VERSION ""

NS_ :

BS_:

BU_: PowertrainControlModule AtmosphericSensor SafetyRestraintSystem2 Aftertreatment_2_GasOutlet Aftertreatment_2_GasIntake DieselParticulateFilterControl Turbocharger SafetyRestraintSystem1 CabDisplay2 Aftertreatment_1_GasOutlet Aftertreatment_1_GasIntake OnBoardDataLogger OffBoardDiagnosticTool2 OffBoardDiagnosticTool1 FileServer ParkingBrakeController SeatController2 FanDriveController SteeringColumnUnit CommunicationUnitRadio CommunicationUnitSatellite CommunicationUnitCellular PropulsionBatteryCharger ChassisController2 ChassisController1 EngineValveControl AuxiliaryHeater2 AuxiliaryHeater1 ClutchUnit RampControl InformationSystem1 SuspensionSystemController2 OilSensor VehicleDynamicStability ExhaustEmissionController TransmissionDisplay2 TransmissionDisplay1 ClimateControl2 WaterPumpController RearAxleSteeringController LightingOperatorControl SeatController1 IgnitionController2 IgnitionController1 TirePressureController CabController2 CabController1 PneumaticSystemController SuspensionSystemController1 HydraulicPumpController EnduranceBrakingSystem RetarderExhaustEngine2 OnBoardDiagnosticUnit HeadwayController RetarderExhaustEngine1 CabDisplay1 ManagementComputer VirtualTerminal OffVehicleGateway PowerTakeOffFront HitchControl AuxiliaryValveControl BodyController TractorTrailerBridge1 StarterSystem ElectricalSystem VehicleSecurity VehicleNavigation AerodynamicControl ElectricalChargingSystem ClimateControl1 TripRecorder InstrumentCluster SuspensionDriveAxle2 SuspensionDriveAxle1 SuspensionSteerAxle SteeringController FuelSystem CruiseControl RetarderDriveline RetarderEngine BrakesDriveAxle2 BrakesDriveAxle1 BrakesSystemController BrakesSteerAxle AxleDrive2 AxleDrive1 AxleSteering PowerTakeOff ShiftConsoleSecondary ShiftConsolePrimary Transmission2 Transmission1 Engine2 Engine1

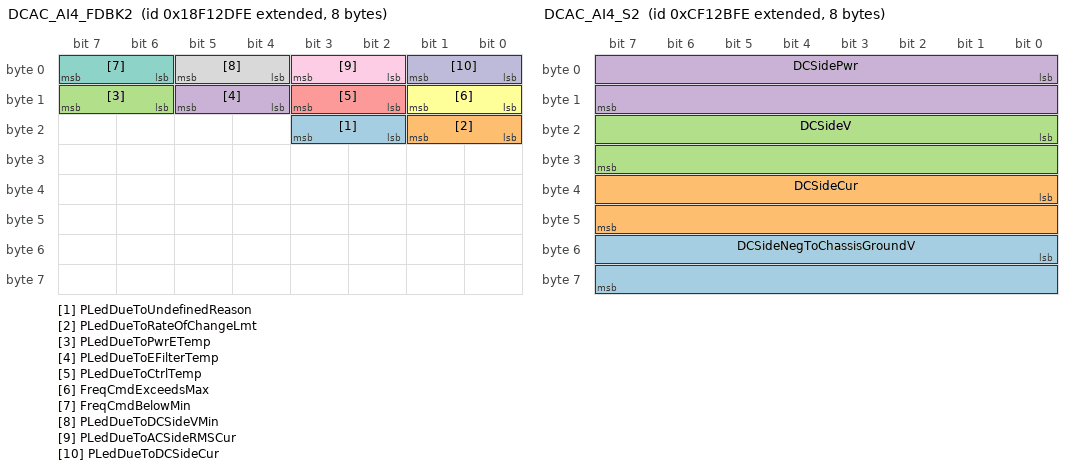
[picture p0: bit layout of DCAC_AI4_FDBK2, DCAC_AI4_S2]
BO_ 2565942782 DCAC_AI4_FDBK2: 8 Vector__XXX
 SG_ PLedDueToUndefinedReason : 18|2@1+ (1,0) [0|3] "" Vector__XXX
 SG_ PLedDueToRateOfChangeLmt : 16|2@1+ (1,0) [0|3] "" Vector__XXX
 SG_ PLedDueToPwrETemp : 14|2@1+ (1,0) [0|3] "" Vector__XXX
 SG_ PLedDueToEFilterTemp : 12|2@1+ (1,0) [0|3] "" Vector__XXX
 SG_ PLedDueToCtrlTemp : 10|2@1+ (1,0) [0|3] "" Vector__XXX
 SG_ FreqCmdExceedsMax : 8|2@1+ (1,0) [0|3] "" Vector__XXX
 SG_ FreqCmdBelowMin : 6|2@1+ (1,0) [0|3] "" Vector__XXX
 SG_ PLedDueToDCSideVMin : 4|2@1+ (1,0) [0|3] "" Vector__XXX
 SG_ PLedDueToACSideRMSCur : 2|2@1+ (1,0) [0|3] "" Vector__XXX
 SG_ PLedDueToDCSideCur : 0|2@1+ (1,0) [0|3] "" Vector__XXX

BO_ 2364615934 DCAC_AI4_V: 8 Vector__XXX
 SG_ SLIV : 16|16@1+ (0.05,0) [0|3212.75] "V" Vector__XXX
 SG_ IgntV : 0|16@1+ (0.05,0) [0|3212.75] "V" Vector__XXX

BO_ 2364615678 DCAC_AI4_S2: 8 Vector__XXX
 SG_ DCSideNegToChassisGroundV : 48|16@1+ (0.05,0) [0|3212.75] "V" Vector__XXX
 SG_ DCSideCur : 32|16@1+ (0.0625,0) [0|4015.9375] "A" Vector__XXX
 SG_ DCSideV : 16|16@1+ (0.05,0) [0|3212.75] "V" Vector__XXX
 SG_ DCSidePwr : 0|16@1+ (0.0625,0) [0|4015.9375] "kW" Vector__XXX

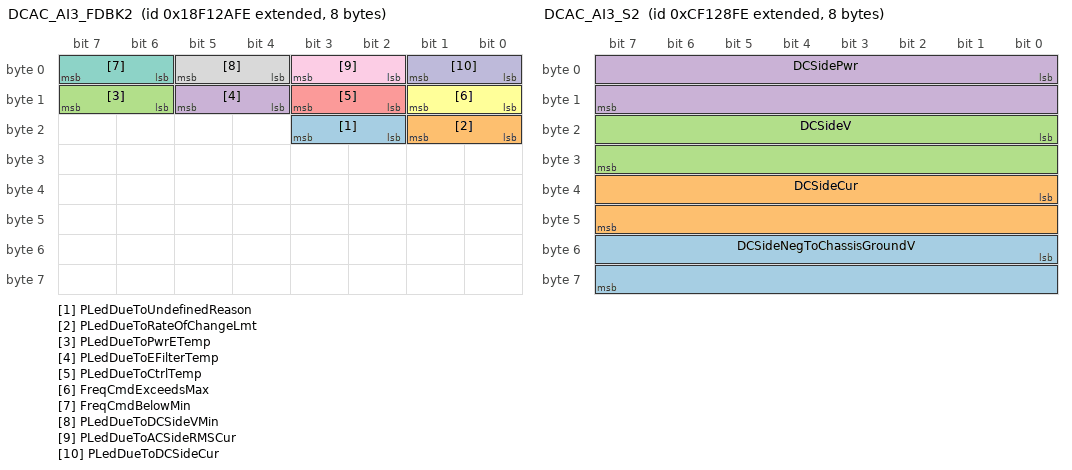
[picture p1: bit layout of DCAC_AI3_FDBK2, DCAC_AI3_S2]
BO_ 2565942014 DCAC_AI3_FDBK2: 8 Vector__XXX
 SG_ PLedDueToUndefinedReason : 18|2@1+ (1,0) [0|3] "" Vector__XXX
 SG_ PLedDueToRateOfChangeLmt : 16|2@1+ (1,0) [0|3] "" Vector__XXX
 SG_ PLedDueToPwrETemp : 14|2@1+ (1,0) [0|3] "" Vector__XXX
 SG_ PLedDueToEFilterTemp : 12|2@1+ (1,0) [0|3] "" Vector__XXX
 SG_ PLedDueToCtrlTemp : 10|2@1+ (1,0) [0|3] "" Vector__XXX
 SG_ FreqCmdExceedsMax : 8|2@1+ (1,0) [0|3] "" Vector__XXX
 SG_ FreqCmdBelowMin : 6|2@1+ (1,0) [0|3] "" Vector__XXX
 SG_ PLedDueToDCSideVMin : 4|2@1+ (1,0) [0|3] "" Vector__XXX
 SG_ PLedDueToACSideRMSCur : 2|2@1+ (1,0) [0|3] "" Vector__XXX
 SG_ PLedDueToDCSideCur : 0|2@1+ (1,0) [0|3] "" Vector__XXX

BO_ 2364615166 DCAC_AI3_V: 8 Vector__XXX
 SG_ SLIV : 16|16@1+ (0.05,0) [0|3212.75] "V" Vector__XXX
 SG_ IgntV : 0|16@1+ (0.05,0) [0|3212.75] "V" Vector__XXX

BO_ 2364614910 DCAC_AI3_S2: 8 Vector__XXX
 SG_ DCSideNegToChassisGroundV : 48|16@1+ (0.05,0) [0|3212.75] "V" Vector__XXX
 SG_ DCSideCur : 32|16@1+ (0.0625,0) [0|4015.9375] "A" Vector__XXX
 SG_ DCSideV : 16|16@1+ (0.05,0) [0|3212.75] "V" Vector__XXX
 SG_ DCSidePwr : 0|16@1+ (0.0625,0) [0|4015.9375] "kW" Vector__XXX

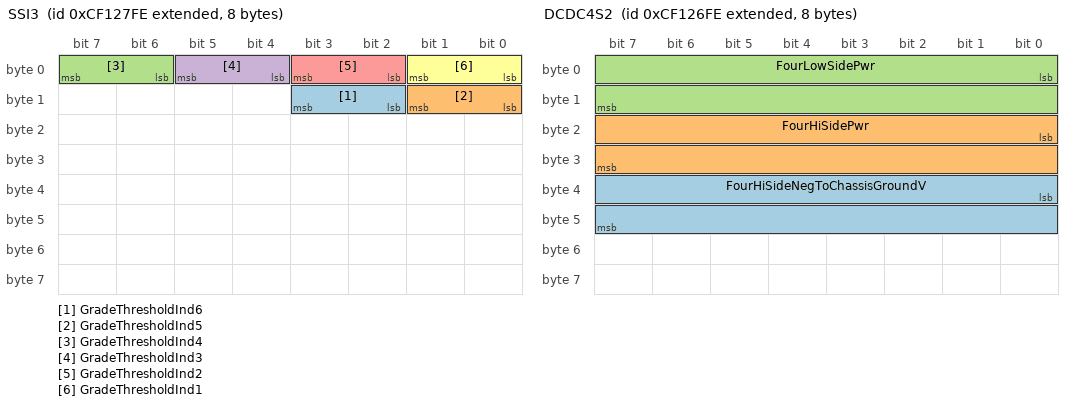
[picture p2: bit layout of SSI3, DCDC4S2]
BO_ 2364614654 SSI3: 8 Vector__XXX
 SG_ GradeThresholdInd6 : 10|2@1+ (1,0) [0|3] "" Vector__XXX
 SG_ GradeThresholdInd5 : 8|2@1+ (1,0) [0|3] "" Vector__XXX
 SG_ GradeThresholdInd4 : 6|2@1+ (1,0) [0|3] "" Vector__XXX
 SG_ GradeThresholdInd3 : 4|2@1+ (1,0) [0|3] "" Vector__XXX
 SG_ GradeThresholdInd2 : 2|2@1+ (1,0) [0|3] "" Vector__XXX
 SG_ GradeThresholdInd1 : 0|2@1+ (1,0) [0|3] "" Vector__XXX

BO_ 2364614398 DCDC4S2: 8 Vector__XXX
 SG_ FourHiSideNegToChassisGroundV : 32|16@1+ (0.05,0) [0|3212.75] "V" Vector__XXX
 SG_ FourHiSidePwr : 16|16@1+ (0.05,-1600) [-1600|1612.75] "kW" Vector__XXX
 SG_ FourLowSidePwr : 0|16@1+ (0.05,-1600) [-1600|1612.75] "kW" Vector__XXX

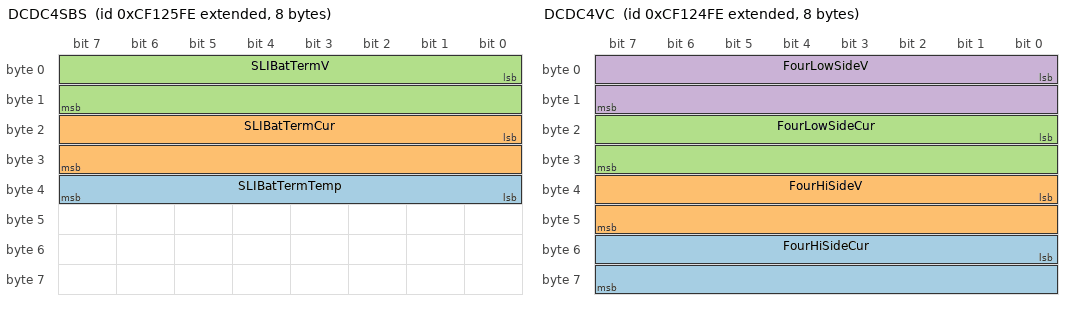
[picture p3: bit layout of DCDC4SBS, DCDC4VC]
BO_ 2364614142 DCDC4SBS: 8 Vector__XXX
 SG_ SLIBatTermTemp : 32|8@1+ (1,-40) [-40|210] "캜" Vector__XXX
 SG_ SLIBatTermCur : 16|16@1+ (0.1,-3212.7) [-3212.7|3212.8] "A" Vector__XXX
 SG_ SLIBatTermV : 0|16@1+ (0.01,0) [0|642.55] "V" Vector__XXX

BO_ 2364613886 DCDC4VC: 8 Vector__XXX
 SG_ FourHiSideCur : 48|16@1+ (0.1,-3212.7) [-3212.7|3212.8] "A" Vector__XXX
 SG_ FourHiSideV : 32|16@1+ (0.05,0) [0|3212.75] "V" Vector__XXX
 SG_ FourLowSideCur : 16|16@1+ (0.1,-3212.7) [-3212.7|3212.8] "A" Vector__XXX
 SG_ FourLowSideV : 0|16@1+ (0.01,0) [0|642.55] "V" Vector__XXX

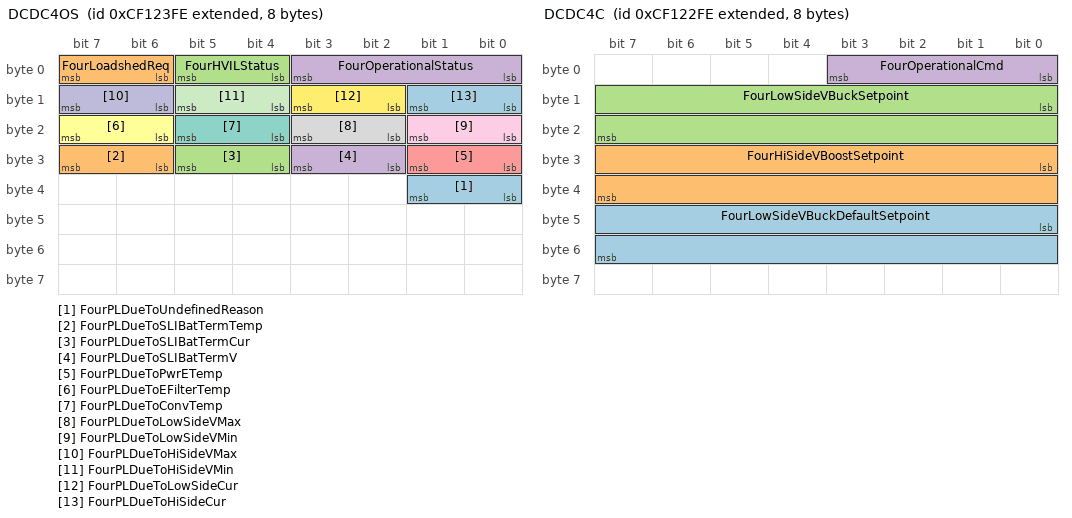
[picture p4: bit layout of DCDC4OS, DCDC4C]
BO_ 2364613630 DCDC4OS: 8 Vector__XXX
 SG_ FourPLDueToUndefinedReason : 32|2@1+ (1,0) [0|3] "" Vector__XXX
 SG_ FourPLDueToSLIBatTermTemp : 30|2@1+ (1,0) [0|3] "" Vector__XXX
 SG_ FourPLDueToSLIBatTermCur : 28|2@1+ (1,0) [0|3] "" Vector__XXX
 SG_ FourPLDueToSLIBatTermV : 26|2@1+ (1,0) [0|3] "" Vector__XXX
 SG_ FourPLDueToPwrETemp : 24|2@1+ (1,0) [0|3] "" Vector__XXX
 SG_ FourPLDueToEFilterTemp : 22|2@1+ (1,0) [0|3] "" Vector__XXX
 SG_ FourPLDueToConvTemp : 20|2@1+ (1,0) [0|3] "" Vector__XXX
 SG_ FourPLDueToLowSideVMax : 18|2@1+ (1,0) [0|3] "" Vector__XXX
 SG_ FourPLDueToLowSideVMin : 16|2@1+ (1,0) [0|3] "" Vector__XXX
 SG_ FourPLDueToHiSideVMax : 14|2@1+ (1,0) [0|3] "" Vector__XXX
 SG_ FourPLDueToHiSideVMin : 12|2@1+ (1,0) [0|3] "" Vector__XXX
 SG_ FourPLDueToLowSideCur : 10|2@1+ (1,0) [0|3] "" Vector__XXX
 SG_ FourPLDueToHiSideCur : 8|2@1+ (1,0) [0|3] "" Vector__XXX
 SG_ FourLoadshedReq : 6|2@1+ (1,0) [0|3] "" Vector__XXX
 SG_ FourHVILStatus : 4|2@1+ (1,0) [0|3] "" Vector__XXX
 SG_ FourOperationalStatus : 0|4@1+ (1,0) [0|15] "" Vector__XXX

BO_ 2364613374 DCDC4C: 8 Vector__XXX
 SG_ FourLowSideVBuckDefaultSetpoint : 40|16@1+ (0.01,0) [0|642.55] "V" Vector__XXX
 SG_ FourHiSideVBoostSetpoint : 24|16@1+ (0.05,0) [0|3212.75] "V" Vector__XXX
 SG_ FourLowSideVBuckSetpoint : 8|16@1+ (0.01,0) [0|642.55] "V" Vector__XXX
 SG_ FourOperationalCmd : 0|4@1+ (1,0) [0|15] "" Vector__XXX

BO_ 2364613118 DCDC3S2: 8 Vector__XXX
 SG_ ThreeHiSideNegToChassisGroundV : 32|16@1+ (0.05,0) [0|3212.75] "V" Vector__XXX
 SG_ ThreeHiSidePwr : 16|16@1+ (0.05,-1600) [-1600|1612.75] "kW" Vector__XXX
 SG_ ThreeLowSidePwr : 0|16@1+ (0.05,-1600) [-1600|1612.75] "kW" Vector__XXX

BO_ 2364612862 DCDC3SBS: 8 Vector__XXX
 SG_ SLIBatTermTemp : 32|8@1+ (1,-40) [-40|210] "캜" Vector__XXX
 SG_ SLIBatTermCur : 16|16@1+ (0.1,-3212.7) [-3212.7|3212.8] "A" Vector__XXX
 SG_ SLIBatTermV : 0|16@1+ (0.01,0) [0|642.55] "V" Vector__XXX

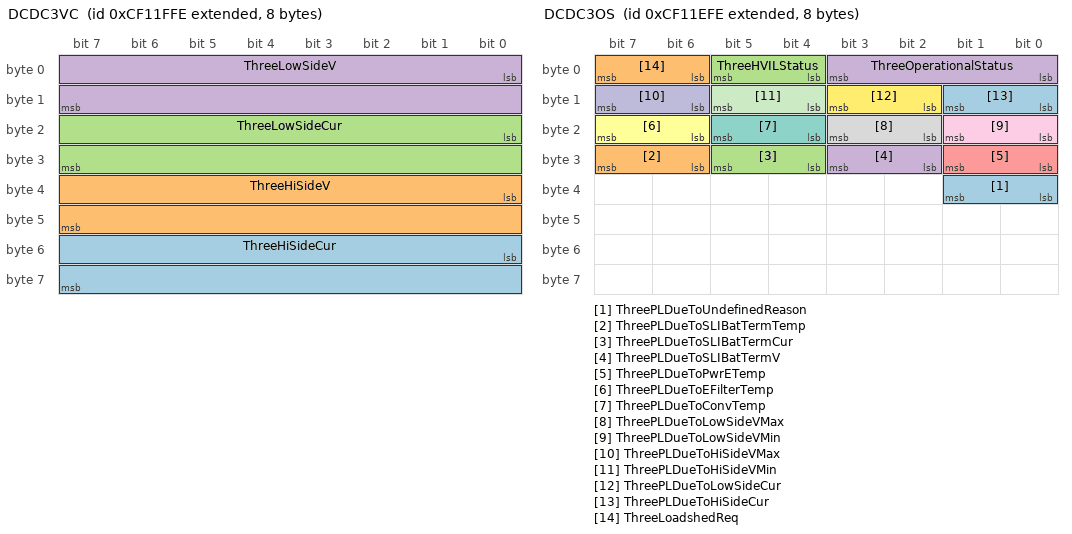
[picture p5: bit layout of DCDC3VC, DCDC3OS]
BO_ 2364612606 DCDC3VC: 8 Vector__XXX
 SG_ ThreeHiSideCur : 48|16@1+ (0.1,-3212.7) [-3212.7|3212.8] "A" Vector__XXX
 SG_ ThreeHiSideV : 32|16@1+ (0.05,0) [0|3212.75] "V" Vector__XXX
 SG_ ThreeLowSideCur : 16|16@1+ (0.1,-3212.7) [-3212.7|3212.8] "A" Vector__XXX
 SG_ ThreeLowSideV : 0|16@1+ (0.01,0) [0|642.55] "V" Vector__XXX

BO_ 2364612350 DCDC3OS: 8 Vector__XXX
 SG_ ThreePLDueToUndefinedReason : 32|2@1+ (1,0) [0|3] "" Vector__XXX
 SG_ ThreePLDueToSLIBatTermTemp : 30|2@1+ (1,0) [0|3] "" Vector__XXX
 SG_ ThreePLDueToSLIBatTermCur : 28|2@1+ (1,0) [0|3] "" Vector__XXX
 SG_ ThreePLDueToSLIBatTermV : 26|2@1+ (1,0) [0|3] "" Vector__XXX
 SG_ ThreePLDueToPwrETemp : 24|2@1+ (1,0) [0|3] "" Vector__XXX
 SG_ ThreePLDueToEFilterTemp : 22|2@1+ (1,0) [0|3] "" Vector__XXX
 SG_ ThreePLDueToConvTemp : 20|2@1+ (1,0) [0|3] "" Vector__XXX
 SG_ ThreePLDueToLowSideVMax : 18|2@1+ (1,0) [0|3] "" Vector__XXX
 SG_ ThreePLDueToLowSideVMin : 16|2@1+ (1,0) [0|3] "" Vector__XXX
 SG_ ThreePLDueToHiSideVMax : 14|2@1+ (1,0) [0|3] "" Vector__XXX
 SG_ ThreePLDueToHiSideVMin : 12|2@1+ (1,0) [0|3] "" Vector__XXX
 SG_ ThreePLDueToLowSideCur : 10|2@1+ (1,0) [0|3] "" Vector__XXX
 SG_ ThreePLDueToHiSideCur : 8|2@1+ (1,0) [0|3] "" Vector__XXX
 SG_ ThreeLoadshedReq : 6|2@1+ (1,0) [0|3] "" Vector__XXX
 SG_ ThreeHVILStatus : 4|2@1+ (1,0) [0|3] "" Vector__XXX
 SG_ ThreeOperationalStatus : 0|4@1+ (1,0) [0|15] "" Vector__XXX

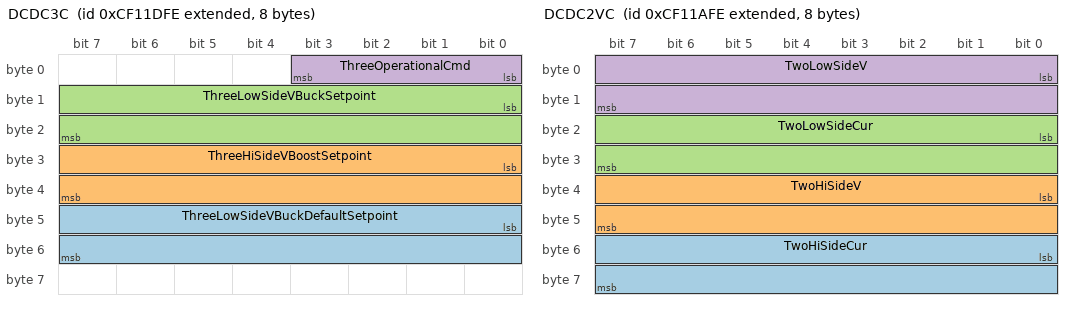
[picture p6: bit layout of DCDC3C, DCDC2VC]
BO_ 2364612094 DCDC3C: 8 Vector__XXX
 SG_ ThreeLowSideVBuckDefaultSetpoint : 40|16@1+ (0.01,0) [0|642.55] "V" Vector__XXX
 SG_ ThreeHiSideVBoostSetpoint : 24|16@1+ (0.05,0) [0|3212.75] "V" Vector__XXX
 SG_ ThreeLowSideVBuckSetpoint : 8|16@1+ (0.01,0) [0|642.55] "V" Vector__XXX
 SG_ ThreeOperationalCmd : 0|4@1+ (1,0) [0|15] "" Vector__XXX

BO_ 2364611838 DCDC2S2: 8 Vector__XXX
 SG_ TwoHiSideNegToChassisGroundV : 32|16@1+ (0.05,0) [0|3212.75] "V" Vector__XXX
 SG_ TwoHiSidePwr : 16|16@1+ (0.05,-1600) [-1600|1612.75] "kW" Vector__XXX
 SG_ TwoLowSidePwr : 0|16@1+ (0.05,-1600) [-1600|1612.75] "kW" Vector__XXX

BO_ 2364611582 DCDC2SBS: 8 Vector__XXX
 SG_ SLIBatTermTemp : 32|8@1+ (1,-40) [-40|210] "캜" Vector__XXX
 SG_ SLIBatTermCur : 16|16@1+ (0.1,-3212.7) [-3212.7|3212.8] "A" Vector__XXX
 SG_ SLIBatTermV : 0|16@1+ (0.01,0) [0|642.55] "V" Vector__XXX

BO_ 2364611326 DCDC2VC: 8 Vector__XXX
 SG_ TwoHiSideCur : 48|16@1+ (0.1,-3212.7) [-3212.7|3212.8] "A" Vector__XXX
 SG_ TwoHiSideV : 32|16@1+ (0.05,0) [0|3212.75] "V" Vector__XXX
 SG_ TwoLowSideCur : 16|16@1+ (0.1,-3212.7) [-3212.7|3212.8] "A" Vector__XXX
 SG_ TwoLowSideV : 0|16@1+ (0.01,0) [0|642.55] "V" Vector__XXX

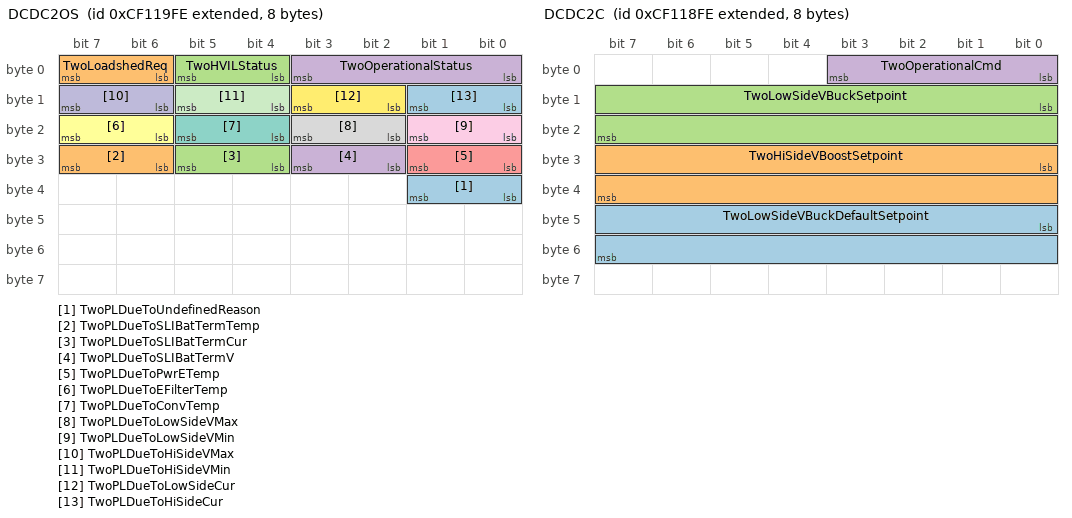
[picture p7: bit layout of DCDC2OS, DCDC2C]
BO_ 2364611070 DCDC2OS: 8 Vector__XXX
 SG_ TwoPLDueToUndefinedReason : 32|2@1+ (1,0) [0|3] "" Vector__XXX
 SG_ TwoPLDueToSLIBatTermTemp : 30|2@1+ (1,0) [0|3] "" Vector__XXX
 SG_ TwoPLDueToSLIBatTermCur : 28|2@1+ (1,0) [0|3] "" Vector__XXX
 SG_ TwoPLDueToSLIBatTermV : 26|2@1+ (1,0) [0|3] "" Vector__XXX
 SG_ TwoPLDueToPwrETemp : 24|2@1+ (1,0) [0|3] "" Vector__XXX
 SG_ TwoPLDueToEFilterTemp : 22|2@1+ (1,0) [0|3] "" Vector__XXX
 SG_ TwoPLDueToConvTemp : 20|2@1+ (1,0) [0|3] "" Vector__XXX
 SG_ TwoPLDueToLowSideVMax : 18|2@1+ (1,0) [0|3] "" Vector__XXX
 SG_ TwoPLDueToLowSideVMin : 16|2@1+ (1,0) [0|3] "" Vector__XXX
 SG_ TwoPLDueToHiSideVMax : 14|2@1+ (1,0) [0|3] "" Vector__XXX
 SG_ TwoPLDueToHiSideVMin : 12|2@1+ (1,0) [0|3] "" Vector__XXX
 SG_ TwoPLDueToLowSideCur : 10|2@1+ (1,0) [0|3] "" Vector__XXX
 SG_ TwoPLDueToHiSideCur : 8|2@1+ (1,0) [0|3] "" Vector__XXX
 SG_ TwoLoadshedReq : 6|2@1+ (1,0) [0|3] "" Vector__XXX
 SG_ TwoHVILStatus : 4|2@1+ (1,0) [0|3] "" Vector__XXX
 SG_ TwoOperationalStatus : 0|4@1+ (1,0) [0|15] "" Vector__XXX

BO_ 2364610814 DCDC2C: 8 Vector__XXX
 SG_ TwoLowSideVBuckDefaultSetpoint : 40|16@1+ (0.01,0) [0|642.55] "V" Vector__XXX
 SG_ TwoHiSideVBoostSetpoint : 24|16@1+ (0.05,0) [0|3212.75] "V" Vector__XXX
 SG_ TwoLowSideVBuckSetpoint : 8|16@1+ (0.01,0) [0|642.55] "V" Vector__XXX
 SG_ TwoOperationalCmd : 0|4@1+ (1,0) [0|15] "" Vector__XXX

BO_ 2364610558 DCDC1S2: 8 Vector__XXX
 SG_ OneHiSideNegToChassisGroundV : 32|16@1+ (0.05,0) [0|3212.75] "V" Vector__XXX
 SG_ OneHiSidePwr : 16|16@1+ (0.05,-1600) [-1600|1612.75] "kW" Vector__XXX
 SG_ OneLowSidePwr : 0|16@1+ (0.05,-1600) [-1600|1612.75] "kW" Vector__XXX

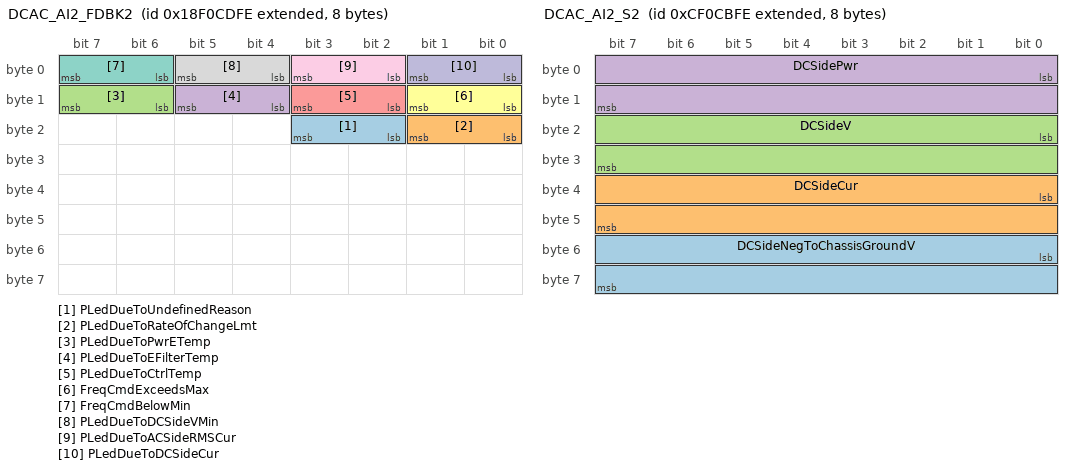
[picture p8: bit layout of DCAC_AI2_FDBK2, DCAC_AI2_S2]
BO_ 2565918206 DCAC_AI2_FDBK2: 8 Vector__XXX
 SG_ PLedDueToUndefinedReason : 18|2@1+ (1,0) [0|3] "" Vector__XXX
 SG_ PLedDueToRateOfChangeLmt : 16|2@1+ (1,0) [0|3] "" Vector__XXX
 SG_ PLedDueToPwrETemp : 14|2@1+ (1,0) [0|3] "" Vector__XXX
 SG_ PLedDueToEFilterTemp : 12|2@1+ (1,0) [0|3] "" Vector__XXX
 SG_ PLedDueToCtrlTemp : 10|2@1+ (1,0) [0|3] "" Vector__XXX
 SG_ FreqCmdExceedsMax : 8|2@1+ (1,0) [0|3] "" Vector__XXX
 SG_ FreqCmdBelowMin : 6|2@1+ (1,0) [0|3] "" Vector__XXX
 SG_ PLedDueToDCSideVMin : 4|2@1+ (1,0) [0|3] "" Vector__XXX
 SG_ PLedDueToACSideRMSCur : 2|2@1+ (1,0) [0|3] "" Vector__XXX
 SG_ PLedDueToDCSideCur : 0|2@1+ (1,0) [0|3] "" Vector__XXX

BO_ 2364591358 DCAC_AI2_V: 8 Vector__XXX
 SG_ SLIV : 16|16@1+ (0.05,0) [0|3212.75] "V" Vector__XXX
 SG_ IgntV : 0|16@1+ (0.05,0) [0|3212.75] "V" Vector__XXX

BO_ 2364591102 DCAC_AI2_S2: 8 Vector__XXX
 SG_ DCSideNegToChassisGroundV : 48|16@1+ (0.05,0) [0|3212.75] "V" Vector__XXX
 SG_ DCSideCur : 32|16@1+ (0.0625,0) [0|4015.9375] "A" Vector__XXX
 SG_ DCSideV : 16|16@1+ (0.05,0) [0|3212.75] "V" Vector__XXX
 SG_ DCSidePwr : 0|16@1+ (0.0625,0) [0|4015.9375] "kW" Vector__XXX

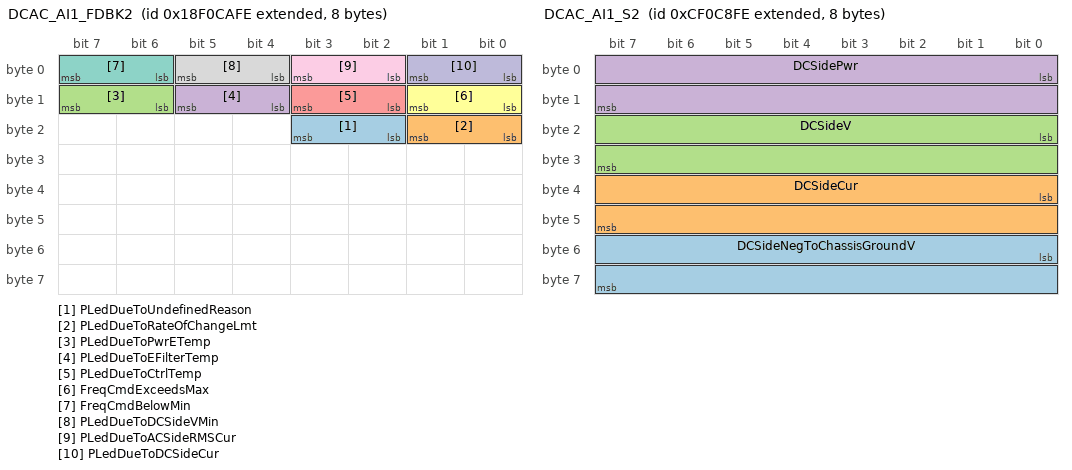
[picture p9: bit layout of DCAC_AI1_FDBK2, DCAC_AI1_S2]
BO_ 2565917438 DCAC_AI1_FDBK2: 8 Vector__XXX
 SG_ PLedDueToUndefinedReason : 18|2@1+ (1,0) [0|3] "" Vector__XXX
 SG_ PLedDueToRateOfChangeLmt : 16|2@1+ (1,0) [0|3] "" Vector__XXX
 SG_ PLedDueToPwrETemp : 14|2@1+ (1,0) [0|3] "" Vector__XXX
 SG_ PLedDueToEFilterTemp : 12|2@1+ (1,0) [0|3] "" Vector__XXX
 SG_ PLedDueToCtrlTemp : 10|2@1+ (1,0) [0|3] "" Vector__XXX
 SG_ FreqCmdExceedsMax : 8|2@1+ (1,0) [0|3] "" Vector__XXX
 SG_ FreqCmdBelowMin : 6|2@1+ (1,0) [0|3] "" Vector__XXX
 SG_ PLedDueToDCSideVMin : 4|2@1+ (1,0) [0|3] "" Vector__XXX
 SG_ PLedDueToACSideRMSCur : 2|2@1+ (1,0) [0|3] "" Vector__XXX
 SG_ PLedDueToDCSideCur : 0|2@1+ (1,0) [0|3] "" Vector__XXX

BO_ 2364590590 DCAC_AI1_V: 8 Vector__XXX
 SG_ SLIV : 16|16@1+ (0.05,0) [0|3212.75] "V" Vector__XXX
 SG_ IgntV : 0|16@1+ (0.05,0) [0|3212.75] "V" Vector__XXX

BO_ 2364590334 DCAC_AI1_S2: 8 Vector__XXX
 SG_ DCSideNegToChassisGroundV : 48|16@1+ (0.05,0) [0|3212.75] "V" Vector__XXX
 SG_ DCSideCur : 32|16@1+ (0.0625,0) [0|4015.9375] "A" Vector__XXX
 SG_ DCSideV : 16|16@1+ (0.05,0) [0|3212.75] "V" Vector__XXX
 SG_ DCSidePwr : 0|16@1+ (0.0625,0) [0|4015.9375] "kW" Vector__XXX

BO_ 2624519934 CRSC: 8 Vector__XXX
 SG_ CommandedReceiveSPNSA : 40|8@1+ (1,0) [0|255] "" Vector__XXX
 SG_ CommandedReceiveSPNReqSt : 32|2@1+ (1,0) [0|3] "" Vector__XXX
 SG_ CommandedReceiveSPN : 16|19@1+ (1,0) [0|524287] "" Vector__XXX
 SG_ TransactionMode : 4|4@1+ (1,0) [0|15] "" Vector__XXX
 SG_ CommandedPort : 0|4@1+ (1,0) [0|15] "" Vector__XXX

BO_ 2557345534 WSPT1: 19 Vector__XXX
 SG_ PlungerFiringOrder : 144|4@1+ (1,0) [0|15] "" Vector__XXX
 SG_ RodLoadHiThreshold : 128|16@1+ (5,0) [0|321275] "kN" Vector__XXX
 SG_ CrankshaftSpdHiThreshold : 112|16@1+ (0.125,0) [0|8031.875] "rpm" Vector__XXX
 SG_ CrankshaftSpdLowThreshold : 96|16@1+ (0.125,0) [0|8031.875] "rpm" Vector__XXX
 SG_ DisPressHiThreshold : 80|16@1+ (5,0) [0|321275] "kPa" Vector__XXX
 SG_ SuctionPressHiThreshold : 64|16@1+ (0.1,-3212.7) [-3212.7|3212.8] "kPa" Vector__XXX
 SG_ SuctionPressLowThreshold : 48|16@1+ (0.1,-3212.7) [-3212.7|3212.8] "kPa" Vector__XXX
 SG_ GearBoxOilTempHiThreshold : 40|8@1+ (1,-40) [-40|210] "캜" Vector__XXX
 SG_ GearBoxOilTempLowThreshold : 32|8@1+ (1,-40) [-40|210] "캜" Vector__XXX
 SG_ GearBoxOilPressHiThreshold : 16|16@1+ (0.1,0) [0|6425.5] "kPa" Vector__XXX
 SG_ GearBoxOilPressLowThreshold : 0|16@1+ (0.1,0) [0|6425.5] "kPa" Vector__XXX

BO_ 2557214462 WSPSCC: 8 Vector__XXX
 SG_ DisPressCalSetPointCmd : 8|4@1+ (1,0) [0|15] "" Vector__XXX
 SG_ SuctionPressCalSetPointCmd : 0|4@1+ (1,0) [0|15] "" Vector__XXX

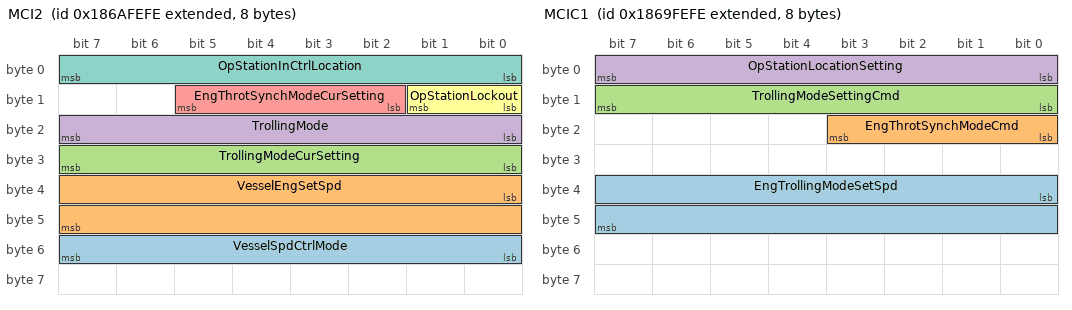
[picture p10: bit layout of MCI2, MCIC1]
BO_ 2557148926 MCI2: 8 Vector__XXX
 SG_ VesselSpdCtrlMode : 48|8@1+ (1,0) [0|255] "" Vector__XXX
 SG_ VesselEngSetSpd : 32|16@1+ (0.125,0) [0|8031.875] "rpm" Vector__XXX
 SG_ TrollingModeCurSetting : 24|8@1+ (1,0) [0|255] "" Vector__XXX
 SG_ TrollingMode : 16|8@1+ (1,0) [0|255] "" Vector__XXX
 SG_ EngThrotSynchModeCurSetting : 10|4@1+ (1,0) [0|15] "" Vector__XXX
 SG_ OpStationLockout : 8|2@1+ (1,0) [0|3] "" Vector__XXX
 SG_ OpStationInCtrlLocation : 0|8@1+ (1,0) [0|250] "" Vector__XXX

BO_ 2557083390 MCIC1: 8 Vector__XXX
 SG_ EngTrollingModeSetSpd : 32|16@1+ (0.125,0) [0|8031.875] "rpm" Vector__XXX
 SG_ EngThrotSynchModeCmd : 16|4@1+ (1,0) [0|15] "" Vector__XXX
 SG_ TrollingModeSettingCmd : 8|8@1+ (1,0) [0|255] "" Vector__XXX
 SG_ OpStationLocationSetting : 0|8@1+ (1,0) [0|250] "" Vector__XXX

BO_ 2633785086 HVES1HIST: 8 Vector__XXX
 SG_ TotalAccumulatedCharge : 56|32@1+ (100,0) [0|421108121500] "Ah" Vector__XXX
 SG_ TotalEnergyThroughput : 24|32@1+ (100,0) [0|421108121500] "Watt-hour" Vector__XXX
 SG_ ContactorOpenUnderLoadCount : 8|16@1+ (1,0) [0|64255] "" Vector__XXX
 SG_ StOfHealth : 0|8@1+ (0.4,0) [0|100] "%" Vector__XXX

BO_ 2566675966 HVES1CFG: 8 Vector__XXX
 SG_ CellMinVLmt : 120|8@1+ (0.02044,0) [0|5.11] "V" Vector__XXX
 SG_ CellMaxVLmt : 112|8@1+ (0.02044,0) [0|5.11] "V" Vector__XXX
 SG_ RecommendedMinOperatingTemp : 96|16@1+ (0.03125,-273) [-273|1734.96875] "캜" Vector__XXX
 SG_ RecommendedMaxOperatingTemp : 80|16@1+ (0.03125,-273) [-273|1734.96875] "캜" Vector__XXX
 SG_ RecommendedMaxStOfCharge : 64|16@1+ (0.0015625,0) [0|100.3984375] "%" Vector__XXX
 SG_ RecommendedMinStOfCharge : 48|16@1+ (0.0015625,0) [0|100.3984375] "%" Vector__XXX
 SG_ RecommendedMaxOperatingV : 32|16@1+ (0.05,0) [0|3212.75] "V" Vector__XXX
 SG_ RecommendedMinOperatingV : 16|16@1+ (0.05,0) [0|3212.75] "V" Vector__XXX
 SG_ NominalV : 0|16@1+ (0.05,0) [0|3212.75] "V" Vector__XXX

BO_ 2566661886 A2DEFI2: 8 Vector__XXX
 SG_ Ctrl2Temp : 8|8@1+ (1,-40) [-40|210] "캜" Vector__XXX
 SG_ CtrlTemp : 0|8@1+ (1,-40) [-40|210] "캜" Vector__XXX

BO_ 2566656254 AMB3: 8 Vector__XXX
 SG_ EngIn2AirTemp : 16|8@1+ (1,-40) [-40|210] "캜" Vector__XXX
 SG_ BarometricAbsPress2 : 0|16@1+ (0.1,0) [0|6425.5] "kPa" Vector__XXX

BO_ 2566655998 SHRPS: 8 Vector__XXX
 SG_ PitchSensitivity : 8|8@1+ (0.4,0) [0|100] "%" Vector__XXX
 SG_ Sensitivity : 0|8@1+ (0.4,0) [0|100] "%" Vector__XXX

BO_ 2566655742 PHRPS: 8 Vector__XXX
 SG_ PitchSensitivity : 8|8@1+ (0.4,0) [0|100] "%" Vector__XXX
 SG_ Sensitivity : 0|8@1+ (0.4,0) [0|100] "%" Vector__XXX

BO_ 2633764350 FPS1: 8 Vector__XXX
 SG_ EngagementCycles : 32|16@1+ (1,0) [0|64255] "" Vector__XXX
 SG_ OpTime : 0|32@1+ (1,0) [0|4211081215] "s" Vector__XXX

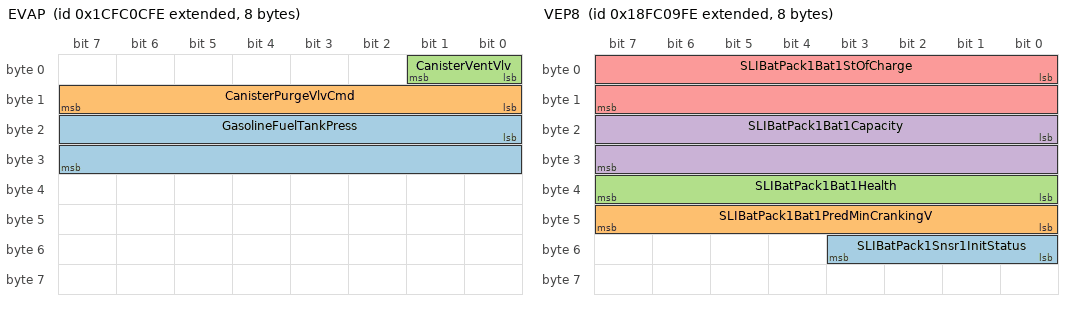
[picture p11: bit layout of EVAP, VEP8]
BO_ 2633764094 EVAP: 8 Vector__XXX
 SG_ GasolineFuelTankPress : 16|16@1+ (0.1,-3212.7) [-3212.7|3212.8] "kPa" Vector__XXX
 SG_ CanisterPurgeVlvCmd : 8|8@1+ (0.4,0) [0|100] "%" Vector__XXX
 SG_ CanisterVentVlv : 0|2@1+ (1,0) [0|3] "" Vector__XXX

BO_ 2566654974 EEC20: 8 Vector__XXX
 SG_ ActualMaxAvailableEngPercentFuel : 16|8@1+ (0.4,0) [0|100] "%" Vector__XXX
 SG_ EstEngParasiticLossesPercentTrq : 0|16@1+ (0.0015625,0) [0|100.3984375] "%" Vector__XXX

BO_ 2566654718 VEP7: 8 Vector__XXX
 SG_ SLIBatPack1Bat1V : 24|16@1+ (0.05,0) [0|3212.75] "V" Vector__XXX
 SG_ SLIBatPack1Bat1Temp : 16|8@1+ (1,-40) [-40|210] "캜" Vector__XXX
 SG_ SLIBatPack1Bat1NetCur : 0|16@1+ (0.05,-1600) [-1600|1612.75] "A" Vector__XXX

BO_ 2566654462 VEP8: 8 Vector__XXX
 SG_ SLIBatPack1Snsr1InitStatus : 48|4@1+ (1,0) [0|15] "" Vector__XXX
 SG_ SLIBatPack1Bat1PredMinCrankingV : 40|8@1+ (0.2,0) [0|50] "V" Vector__XXX
 SG_ SLIBatPack1Bat1Health : 32|8@1+ (0.5,0) [0|125] "%" Vector__XXX
 SG_ SLIBatPack1Bat1Capacity : 16|16@1+ (1,0) [0|64255] "Ah" Vector__XXX
 SG_ SLIBatPack1Bat1StOfCharge : 0|16@1+ (0.0025,0) [0|160.6375] "%" Vector__XXX

BO_ 2566654206 VEP9: 8 Vector__XXX
 SG_ SLIBatPack1Bat2V : 24|16@1+ (0.05,0) [0|3212.75] "V" Vector__XXX
 SG_ SLIBatPack1Bat2Temp : 16|8@1+ (1,-40) [-40|210] "캜" Vector__XXX
 SG_ SLIBatPack1Bat2NetCur : 0|16@1+ (0.05,-1600) [-1600|1612.75] "A" Vector__XXX

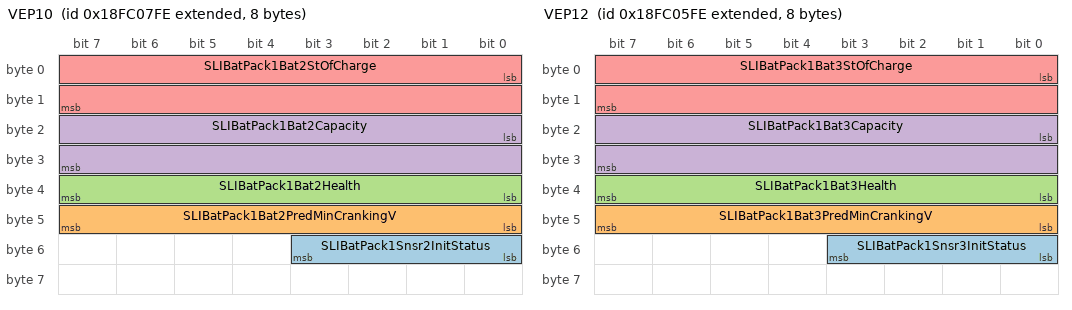
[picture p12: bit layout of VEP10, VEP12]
BO_ 2566653950 VEP10: 8 Vector__XXX
 SG_ SLIBatPack1Snsr2InitStatus : 48|4@1+ (1,0) [0|15] "" Vector__XXX
 SG_ SLIBatPack1Bat2PredMinCrankingV : 40|8@1+ (0.2,0) [0|50] "V" Vector__XXX
 SG_ SLIBatPack1Bat2Health : 32|8@1+ (0.5,0) [0|125] "%" Vector__XXX
 SG_ SLIBatPack1Bat2Capacity : 16|16@1+ (1,0) [0|64255] "Ah" Vector__XXX
 SG_ SLIBatPack1Bat2StOfCharge : 0|16@1+ (0.0025,0) [0|160.6375] "%" Vector__XXX

BO_ 2566653694 VEP11: 8 Vector__XXX
 SG_ SLIBatPack1Bat3V : 24|16@1+ (0.05,0) [0|3212.75] "V" Vector__XXX
 SG_ SLIBatPack1Bat3Temp : 16|8@1+ (1,-40) [-40|210] "캜" Vector__XXX
 SG_ SLIBatPack1Bat3NetCur : 0|16@1+ (0.05,-1600) [-1600|1612.75] "A" Vector__XXX

BO_ 2566653438 VEP12: 8 Vector__XXX
 SG_ SLIBatPack1Snsr3InitStatus : 48|4@1+ (1,0) [0|15] "" Vector__XXX
 SG_ SLIBatPack1Bat3PredMinCrankingV : 40|8@1+ (0.2,0) [0|50] "V" Vector__XXX
 SG_ SLIBatPack1Bat3Health : 32|8@1+ (0.5,0) [0|125] "%" Vector__XXX
 SG_ SLIBatPack1Bat3Capacity : 16|16@1+ (1,0) [0|64255] "Ah" Vector__XXX
 SG_ SLIBatPack1Bat3StOfCharge : 0|16@1+ (0.0025,0) [0|160.6375] "%" Vector__XXX

BO_ 2566653182 VEP13: 8 Vector__XXX
 SG_ SLIBatPack1Bat4V : 24|16@1+ (0.05,0) [0|3212.75] "V" Vector__XXX
 SG_ SLIBatPack1Bat4Temp : 16|8@1+ (1,-40) [-40|210] "캜" Vector__XXX
 SG_ SLIBatPack1Bat4NetCur : 0|16@1+ (0.05,-1600) [-1600|1612.75] "A" Vector__XXX

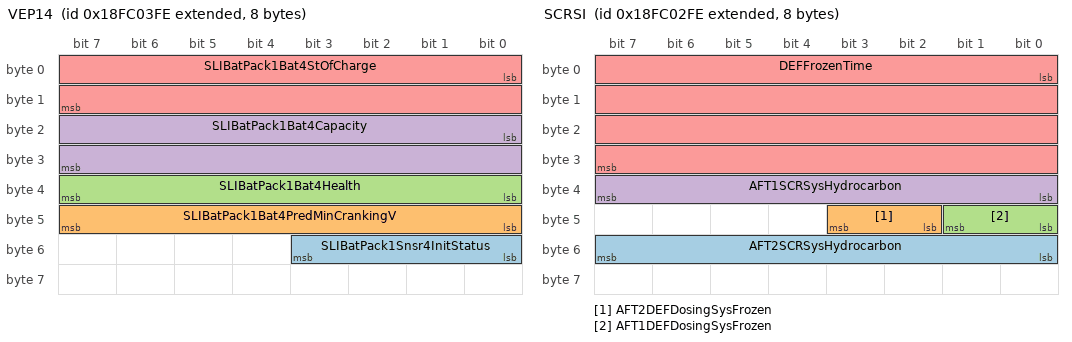
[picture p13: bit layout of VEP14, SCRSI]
BO_ 2566652926 VEP14: 8 Vector__XXX
 SG_ SLIBatPack1Snsr4InitStatus : 48|4@1+ (1,0) [0|15] "" Vector__XXX
 SG_ SLIBatPack1Bat4PredMinCrankingV : 40|8@1+ (0.2,0) [0|50] "V" Vector__XXX
 SG_ SLIBatPack1Bat4Health : 32|8@1+ (0.5,0) [0|125] "%" Vector__XXX
 SG_ SLIBatPack1Bat4Capacity : 16|16@1+ (1,0) [0|64255] "Ah" Vector__XXX
 SG_ SLIBatPack1Bat4StOfCharge : 0|16@1+ (0.0025,0) [0|160.6375] "%" Vector__XXX

BO_ 2566652670 SCRSI: 8 Vector__XXX
 SG_ AFT2SCRSysHydrocarbon : 48|8@1+ (1,0) [0|250] "%" Vector__XXX
 SG_ AFT2DEFDosingSysFrozen : 42|2@1+ (1,0) [0|3] "" Vector__XXX
 SG_ AFT1DEFDosingSysFrozen : 40|2@1+ (1,0) [0|3] "" Vector__XXX
 SG_ AFT1SCRSysHydrocarbon : 32|8@1+ (1,0) [0|250] "%" Vector__XXX
 SG_ DEFFrozenTime : 0|32@1+ (1,0) [0|4211081215] "s" Vector__XXX

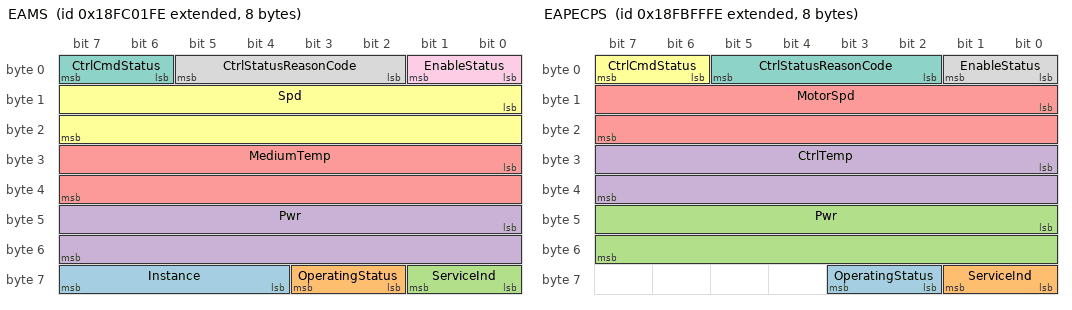
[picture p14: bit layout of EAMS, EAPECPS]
BO_ 2566652414 EAMS: 8 Vector__XXX
 SG_ Instance : 60|4@1+ (1,0) [0|15] "" Vector__XXX
 SG_ OperatingStatus : 58|2@1+ (1,0) [0|3] "" Vector__XXX
 SG_ ServiceInd : 56|2@1+ (1,0) [0|3] "" Vector__XXX
 SG_ Pwr : 40|16@1+ (0.5,0) [0|32127.5] "W" Vector__XXX
 SG_ MediumTemp : 24|16@1+ (0.03125,-273) [-273|1734.96875] "캜" Vector__XXX
 SG_ Spd : 8|16@1+ (0.5,0) [0|32127.5] "rpm" Vector__XXX
 SG_ CtrlCmdStatus : 6|2@1+ (1,0) [0|3] "" Vector__XXX
 SG_ CtrlStatusReasonCode : 2|4@1+ (1,0) [0|15] "" Vector__XXX
 SG_ EnableStatus : 0|2@1+ (1,0) [0|3] "" Vector__XXX

BO_ 2566651902 EAPECPS: 8 Vector__XXX
 SG_ OperatingStatus : 58|2@1+ (1,0) [0|3] "" Vector__XXX
 SG_ ServiceInd : 56|2@1+ (1,0) [0|3] "" Vector__XXX
 SG_ Pwr : 40|16@1+ (0.5,0) [0|32127.5] "W" Vector__XXX
 SG_ CtrlTemp : 24|16@1+ (0.03125,-273) [-273|1734.96875] "캜" Vector__XXX
 SG_ MotorSpd : 8|16@1+ (0.5,0) [0|32127.5] "rpm" Vector__XXX
 SG_ CtrlCmdStatus : 6|2@1+ (1,0) [0|3] "" Vector__XXX
 SG_ CtrlStatusReasonCode : 2|4@1+ (1,0) [0|15] "" Vector__XXX
 SG_ EnableStatus : 0|2@1+ (1,0) [0|3] "" Vector__XXX

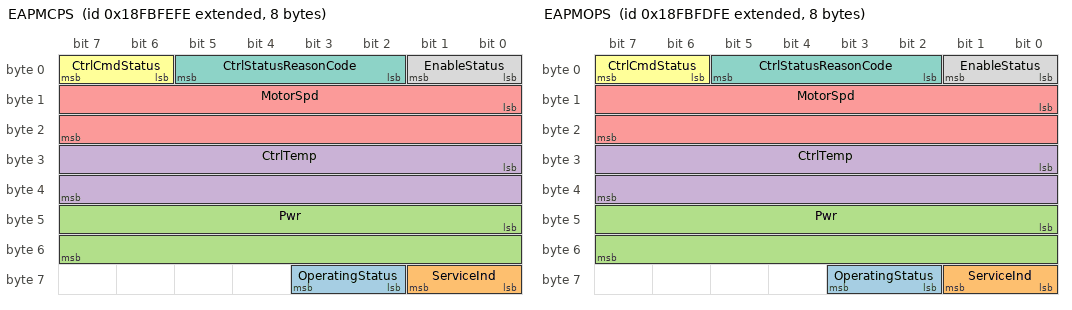
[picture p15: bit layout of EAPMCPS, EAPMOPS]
BO_ 2566651646 EAPMCPS: 8 Vector__XXX
 SG_ OperatingStatus : 58|2@1+ (1,0) [0|3] "" Vector__XXX
 SG_ ServiceInd : 56|2@1+ (1,0) [0|3] "" Vector__XXX
 SG_ Pwr : 40|16@1+ (0.5,0) [0|32127.5] "W" Vector__XXX
 SG_ CtrlTemp : 24|16@1+ (0.03125,-273) [-273|1734.96875] "캜" Vector__XXX
 SG_ MotorSpd : 8|16@1+ (0.5,0) [0|32127.5] "rpm" Vector__XXX
 SG_ CtrlCmdStatus : 6|2@1+ (1,0) [0|3] "" Vector__XXX
 SG_ CtrlStatusReasonCode : 2|4@1+ (1,0) [0|15] "" Vector__XXX
 SG_ EnableStatus : 0|2@1+ (1,0) [0|3] "" Vector__XXX

BO_ 2566651390 EAPMOPS: 8 Vector__XXX
 SG_ OperatingStatus : 58|2@1+ (1,0) [0|3] "" Vector__XXX
 SG_ ServiceInd : 56|2@1+ (1,0) [0|3] "" Vector__XXX
 SG_ Pwr : 40|16@1+ (0.5,0) [0|32127.5] "W" Vector__XXX
 SG_ CtrlTemp : 24|16@1+ (0.03125,-273) [-273|1734.96875] "캜" Vector__XXX
 SG_ MotorSpd : 8|16@1+ (0.5,0) [0|32127.5] "rpm" Vector__XXX
 SG_ CtrlCmdStatus : 6|2@1+ (1,0) [0|3] "" Vector__XXX
 SG_ CtrlStatusReasonCode : 2|4@1+ (1,0) [0|15] "" Vector__XXX
 SG_ EnableStatus : 0|2@1+ (1,0) [0|3] "" Vector__XXX

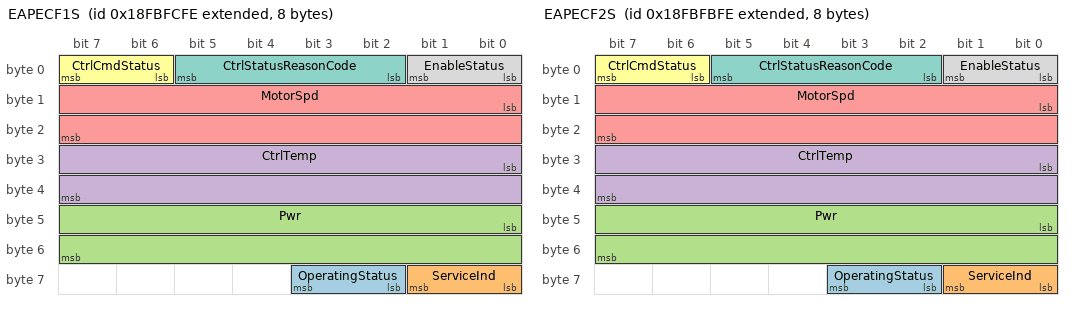
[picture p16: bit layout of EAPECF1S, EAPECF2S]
BO_ 2566651134 EAPECF1S: 8 Vector__XXX
 SG_ OperatingStatus : 58|2@1+ (1,0) [0|3] "" Vector__XXX
 SG_ ServiceInd : 56|2@1+ (1,0) [0|3] "" Vector__XXX
 SG_ Pwr : 40|16@1+ (0.5,0) [0|32127.5] "W" Vector__XXX
 SG_ CtrlTemp : 24|16@1+ (0.03125,-273) [-273|1734.96875] "캜" Vector__XXX
 SG_ MotorSpd : 8|16@1+ (0.5,0) [0|32127.5] "rpm" Vector__XXX
 SG_ CtrlCmdStatus : 6|2@1+ (1,0) [0|3] "" Vector__XXX
 SG_ CtrlStatusReasonCode : 2|4@1+ (1,0) [0|15] "" Vector__XXX
 SG_ EnableStatus : 0|2@1+ (1,0) [0|3] "" Vector__XXX

BO_ 2566650878 EAPECF2S: 8 Vector__XXX
 SG_ OperatingStatus : 58|2@1+ (1,0) [0|3] "" Vector__XXX
 SG_ ServiceInd : 56|2@1+ (1,0) [0|3] "" Vector__XXX
 SG_ Pwr : 40|16@1+ (0.5,0) [0|32127.5] "W" Vector__XXX
 SG_ CtrlTemp : 24|16@1+ (0.03125,-273) [-273|1734.96875] "캜" Vector__XXX
 SG_ MotorSpd : 8|16@1+ (0.5,0) [0|32127.5] "rpm" Vector__XXX
 SG_ CtrlCmdStatus : 6|2@1+ (1,0) [0|3] "" Vector__XXX
 SG_ CtrlStatusReasonCode : 2|4@1+ (1,0) [0|15] "" Vector__XXX
 SG_ EnableStatus : 0|2@1+ (1,0) [0|3] "" Vector__XXX

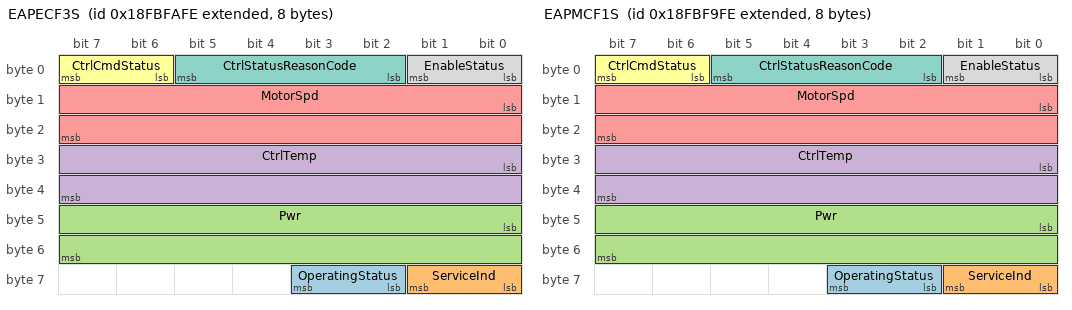
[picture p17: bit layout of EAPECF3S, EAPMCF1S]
BO_ 2566650622 EAPECF3S: 8 Vector__XXX
 SG_ OperatingStatus : 58|2@1+ (1,0) [0|3] "" Vector__XXX
 SG_ ServiceInd : 56|2@1+ (1,0) [0|3] "" Vector__XXX
 SG_ Pwr : 40|16@1+ (0.5,0) [0|32127.5] "W" Vector__XXX
 SG_ CtrlTemp : 24|16@1+ (0.03125,-273) [-273|1734.96875] "캜" Vector__XXX
 SG_ MotorSpd : 8|16@1+ (0.5,0) [0|32127.5] "rpm" Vector__XXX
 SG_ CtrlCmdStatus : 6|2@1+ (1,0) [0|3] "" Vector__XXX
 SG_ CtrlStatusReasonCode : 2|4@1+ (1,0) [0|15] "" Vector__XXX
 SG_ EnableStatus : 0|2@1+ (1,0) [0|3] "" Vector__XXX

BO_ 2566650366 EAPMCF1S: 8 Vector__XXX
 SG_ OperatingStatus : 58|2@1+ (1,0) [0|3] "" Vector__XXX
 SG_ ServiceInd : 56|2@1+ (1,0) [0|3] "" Vector__XXX
 SG_ Pwr : 40|16@1+ (0.5,0) [0|32127.5] "W" Vector__XXX
 SG_ CtrlTemp : 24|16@1+ (0.03125,-273) [-273|1734.96875] "캜" Vector__XXX
 SG_ MotorSpd : 8|16@1+ (0.5,0) [0|32127.5] "rpm" Vector__XXX
 SG_ CtrlCmdStatus : 6|2@1+ (1,0) [0|3] "" Vector__XXX
 SG_ CtrlStatusReasonCode : 2|4@1+ (1,0) [0|15] "" Vector__XXX
 SG_ EnableStatus : 0|2@1+ (1,0) [0|3] "" Vector__XXX

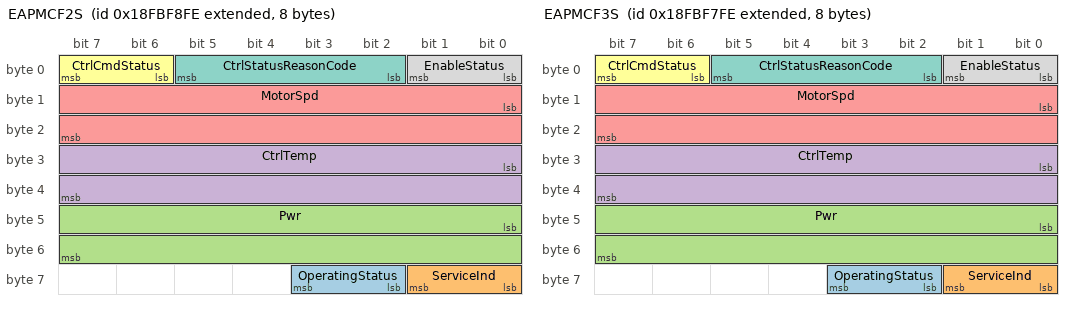
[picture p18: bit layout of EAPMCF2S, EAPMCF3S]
BO_ 2566650110 EAPMCF2S: 8 Vector__XXX
 SG_ OperatingStatus : 58|2@1+ (1,0) [0|3] "" Vector__XXX
 SG_ ServiceInd : 56|2@1+ (1,0) [0|3] "" Vector__XXX
 SG_ Pwr : 40|16@1+ (0.5,0) [0|32127.5] "W" Vector__XXX
 SG_ CtrlTemp : 24|16@1+ (0.03125,-273) [-273|1734.96875] "캜" Vector__XXX
 SG_ MotorSpd : 8|16@1+ (0.5,0) [0|32127.5] "rpm" Vector__XXX
 SG_ CtrlCmdStatus : 6|2@1+ (1,0) [0|3] "" Vector__XXX
 SG_ CtrlStatusReasonCode : 2|4@1+ (1,0) [0|15] "" Vector__XXX
 SG_ EnableStatus : 0|2@1+ (1,0) [0|3] "" Vector__XXX

BO_ 2566649854 EAPMCF3S: 8 Vector__XXX
 SG_ OperatingStatus : 58|2@1+ (1,0) [0|3] "" Vector__XXX
 SG_ ServiceInd : 56|2@1+ (1,0) [0|3] "" Vector__XXX
 SG_ Pwr : 40|16@1+ (0.5,0) [0|32127.5] "W" Vector__XXX
 SG_ CtrlTemp : 24|16@1+ (0.03125,-273) [-273|1734.96875] "캜" Vector__XXX
 SG_ MotorSpd : 8|16@1+ (0.5,0) [0|32127.5] "rpm" Vector__XXX
 SG_ CtrlCmdStatus : 6|2@1+ (1,0) [0|3] "" Vector__XXX
 SG_ CtrlStatusReasonCode : 2|4@1+ (1,0) [0|15] "" Vector__XXX
 SG_ EnableStatus : 0|2@1+ (1,0) [0|3] "" Vector__XXX

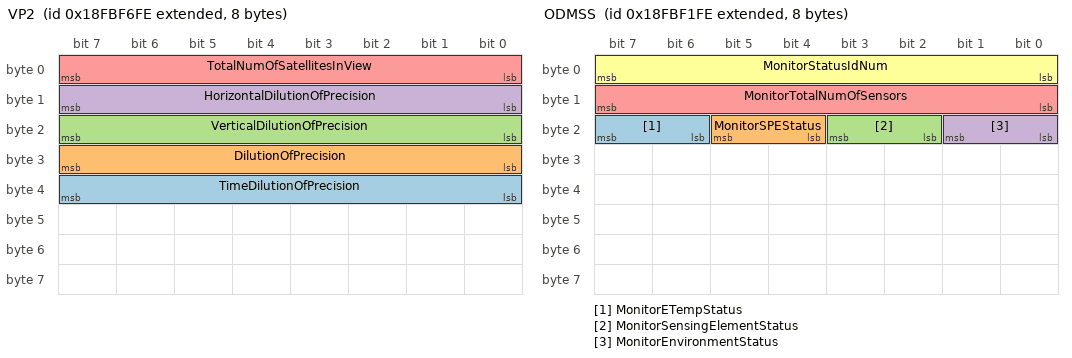
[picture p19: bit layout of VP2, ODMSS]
BO_ 2566649598 VP2: 8 Vector__XXX
 SG_ TimeDilutionOfPrecision : 32|8@1+ (0.1,0) [0|25] "" Vector__XXX
 SG_ DilutionOfPrecision : 24|8@1+ (0.1,0) [0|25] "" Vector__XXX
 SG_ VerticalDilutionOfPrecision : 16|8@1+ (0.1,0) [0|25] "" Vector__XXX
 SG_ HorizontalDilutionOfPrecision : 8|8@1+ (0.1,0) [0|25] "" Vector__XXX
 SG_ TotalNumOfSatellitesInView : 0|8@1+ (1,0) [0|250] "" Vector__XXX

BO_ 2566649342 A1DOC2: 8 Vector__XXX
 SG_ DOCInToDPFOutDeltaPress : 32|16@1+ (0.1,0) [0|6425.5] "kPa" Vector__XXX
 SG_ OutPress : 16|16@1+ (0.1,0) [0|6425.5] "kPa" Vector__XXX
 SG_ InPress : 0|16@1+ (0.1,0) [0|6425.5] "kPa" Vector__XXX

BO_ 2566649086 A2DOC2: 8 Vector__XXX
 SG_ DOCInToDPFOutDeltaPress : 32|16@1+ (0.1,0) [0|6425.5] "kPa" Vector__XXX
 SG_ OutPress : 16|16@1+ (0.1,0) [0|6425.5] "kPa" Vector__XXX
 SG_ InPress : 0|16@1+ (0.1,0) [0|6425.5] "kPa" Vector__XXX

BO_ 2365322238 CCVS5: 8 Vector__XXX
 SG_ DirVS : 0|16@1+ (0.0078125,-250) [-250|251.992] "km/h" Vector__XXX

BO_ 2566648318 ODMSS: 8 Vector__XXX
 SG_ MonitorETempStatus : 22|2@1+ (1,0) [0|3] "" Vector__XXX
 SG_ MonitorSPEStatus : 20|2@1+ (1,0) [0|3] "" Vector__XXX
 SG_ MonitorSensingElementStatus : 18|2@1+ (1,0) [0|3] "" Vector__XXX
 SG_ MonitorEnvironmentStatus : 16|2@1+ (1,0) [0|3] "" Vector__XXX
 SG_ MonitorTotalNumOfSensors : 8|8@1+ (1,0) [0|250] "" Vector__XXX
 SG_ MonitorStatusIdNum : 0|8@1+ (1,0) [0|250] "" Vector__XXX

BO_ 2566648062 ODMCNF5_6: 8 Vector__XXX
 SG_ NFBin6Count : 32|24@1+ (1,0) [0|16449535] "" Vector__XXX
 SG_ NFBin5Count : 8|24@1+ (1,0) [0|16449535] "" Vector__XXX
 SG_ NFBins5And6IdNum : 0|8@1+ (1,0) [0|250] "" Vector__XXX

BO_ 2566647806 ODMCNF3_4: 8 Vector__XXX
 SG_ NFBin4Count : 32|24@1+ (1,0) [0|16449535] "" Vector__XXX
 SG_ NFBin3Count : 8|24@1+ (1,0) [0|16449535] "" Vector__XXX
 SG_ NFBins3And4IdNum : 0|8@1+ (1,0) [0|250] "" Vector__XXX

CM_ BO_ 2565942782 "DC/AC Accessory Inverter 4 Feedback 2
Sent by this Accessory Inverter instance and contains the current operating conditions of this output of the inverter.  This message would be received by a controller application (e.g. Power System Manager) ...";
CM_ SG_ 2565942782 PLedDueToUndefinedReason "Output power is being limited due to an undefined reason.

00 - No power limit for this reason
01 - Power limited for this reason
10 - Error
11 - Not Available";
CM_ SG_ 2565942782 PLedDueToRateOfChangeLmt "Output power is being limited due to the frequency approaching or exceeding the rate of change limit (see SPN 8374).

00 - No frequency limit for this reason
01 - Frequency limited for this reason
10 - Error
11 - Not Available";
CM_ SG_ 2565942782 PLedDueToPwrETemp "Output power is being limited due to power electronics temperature (see SPN 9293) approaching or exceeding the maximum limit.

00 - No frequency limit for this reason
01 - Frequency limited for this reason
10 - Error
11 - Not Available";
CM_ SG_ 2565942782 PLedDueToEFilterTemp "Output power is being limited due to electronic filter temperature (see SPN 9292) approaching or exceeding the maximum limit.

00 - No frequency limit for this reason
01 - Frequency limited for this reason
10 - Error
11 - Not Available";
CM_ SG_ 2565942782 PLedDueToCtrlTemp "Output power is being limited due to the controller temperature (see SPN 9291) approaching or exceeding the maximum limit.

00 - No power limit for this reason
01 - Power limited for this reason
10 - Error
11 - Not Available";
CM_ SG_ 2565942782 FreqCmdExceedsMax "Output frequency is being limited due to frequency command (see SPN 8375) approaching or exceeding the maximum limit (SPN 8370).

00 - No frequency limit for this reason
01 - Frequency limited for this reason
10 - Error
11 - Not Available";
CM_ SG_ 2565942782 FreqCmdBelowMin "Output frequency is being limited due to frequency command (see SPN 8375) approaching or falling below the minimum limit (SPN 8371).

00 - No frequency limit for this reason
01 - Frequency limited for this reason
10 - Error
11 - Not Available";
CM_ SG_ 2565942782 PLedDueToDCSideVMin "Output power is being limited due to DC Side input voltage (see SPN 9297) approaching or falling below the minimum limit (SPN 9315).

00 - No power limit for this reason
01 - Power limited for this reason
10 - Error
11 - Not Available";
CM_ SG_ 2565942782 PLedDueToACSideRMSCur "AC Side Output power is being limited due to AC Side output RMS current (see SPN 9203) approaching or exceeding the maximum limit (See SPN 9318).
00 - No power limit for this reason
01 - Power limited for this reason
10 - Error
11 - Not ...";
CM_ SG_ 2565942782 PLedDueToDCSideCur "Output power is being limited due to DC Side input current (see SPN 9298) approaching or exceeding the maximum limit (See SPN 9316).

00 - No power limit for this reason
01 - Power limited for this reason
10 - Error
11 - Not Available";
CM_ BO_ 2364615934 "DC/AC Accessory Inverter 4 Voltage
Low Voltage data from DC/AC Accessory Inverter.";
CM_ SG_ 2364615934 SLIV "Low voltage (SLI) supplied to the DC/AC Accessory Inverter controller.";
CM_ SG_ 2364615934 IgntV "Ignition voltage supplied to the  DC/AC Accessory Inverter controller.";
CM_ BO_ 2364615678 "DC/AC Accessory Inverter 4 Status 2
Additional data reported from DC/AC Accessory Inverter";
CM_ SG_ 2364615678 DCSideNegToChassisGroundV "The voltage level of the high voltage DC side, as measured by the DC/AC between the negative side of the High Voltage DC Side input and the chassis of the DC/AC enclosure.  This voltage can be used for system level monitoring of DC Side High Voltage ...";
CM_ SG_ 2364615678 DCSideCur "DC Side input current measured at the point of control inside the DC/AC Accessory Inverter.";
CM_ SG_ 2364615678 DCSideV "DC Side input voltage measured at the point of control inside the DC/AC Accessory Inverter.";
CM_ SG_ 2364615678 DCSidePwr "Power measured at the DC Side input to the DC/AC Accessory Inverter.";
CM_ BO_ 2565942014 "DC/AC Accessory Inverter 3 Feedback 2
Sent by this Accessory Inverter instance and contains the current operating conditions of this output of the inverter.  This message would be received by a controller application (e.g. Power System Manager) ...";
CM_ SG_ 2565942014 PLedDueToUndefinedReason "Output power is being limited due to an undefined reason.

00 - No power limit for this reason
01 - Power limited for this reason
10 - Error
11 - Not Available";
CM_ SG_ 2565942014 PLedDueToRateOfChangeLmt "Output power is being limited due to the frequency approaching or exceeding the rate of change limit (see SPN 8360).

00 - No frequency limit for this reason
01 - Frequency limited for this reason
10 - Error
11 - Not Available";
CM_ SG_ 2565942014 PLedDueToPwrETemp "Output power is being limited due to power electronics temperature (see SPN 9263) approaching or exceeding the maximum limit.

00 - No frequency limit for this reason
01 - Frequency limited for this reason
10 - Error
11 - Not Available";
CM_ SG_ 2565942014 PLedDueToEFilterTemp "Output power is being limited due to electronic filter temperature (see SPN 9262) approaching or exceeding the maximum limit.

00 - No frequency limit for this reason
01 - Frequency limited for this reason
10 - Error
11 - Not Available";
CM_ SG_ 2565942014 PLedDueToCtrlTemp "Output power is being limited due to the controller temperature (see SPN 9261) approaching or exceeding the maximum limit.

00 - No power limit for this reason
01 -  Power limited for this reason
10 - Error
11 - Not Available";
CM_ SG_ 2565942014 FreqCmdExceedsMax "Output frequency is being limited due to frequency command (see SPN 8361) approaching or exceeding the maximum limit (SPN 8356).

00 - No frequency limit for this reason
01 - Frequency limited for this reason
10 - Error
11 - Not Available";
CM_ SG_ 2565942014 FreqCmdBelowMin "Output frequency is being limited due to frequency command (see SPN 8361) approaching or falling below the minimum limit (SPN 8357).

00 - No frequency limit for this reason
01 - Frequency limited for this reason
10 - Error
11 - Not Available";
CM_ SG_ 2565942014 PLedDueToDCSideVMin "Output power is being limited due to DC Side input voltage (see SPN 9267) approaching or falling below the minimum limit  (SPN 9285).

00 - No power limit for this reason
01 - Power limited for this reason
10 - Error
11 - Not Available";
CM_ SG_ 2565942014 PLedDueToACSideRMSCur "AC Side Output power is being limited due to AC Side output RMS current (see SPN 9202) approaching or exceeding the maximum limit (See SPN 9288).
00 - No power limit for this reason
01 - Power limited for this reason
10 - Error
11 - Not ...";
CM_ SG_ 2565942014 PLedDueToDCSideCur "Output power is being limited due to DC Side input current (see SPN 9268) approaching or exceeding the maximum limit (See SPN 9286).

00 - No power limit for this reason
01 - Power limited for this reason
10 - Error
11 - Not Available";
CM_ BO_ 2364615166 "DC/AC Accessory Inverter 3 Voltage
Low Voltage data from DC/AC Accessory Inverter.";
CM_ SG_ 2364615166 SLIV "Low voltage (SLI) supplied to the DC/AC Accessory Inverter controller.";
CM_ SG_ 2364615166 IgntV "Ignition voltage supplied to the  DC/AC Accessory Inverter controller.";
CM_ BO_ 2364614910 "DC/AC Accessory Inverter 3 Status 2
Additional data reported from DC/AC Accessory Inverter";
CM_ SG_ 2364614910 DCSideNegToChassisGroundV "The voltage level of the high voltage DC side, as measured by the DC/AC between the negative side of the High Voltage DC Side input and the chassis of the DC/AC enclosure.  This voltage can be used for system level monitoring of DC Side High Voltage ...";
CM_ SG_ 2364614910 DCSideCur "DC Side input current measured at the point of control inside the DC/AC Accessory Inverter.";
CM_ SG_ 2364614910 DCSideV "DC Side input voltage measured at the point of control inside the DC/AC Accessory Inverter.";
CM_ SG_ 2364614910 DCSidePwr "Power measured at the DC Side input to the DC/AC Accessory Inverter.";
CM_ BO_ 2364614654 "Slope Sensor Information 3
Provides additional grade or slope data.";
CM_ SG_ 2364614654 GradeThresholdInd6 "This parameter indicates whether or not the transmitting device has sensed a vehicle grade equal to or exceeding a manufacturer-defined threshold. The manufacturer-defined threshold could be a simple fixed value or a dynamic value that changes based ...";
CM_ SG_ 2364614654 GradeThresholdInd5 "This parameter indicates whether or not the transmitting device has sensed a vehicle grade equal to or exceeding a manufacturer-defined threshold. The manufacturer-defined threshold could be a simple fixed value or a dynamic value that changes based ...";
CM_ SG_ 2364614654 GradeThresholdInd4 "This parameter indicates whether or not the transmitting device has sensed a vehicle grade equal to or exceeding a manufacturer-defined threshold. The manufacturer-defined threshold could be a simple fixed value or a dynamic value that changes based ...";
CM_ SG_ 2364614654 GradeThresholdInd3 "This parameter indicates whether or not the transmitting device has sensed a vehicle grade equal to or exceeding a manufacturer-defined threshold. The manufacturer-defined threshold could be a simple fixed value or a dynamic value that changes based ...";
CM_ SG_ 2364614654 GradeThresholdInd2 "This parameter indicates whether or not the transmitting device has sensed a vehicle grade equal to or exceeding a manufacturer-defined threshold. The manufacturer-defined threshold could be a simple fixed value or a dynamic value that changes based ...";
CM_ SG_ 2364614654 GradeThresholdInd1 "This parameter indicates whether or not the transmitting device has sensed a vehicle grade equal to or exceeding a manufacturer-defined threshold. The manufacturer-defined threshold could be a simple fixed value or a dynamic value that changes based ...";
CM_ BO_ 2364614398 "DC/DC Converter 4 Status 2
Additional data reported from a DC/DC Converter";
CM_ SG_ 2364614398 FourHiSideNegToChassisGroundV "The voltage level of the high voltage DC side, as measured by the DC/DC between the negative side of the High Voltage DC Side input and the chassis of the DC/DC enclosure.  This voltage can be used for system level monitoring of DC Side High Voltage ...";
CM_ SG_ 2364614398 FourHiSidePwr "Indicates the measured HVES or high side power measured at the DC/DC Converter.  The high side power is positive if the converter is charging the hybrid battery from the SLI battery (i.e. Boost Mode).  The high side power is negative if the ...";
CM_ SG_ 2364614398 FourLowSidePwr "Indicates the measured SLI battery or low side power measured at the DC/DC Converter.  The low side power is positive if the converter is charging the SLI battery from the hybrid battery (i.e. Buck Mode).  The low side power is negative if the ...";
CM_ BO_ 2364614142 "DC/DC Converter 4 SLI Battery Status
Status of the SLI battery measured at the SLI battery terminals.

One intended use of this message is for a conventional engine mounted alternator replacement.";
CM_ SG_ 2364614142 SLIBatTermTemp "Parameter indicating the SLI battery terminal temperature for control use by the DC/DC converter.";
CM_ SG_ 2364614142 SLIBatTermCur "Parameter indicating the SLI battery terminal current for control use by the DC/DC converter.  The current is positive if the SLI battery or low side voltage source is being charged from the HVES.";
CM_ SG_ 2364614142 SLIBatTermV "Parameter indicating the SLI battery terminal voltage for control use by the DC/DC converter.";
CM_ BO_ 2364613886 "DC/DC Converter 4 Voltage and Current
Voltage and current data from a DC/DC Converter.

One intended use of this message is for a conventional engine mounted alternator replacement.";
CM_ SG_ 2364613886 FourHiSideCur "Indicates the measured HVES or high side current measured at the point of control inside the DC/DC Converter.  The current is negative if the converter is charging the SLI battery from the hybrid battery.";
CM_ SG_ 2364613886 FourHiSideV "Indicates the measured HVES or high side voltage measured at the point of control inside the DC/DC Converter.";
CM_ SG_ 2364613886 FourLowSideCur "Indicates the measured SLI battery or low side current measured at the point of control inside the DC/DC Converter.  The current is positive if the converter is charging the SLI battery from the hybrid battery.";
CM_ SG_ 2364613886 FourLowSideV "Indicates the measured SLI battery or low side voltage measured at the point of control inside the DC/DC Converter.";
CM_ BO_ 2364613630 "DC/DC Converter 4 Operating Status
Contains information on the operating status of a DC/DC Converter.

One intended use of this message is for a conventional engine mounted alternator replacement.";
CM_ SG_ 2364613630 FourPLDueToUndefinedReason "Indicates whether or not output power is being limited due to an undefined reason.

00 - No power limit for this reason
01 - Power limited for this reason
10 - Error
11 - Not Available";
CM_ SG_ 2364613630 FourPLDueToSLIBatTermTemp "Indicates whether or not output power is being limited due to the SLI battery terminal temperature (see SPN 9027) approaching or exceeding limits (see SPN 9045).
00 - No power limit for this reason
01 - Power limited for this reason
10 - Error
 ...";
CM_ SG_ 2364613630 FourPLDueToSLIBatTermCur "Indicates whether or not output power is being limited due to the SLI battery terminal current (see SPN 9026) approaching or exceeding limits (see SPN 9044).
00 - No power limit for this reason
01 - Power limited for this reason
10 - Error
11 - ...";
CM_ SG_ 2364613630 FourPLDueToSLIBatTermV "Indicates whether or not output power is being limited due to the SLI battery terminal voltage (see SPN 9025) approaching or exceeding limits (see SPN 9043).
00 - No power limit for this reason
01 - Power limited for this reason
10 - Error
11 - ...";
CM_ SG_ 2364613630 FourPLDueToPwrETemp "Indicates whether or not output power is being limited due to Power Electronics Temperature (see SPN 9048) approaching or exceeding the maximum limit.
00 - No power limit for this reason
01 - Power limited for this reason
10 - Error
11 - Not ...";
CM_ SG_ 2364613630 FourPLDueToEFilterTemp "Indicates whether or not output power is being limited due to Output Electronic Filter Temperature (see SPN 9047) approaching or exceeding the maximum limit.
00 - No power limit for this reason
01 - Power limited for this reason
10 - Error
11 - ...";
CM_ SG_ 2364613630 FourPLDueToConvTemp "Indicates whether or not output power is being limited due to Converter Temperature (see SPN 9046) approaching or exceeding the maximum limit.

00 - No power limit for this reason
01 - Power limited for this reason
10 - Error
11 - Not Available";
CM_ SG_ 2364613630 FourPLDueToLowSideVMax "Indicates whether or not output power is being limited due to low side voltage (see SPN 9021) approaching or exceeding the maximum limit (see SPN 9052).
00 - No power limit for this reason
01 - Power limited for this reason
10 - Error
11 - Not ...";
CM_ SG_ 2364613630 FourPLDueToLowSideVMin "Indicates whether or not output power is being limited due to low side voltage (see SPN 9021) approaching or falling below the minimum limit (see SPN 9051).
00 - No power limit for this reason
01 - Power limited for this reason
10 - Error
11 - ...";
CM_ SG_ 2364613630 FourPLDueToHiSideVMax "Indicates whether or not output power is being limited due to high side voltage (see SPN 9023) approaching or exceeding the maximum limit (see SPN 9055).
00 - No power limit for this reason
01 - Power limited for this reason
10 - Error
11 - Not ...";
CM_ SG_ 2364613630 FourPLDueToHiSideVMin "Indicates whether or not output power is being limited due to high side voltage (see SPN 9023) approaching or falling below the minimum limit (see SPN 9054).
00 - No power limit for this reason
01 - Power limited for this reason
10 - Error
11 - ...";
CM_ SG_ 2364613630 FourPLDueToLowSideCur "Indicates whether or not output power is being limited due to low side current (see SPN 9022) approaching or exceeding the maximum limit (see SPN 9053).
00 - No power limit for this reason
01 - Power limited for this reason
10 - Error
11 - Not ...";
CM_ SG_ 2364613630 FourPLDueToHiSideCur "Indicates whether or not output power is being limited due to high side current (see SPN 9024) approaching or exceeding the maximum limit (see SPN 9056).
00 - No power limit for this reason
01 - Power limited for this reason
10 - Error
11 - Not ...";
CM_ SG_ 2364613630 FourLoadshedReq "The loadshed request is a request to the controlling device to reduce the DC/DC Converter loads.  The Loadshed Requested state is an indication that this DC/DC Converter has a malfunction or is in a limit condition and if the load of the output is ...";
CM_ SG_ 2364613630 FourHVILStatus "High Voltage Interlock Loop (HVIL) state of the DC/DC Converter.

00 - HVIL Closed
01 - HVIL Open
10 - Error
11 - Not Available";
CM_ SG_ 2364613630 FourOperationalStatus "Operating state of the DC/DC Converter
0000 - Disabled
0001 - Initialization in process.  The device is powering up.  This process may include both internal checks, as well as system checks being run by the DC/DC Converter.
0010 - Operational - ...";
CM_ BO_ 2364613374 "DC/DC Converter 4 Control
Controls the transfer of energy between the HVES or high voltage system (i.e. high side) and the SLI battery or low voltage system (i.e. low side).  Provides a function to either charge the SLI Battery from the HVES (Buck) ...";
CM_ SG_ 2364613374 FourLowSideVBuckDefaultSetpoint "The set point for the converter default low side voltage during buck mode.   This setting may be used for when communication has been lost with the controlling device.  When set to Not Available (FFFFh), no default setting is provided and the system ...";
CM_ SG_ 2364613374 FourHiSideVBoostSetpoint "The set point for regulating the high side voltage during boost mode.";
CM_ SG_ 2364613374 FourLowSideVBuckSetpoint "The set point for regulating the low side voltage during buck mode.";
CM_ SG_ 2364613374 FourOperationalCmd "Command to enable or disable operation.
0000 - Disable - in this mode all high voltage switching is disabled
0001 - Operate in standby mode; system is waiting for command to enter buck or boost mode
0010 - Operate in buck mode; energy flows from ...";
CM_ BO_ 2364613118 "DC/DC Converter 3 Status 2
Additional data reported from a DC/DC Converter";
CM_ SG_ 2364613118 ThreeHiSideNegToChassisGroundV "The voltage level of the high voltage DC side, as measured by the DC/DC between the negative side of the High Voltage DC Side input and the chassis of the DC/DC enclosure.  This voltage can be used for system level monitoring of DC Side High Voltage ...";
CM_ SG_ 2364613118 ThreeHiSidePwr "Indicates the measured HVES or high side power measured at the DC/DC Converter.  The high side power is positive if the converter is charging the hybrid battery from the SLI battery (i.e. Boost Mode).  The high side power is negative if the ...";
CM_ SG_ 2364613118 ThreeLowSidePwr "Indicates the measured SLI battery or low side power measured at the DC/DC Converter.  The low side power is positive if the converter is charging the SLI battery from the hybrid battery (i.e. Buck Mode).  The low side power is negative if the ...";
CM_ BO_ 2364612862 "DC/DC Converter 3 SLI Battery Status
Status of the SLI battery measured at the SLI battery terminals.

One intended use of this message is for a conventional engine mounted alternator replacement.";
CM_ SG_ 2364612862 SLIBatTermTemp "Parameter indicating the SLI battery terminal temperature for control use by the DC/DC converter.";
CM_ SG_ 2364612862 SLIBatTermCur "Parameter indicating the SLI battery terminal current for control use by the DC/DC converter.  The current is positive if the SLI battery or low side voltage source is being charged from the HVES.";
CM_ SG_ 2364612862 SLIBatTermV "Parameter indicating the SLI battery terminal voltage for control use by the DC/DC converter.";
CM_ BO_ 2364612606 "DC/DC Converter 3 Voltage and Current
Voltage and current data from a DC/DC Converter.

One intended use of this message is for a conventional engine mounted alternator replacement.";
CM_ SG_ 2364612606 ThreeHiSideCur "Indicates the measured HVES or high side current measured at the point of control inside the DC/DC Converter.  The current is negative if the converter is charging the SLI battery from the hybrid battery.";
CM_ SG_ 2364612606 ThreeHiSideV "Indicates the measured HVES or high side voltage measured at the point of control inside the DC/DC Converter.";
CM_ SG_ 2364612606 ThreeLowSideCur "Indicates the measured SLI battery or low side current measured at the point of control inside the DC/DC Converter.  The current is positive if the converter is charging the SLI battery from the hybrid battery.";
CM_ SG_ 2364612606 ThreeLowSideV "Indicates the measured SLI battery or low side voltage measured at the point of control inside the DC/DC Converter.";
CM_ BO_ 2364612350 "DC/DC Converter 3 Operating Status
Contains information on the operating status of a DC/DC Converter.

One intended use of this message is for a conventional engine mounted alternator replacement.";
CM_ SG_ 2364612350 ThreePLDueToUndefinedReason "Indicates whether or not output power is being limited due to an undefined reason.

00 - No power limit for this reason
01 - Power limited for this reason
10 - Error
11 - Not Available";
CM_ SG_ 2364612350 ThreePLDueToSLIBatTermTemp "Indicates whether or not output power is being limited due to the SLI battery terminal temperature (see SPN 8972) approaching or exceeding limits (see SPN 8990).
00 - No power limit for this reason
01 - Power limited for this reason
10 - Error
 ...";
CM_ SG_ 2364612350 ThreePLDueToSLIBatTermCur "Indicates whether or not output power is being limited due to the SLI battery terminal current (see SPN 8971) approaching or exceeding limits (see SPN 8989).
00 - No power limit for this reason
01 - Power limited for this reason
10 - Error
11 - ...";
CM_ SG_ 2364612350 ThreePLDueToSLIBatTermV "Indicates whether or not output power is being limited due to the SLI battery terminal voltage (see SPN 8970) approaching or exceeding limits (see SPN 8988).
00 - No power limit for this reason
01 - Power limited for this reason
10 - Error
11 - ...";
CM_ SG_ 2364612350 ThreePLDueToPwrETemp "Indicates whether or not output power is being limited due to Power Electronics Temperature (see SPN 8993) approaching or exceeding the maximum limit.
00 - No power limit for this reason
01 - Power limited for this reason
10 - Error
11 - Not ...";
CM_ SG_ 2364612350 ThreePLDueToEFilterTemp "Indicates whether or not output power is being limited due to Output Electronic Filter Temperature (see SPN 8992) approaching or exceeding the maximum limit.
00 - No power limit for this reason
01 - Power limited for this reason
10 - Error
11 - ...";
CM_ SG_ 2364612350 ThreePLDueToConvTemp "Indicates whether or not output power is being limited due to Converter Temperature (see SPN 8991) approaching or exceeding the maximum limit.

00 - No power limit for this reason
01 - Power limited for this reason
10 - Error
11 - Not Available";
CM_ SG_ 2364612350 ThreePLDueToLowSideVMax "Indicates whether or not output power is being limited due to low side voltage (see SPN 8966) approaching or exceeding the maximum limit (see SPN 8997).
00 - No power limit for this reason
01 - Power limited for this reason
10 - Error
11 - Not ...";
CM_ SG_ 2364612350 ThreePLDueToLowSideVMin "Indicates whether or not output power is being limited due to low side voltage (see SPN 8966) approaching or falling below the minimum limit (see SPN 8996).
00 - No power limit for this reason
01 - Power limited for this reason
10 - Error
11 - ...";
CM_ SG_ 2364612350 ThreePLDueToHiSideVMax "Indicates whether or not output power is being limited due to high side voltage (see SPN 8968) approaching or exceeding the maximum limit (see SPN 9000).
00 - No power limit for this reason
01 - Power limited for this reason
10 - Error
11 - Not ...";
CM_ SG_ 2364612350 ThreePLDueToHiSideVMin "Indicates whether or not output power is being limited due to high side voltage (see SPN 8968) approaching or falling below the minimum limit (see SPN 8999).
00 - No power limit for this reason
01 - Power limited for this reason
10 - Error
11 - ...";
CM_ SG_ 2364612350 ThreePLDueToLowSideCur "Indicates whether or not output power is being limited due to low side current (see SPN 8967) approaching or exceeding the maximum limit (see SPN 8998).
00 - No power limit for this reason
01 - Power limited for this reason
10 - Error
11 - Not ...";
CM_ SG_ 2364612350 ThreePLDueToHiSideCur "Indicates whether or not output power is being limited due to high side current (see SPN 8969) approaching or exceeding the maximum limit (see SPN 9001).
00 - No power limit for this reason
01 - Power limited for this reason
10 - Error
11 - Not ...";
CM_ SG_ 2364612350 ThreeLoadshedReq "The loadshed request is a request to the controlling device to reduce the DC/DC Converter loads.  The Loadshed Requested state is an indication that this DC/DC Converter has a malfunction or is in a limit condition and if the load of the output is ...";
CM_ SG_ 2364612350 ThreeHVILStatus "High Voltage Interlock Loop (HVIL) state of the DC/DC Converter.

00 - HVIL Closed
01 - HVIL Open
10 - Error
11 - Not Available";
CM_ SG_ 2364612350 ThreeOperationalStatus "Operating state of the DC/DC Converter
0000 - Disabled
0001 - Initialization in process.  The device is powering up.  This process may include both internal checks, as well as system checks being run by the DC/DC Converter.
0010 - Operational - ...";
CM_ BO_ 2364612094 "DC/DC Converter 3 Control
Controls the transfer of energy between the HVES or high voltage system (i.e. high side) and the SLI battery or low voltage system (i.e. low side).  Provides a function to either charge the SLI Battery from the HVES (Buck) ...";
CM_ SG_ 2364612094 ThreeLowSideVBuckDefaultSetpoint "The set point for the converter default low side voltage during buck mode.   This setting may be used for when communication has been lost with the controlling device.  When set to Not Available (FFFFh), no default setting is provided and the system ...";
CM_ SG_ 2364612094 ThreeHiSideVBoostSetpoint "The set point for regulating the high side voltage during boost mode.";
CM_ SG_ 2364612094 ThreeLowSideVBuckSetpoint "The set point for regulating the low side voltage during buck mode.";
CM_ SG_ 2364612094 ThreeOperationalCmd "Command to enable or disable operation.
0000 - Disable - in this mode all high voltage switching is disabled
0001 - Operate in standby mode; system is waiting for command to enter buck or boost mode
0010 - Operate in buck mode; energy flows from ...";
CM_ BO_ 2364611838 "DC/DC Converter 2 Status 2
Additional data reported from a DC/DC Converter";
CM_ SG_ 2364611838 TwoHiSideNegToChassisGroundV "The voltage level of the high voltage DC side, as measured by the DC/DC between the negative side of the High Voltage DC Side input and the chassis of the DC/DC enclosure.  This voltage can be used for system level monitoring of DC Side High Voltage ...";
CM_ SG_ 2364611838 TwoHiSidePwr "Indicates the measured HVES or high side power measured at the DC/DC Converter.  The high side power is positive if the converter is charging the hybrid battery from the SLI battery (i.e. Boost Mode).  The high side power is negative if the ...";
CM_ SG_ 2364611838 TwoLowSidePwr "Indicates the measured SLI battery or low side power measured at the DC/DC Converter.  The low side power is positive if the converter is charging the SLI battery from the hybrid battery (i.e. Buck Mode).  The low side power is negative if the ...";
CM_ BO_ 2364611582 "DC/DC Converter 2 SLI Battery Status
Status of the SLI battery measured at the SLI battery terminals.

One intended use of this message is for a conventional engine mounted alternator replacement.";
CM_ SG_ 2364611582 SLIBatTermTemp "Parameter indicating the SLI battery terminal temperature for control use by the DC/DC converter.";
CM_ SG_ 2364611582 SLIBatTermCur "Parameter indicating the SLI battery terminal current for control use by the DC/DC converter.  The current is positive if the SLI battery or low side voltage source is being charged from the HVES.";
CM_ SG_ 2364611582 SLIBatTermV "Parameter indicating the SLI battery terminal voltage for control use by the DC/DC converter.";
CM_ BO_ 2364611326 "DC/DC Converter 2 Voltage and Current
Voltage and current data from a DC/DC Converter.

One intended use of this message is for a conventional engine mounted alternator replacement.";
CM_ SG_ 2364611326 TwoHiSideCur "Indicates the measured HVES or high side current measured at the point of control inside the DC/DC Converter.  The current is negative if the converter is charging the SLI battery from the hybrid battery.";
CM_ SG_ 2364611326 TwoHiSideV "Indicates the measured HVES or high side voltage measured at the point of control inside the DC/DC Converter.";
CM_ SG_ 2364611326 TwoLowSideCur "Indicates the measured SLI battery or low side current measured at the point of control inside the DC/DC Converter.  The current is positive if the converter is charging the SLI battery from the hybrid battery.";
CM_ SG_ 2364611326 TwoLowSideV "Indicates the measured SLI battery or low side voltage measured at the point of control inside the DC/DC Converter.";
CM_ BO_ 2364611070 "DC/DC Converter 2 Operating Status
Contains information on the operating status of a DC/DC Converter.

One intended use of this message is for a conventional engine mounted alternator replacement.";
CM_ SG_ 2364611070 TwoPLDueToUndefinedReason "Indicates whether or not output power is being limited due to an undefined reason.

00 - No power limit for this reason
01 - Power limited for this reason
10 - Error
11 - Not Available";
CM_ SG_ 2364611070 TwoPLDueToSLIBatTermTemp "Indicates whether or not output power is being limited due to the SLI battery terminal temperature (see SPN 8917) approaching or exceeding limits (see SPN 8935).
00 - No power limit for this reason
01 - Power limited for this reason
10 - Error
 ...";
CM_ SG_ 2364611070 TwoPLDueToSLIBatTermCur "Indicates whether or not output power is being limited due to the SLI battery terminal current (see SPN 8916) approaching or exceeding limits (see SPN 8934).
00 - No power limit for this reason
01 - Power limited for this reason
10 - Error
11 - ...";
CM_ SG_ 2364611070 TwoPLDueToSLIBatTermV "Indicates whether or not output power is being limited due to the SLI battery terminal voltage (see SPN 8915) approaching or exceeding limits (see SPN 8933).
00 - No power limit for this reason
01 - Power limited for this reason
10 - Error
11 - ...";
CM_ SG_ 2364611070 TwoPLDueToPwrETemp "Indicates whether or not output power is being limited due to Power Electronics Temperature (see SPN 8938) approaching or exceeding the maximum limit.
00 - No power limit for this reason
01 - Power limited for this reason
10 - Error
11 - Not ...";
CM_ SG_ 2364611070 TwoPLDueToEFilterTemp "Indicates whether or not output power is being limited due to Output Electronic Filter Temperature (see SPN 8937) approaching or exceeding the maximum limit.
00 - No power limit for this reason
01 - Power limited for this reason
10 - Error
11 - ...";
CM_ SG_ 2364611070 TwoPLDueToConvTemp "Indicates whether or not output power is being limited due to Converter Temperature (see SPN 8936) approaching or exceeding the maximum limit.

00 - No power limit for this reason
01 - Power limited for this reason
10 - Error
11 - Not Available";
CM_ SG_ 2364611070 TwoPLDueToLowSideVMax "Indicates whether or not output power is being limited due to low side voltage (see SPN 8911) approaching or exceeding the maximum limit (see SPN 8942).
00 - No power limit for this reason
01 - Power limited for this reason
10 - Error
11 - Not ...";
CM_ SG_ 2364611070 TwoPLDueToLowSideVMin "Indicates whether or not output power is being limited due to low side voltage (see SPN 8911) approaching or falling below the minimum limit (see SPN 8941).
00 - No power limit for this reason
01 - Power limited for this reason
10 - Error
11 - ...";
CM_ SG_ 2364611070 TwoPLDueToHiSideVMax "Indicates whether or not output power is being limited due to high side voltage (see SPN 8913) approaching or exceeding the maximum limit (see SPN 8945).
00 - No power limit for this reason
01 - Power limited for this reason
10 - Error
11 - Not ...";
CM_ SG_ 2364611070 TwoPLDueToHiSideVMin "Indicates whether or not output power is being limited due to high side voltage (see SPN 8913) approaching or falling below the minimum limit (see SPN 8944).
00 - No power limit for this reason
01 - Power limited for this reason
10 - Error
11 - ...";
CM_ SG_ 2364611070 TwoPLDueToLowSideCur "Indicates whether or not output power is being limited due to low side current (see SPN 8912) approaching or exceeding the maximum limit (see SPN 8943).
00 - No power limit for this reason
01 - Power limited for this reason
10 - Error
11 - Not ...";
CM_ SG_ 2364611070 TwoPLDueToHiSideCur "Indicates whether or not output power is being limited due to high side current (see SPN 8914) approaching or exceeding the maximum limit (see SPN 8946).
00 - No power limit for this reason
01 - Power limited for this reason
10 - Error
11 - Not ...";
CM_ SG_ 2364611070 TwoLoadshedReq "The loadshed request is a request to the controlling device to reduce the DC/DC Converter loads.  The Loadshed Requested state is an indication that this DC/DC Converter has a malfunction or is in a limit condition and if the load of the output is ...";
CM_ SG_ 2364611070 TwoHVILStatus "High Voltage Interlock Loop (HVIL) state of the DC/DC Converter.

00 - HVIL Closed
01 - HVIL Open
10 - Error
11 - Not Available";
CM_ SG_ 2364611070 TwoOperationalStatus "Operating state of the DC/DC Converter
0000 - Disabled
0001 - Initialization in process.  The device is powering up.  This process may include both internal checks, as well as system checks being run by the DC/DC Converter.
0010 - Operational - ...";
CM_ BO_ 2364610814 "DC/DC Converter 2 Control
Controls the transfer of energy between the HVES or high voltage system (i.e. high side) and the SLI battery or low voltage system (i.e. low side).  Provides a function to either charge the SLI Battery from the HVES (Buck) ...";
CM_ SG_ 2364610814 TwoLowSideVBuckDefaultSetpoint "The set point for the converter default low side voltage during buck mode.   This setting may be used for when communication has been lost with the controlling device.  When set to Not Available (FFFFh), no default setting is provided and the system ...";
CM_ SG_ 2364610814 TwoHiSideVBoostSetpoint "The set point for regulating the high side voltage during boost mode.";
CM_ SG_ 2364610814 TwoLowSideVBuckSetpoint "The set point for regulating the low side voltage during buck mode.";
CM_ SG_ 2364610814 TwoOperationalCmd "Command to enable or disable operation.
0000 - Disable - in this mode all high voltage switching is disabled
0001 - Operate in standby mode; system is waiting for command to enter buck or boost mode
0010 - Operate in buck mode; energy flows from ...";
CM_ BO_ 2364610558 "DC/DC Converter 1 Status 2
Additional data reported from a DC/DC Converter";
CM_ SG_ 2364610558 OneHiSideNegToChassisGroundV "The voltage level of the high voltage DC side, as measured by the DC/DC between the negative side of the High Voltage DC Side input and the chassis of the DC/DC enclosure.  This voltage can be used for system level monitoring of DC Side High Voltage ...";
CM_ SG_ 2364610558 OneHiSidePwr "Indicates the measured HVES or high side power measured at the DC/DC Converter.  The high side power is positive if the converter is charging the hybrid battery from the SLI battery (i.e. Boost Mode).  The high side power is negative if the ...";
CM_ SG_ 2364610558 OneLowSidePwr "Indicates the measured SLI battery or low side power measured at the DC/DC Converter.  The low side power is positive if the converter is charging the SLI battery from the hybrid battery (i.e. Buck Mode).  The low side power is negative if the ...";
CM_ BO_ 2565918206 "DC/AC Accessory Inverter 2 Feedback 2
Sent by this Accessory Inverter instance and contains the current operating conditions of this output of the inverter.  This message would be received by a controller application (e.g. Power System Manager) ...";
CM_ SG_ 2565918206 PLedDueToUndefinedReason "Output power is being limited due to an undefined reason.

00 - No power limit for this reason
01 - Power limited for this reason
10 - Error
11 - Not Available";
CM_ SG_ 2565918206 PLedDueToRateOfChangeLmt "Output power is being limited due to the frequency approaching or exceeding the rate of change limit (see SPN 8346).

00 - No frequency limit for this reason
01 - Frequency limited for this reason
10 - Error
11 - Not Available";
CM_ SG_ 2565918206 PLedDueToPwrETemp "Output power is being limited due to power electronics temperature (see SPN 9233) approaching or exceeding the maximum limit.

00 - No frequency limit for this reason
01 - Frequency limited for this reason
10 - Error
11 - Not Available";
CM_ SG_ 2565918206 PLedDueToEFilterTemp "Output power is being limited due to electronic filter temperature (see SPN 9232) approaching or exceeding the maximum limit.

00 - No frequency limit for this reason
01 - Frequency limited for this reason
10 - Error
11 - Not Available";
CM_ SG_ 2565918206 PLedDueToCtrlTemp "Output power is being limited due to the controller temperature (see SPN 9231) approaching or exceeding the maximum limit.

00 - No power limit for this reason
01 -  Power limited for this reason
10 - Error
11 - Not Available";
CM_ SG_ 2565918206 FreqCmdExceedsMax "Output frequency is being limited due to frequency command (see SPN 8347) approaching or exceeding the maximum limit (SPN 8342).

00 - No frequency limit for this reason
01 - Frequency limited for this reason
10 - Error
11 - Not Available";
CM_ SG_ 2565918206 FreqCmdBelowMin "Output frequency is being limited due to frequency command (see SPN 8347) approaching or falling below the minimum limit (SPN 8343).

00 - No frequency limit for this reason
01 - Frequency limited for this reason
10 - Error
11 - Not Available";
CM_ SG_ 2565918206 PLedDueToDCSideVMin "Output power is being limited due to DC Side input voltage (see SPN 9237) approaching or falling below the minimum limit (SPN 9255).

00 - No power limit for this reason
01 - Power limited for this reason
10 - Error
11 - Not Available";
CM_ SG_ 2565918206 PLedDueToACSideRMSCur "AC Side Output power is being limited due to AC Side output RMS current (see SPN 9201) approaching or exceeding the maximum limit (See SPN 9258).
00 - No power limit for this reason
01 - Power limited for this reason
10 - Error
11 - Not ...";
CM_ SG_ 2565918206 PLedDueToDCSideCur "Output power is being limited due to DC Side input current (see SPN 9238) approaching or exceeding the maximum limit (See SPN 9256).

00 - No power limit for this reason
01 - Power limited for this reason
10 - Error
11 - Not Available";
CM_ BO_ 2364591358 "DC/AC Accessory Inverter 2 Voltage
Low Voltage data from DC/AC Accessory Inverter.";
CM_ SG_ 2364591358 SLIV "Low voltage (SLI) supplied to the DC/AC Accessory Inverter controller.";
CM_ SG_ 2364591358 IgntV "Ignition voltage supplied to the  DC/AC Accessory Inverter controller.";
CM_ BO_ 2364591102 "DC/AC Accessory Inverter 2 Status 2
Additional data reported from DC/AC Accessory Inverter";
CM_ SG_ 2364591102 DCSideNegToChassisGroundV "The voltage level of the high voltage DC side, as measured by the DC/AC between the negative side of the High Voltage DC Side input and the chassis of the DC/AC enclosure.  This voltage can be used for system level monitoring of DC Side High Voltage ...";
CM_ SG_ 2364591102 DCSideCur "DC Side input current measured at the point of control inside the DC/AC Accessory Inverter.";
CM_ SG_ 2364591102 DCSideV "DC Side input voltage measured at the point of control inside the DC/AC Accessory Inverter.";
CM_ SG_ 2364591102 DCSidePwr "Power measured at the DC Side input to the DC/AC Accessory Inverter.";
CM_ BO_ 2565917438 "DC/AC Accessory Inverter 1 Feedback 2
Sent by this Accessory Inverter instance and contains the current operating conditions of this output of the inverter.  This message would be received by a controller application (e.g. Power System Manager) ...";
CM_ SG_ 2565917438 PLedDueToUndefinedReason "Output power is being limited due to an undefined reason.

00 - No power limit for this reason
01 - Power limited for this reason
10 - Error
11 - Not Available";
CM_ SG_ 2565917438 PLedDueToRateOfChangeLmt "Output power is being limited due to the frequency approaching or exceeding the rate of change limit (see SPN 8332).

00 - No frequency limit for this reason
01 - Frequency limited for this reason
10 - Error
11 - Not Available";
CM_ SG_ 2565917438 PLedDueToPwrETemp "Output power is being limited due to power electronics temperature (see SPN 9206) approaching or exceeding the maximum limit.

00 - No frequency limit for this reason
01 - Frequency limited for this reason
10 - Error
11 - Not Available";
CM_ SG_ 2565917438 PLedDueToEFilterTemp "Output power is being limited due to electronic filter temperature (see SPN 9205) approaching or exceeding the maximum limit.

00 - No frequency limit for this reason
01 - Frequency limited for this reason
10 - Error
11 - Not Available";
CM_ SG_ 2565917438 PLedDueToCtrlTemp "Output power is being limited due to the controller temperature (see SPN 9204) approaching or exceeding the maximum limit.

00 - No power limit for this reason
01 - Power limited for this reason
10 - Error
11 - Not Available";
CM_ SG_ 2565917438 FreqCmdExceedsMax "Output frequency is being limited due to frequency command (see SPN 8333) approaching or exceeding the maximum limit (SPN 8328).

00 - No frequency limit for this reason
01 - Frequency limited for this reason
10 - Error
11 - Not Available";
CM_ SG_ 2565917438 FreqCmdBelowMin "Output frequency is being limited due to frequency command (see SPN 8333) approaching or falling below the minimum limit (SPN 8329).

00 - No frequency limit for this reason
01 - Frequency limited for this reason
10 - Error
11 - Not Available";
CM_ SG_ 2565917438 PLedDueToDCSideVMin "Output power is being limited due to DC Side input voltage (see SPN 8890) approaching or falling below the minimum limit (SPN 9225).

00 - No power limit for this reason
01 - Power limited for this reason
10 - Error
11 - Not Available";
CM_ SG_ 2565917438 PLedDueToACSideRMSCur "AC Side Output power is being limited due to AC Side output RMS current (see SPN 9200) approaching or exceeding the maximum limit (See SPN 9228).
00 - No power limit for this reason
01 - Power limited for this reason
10 - Error
11 - Not ...";
CM_ SG_ 2565917438 PLedDueToDCSideCur "Output power is being limited due to DC Side input current (see SPN 8891) approaching or exceeding the maximum limit (See SPN 9226).

00 - No power limit for this reason
01 - Power limited for this reason
10 - Error
11 - Not Available";
CM_ BO_ 2364590590 "DC/AC Accessory Inverter 1 Voltage
Low Voltage data from DC/AC Accessory Inverter.";
CM_ SG_ 2364590590 SLIV "Low voltage (SLI) supplied to the DC/AC Accessory Inverter controller.";
CM_ SG_ 2364590590 IgntV "Ignition voltage supplied to the  DC/AC Accessory Inverter controller.";
CM_ BO_ 2364590334 "DC/AC Accessory Inverter 1 Status 2
Additional data reported from DC/AC Accessory Inverter";
CM_ SG_ 2364590334 DCSideNegToChassisGroundV "The voltage level of the high voltage DC side, as measured by the DC/AC between the negative side of the High Voltage DC Side input and the chassis of the DC/AC enclosure.  This voltage can be used for system level monitoring of DC Side High Voltage ...";
CM_ SG_ 2364590334 DCSideCur "DC Side input current measured at the point of control inside the DC/AC Accessory Inverter.";
CM_ SG_ 2364590334 DCSideV "DC Side input voltage measured at the point of control inside the DC/AC Accessory Inverter.";
CM_ SG_ 2364590334 DCSidePwr "Power measured at the DC Side input to the DC/AC Accessory Inverter.";
CM_ BO_ 2624519934 "Configurable Receive SPNs Command
PGN 28160 and PGN 64462 are used to manage and report configurable parameters that are received by a Configurable ECU. PGN 28160 is used by an ECU to request the current receive parameter configuration or to ...";
CM_ SG_ 2624519934 CommandedReceiveSPNSA "The source address from which the Configurable ECU shall receive the SPN identified in SPN 8839.
0 to 253 -  Source Address that the Configurable ECU should use to receive the Configurable Receive SPN.
254 - The command in SPN 8840 applies to all ...";
CM_ SG_ 2624519934 CommandedReceiveSPNReqSt "Identifies the receive enable state being commanded for the specified SPN on the port identified in SPN 8837. This parameter is only valid when SPN 8838 is set to 멌onfigure Port Receive State� (1). For transaction modes where this parameter is not ...";
CM_ SG_ 2624519934 CommandedReceiveSPN "Identifies the SPN to be acted on by the associated SPN 8840.";
CM_ SG_ 2624519934 TransactionMode "Identifies the command or action being commanded to the target Configurable ECU of this instance of PGN 28160.
0000 - Request Port Receive Status - Identifies the message as a request for the list of configurable receive SPNs on the port identified ...";
CM_ SG_ 2624519934 CommandedPort "Identifies the ECU communication port of the target Configurable ECU for this instance of PGN 28160. The identification of each ECU communication port is ECU specific. The correlation of ECU communication port to a physical network connection is ...";
CM_ BO_ 2557345534 "Well Stimulation Pump System Configuration Command
Configures the threshold of operating parameters of a well stimulation pump used in oil and gas drilling applications.
See PGN 64461 for the feedback of current settings of the operating ...";
CM_ SG_ 2557345534 PlungerFiringOrder "Well stimulation pump plunger firing order
0000 - Firing order 1-2-3
0001 - Firing order 1-5-2-3-4
0010 - Reserved
0011 - Reserved
0100 - Reserved
0101 - Reserved
0110 - Reserved
0111 - Reserved
1000 - Reserved
1001 - Reserved
1010 - ...";
CM_ SG_ 2557345534 RodLoadHiThreshold "Rod load force at which the rod load is considered at the highest acceptable force.";
CM_ SG_ 2557345534 CrankshaftSpdHiThreshold "Well stimulation pump crankshaft speed that has been considered to be the highest acceptable speed.";
CM_ SG_ 2557345534 CrankshaftSpdLowThreshold "The minimum speed of Well stimulation pump crankshaft that is considered to be valid.";
CM_ SG_ 2557345534 DisPressHiThreshold "Pressure at which the discharge pressure is considered at the highest acceptable pressure.";
CM_ SG_ 2557345534 SuctionPressHiThreshold "Pressure at which the suction pressure is considered at the highest acceptable pressure.";
CM_ SG_ 2557345534 SuctionPressLowThreshold "Pressure at which the suction pressure is considered at the lowest acceptable pressure.";
CM_ SG_ 2557345534 GearBoxOilTempHiThreshold "Temperature at which the gearbox oil temperature is considered at the highest acceptable temperature.";
CM_ SG_ 2557345534 GearBoxOilTempLowThreshold "Temperature at which the gearbox oil temperature is considered at the lowest acceptable temperature.";
CM_ SG_ 2557345534 GearBoxOilPressHiThreshold "Pressure at which the gearbox oil pressure is considered at the highest acceptable pressure.";
CM_ SG_ 2557345534 GearBoxOilPressLowThreshold "Pressure at which the gearbox oil pressure is considered at the lowest acceptable pressure.";
CM_ BO_ 2557214462 "Well Stimulation Pump Sensor Calibration Command
Calibration setting commands for the Well Stimulation Pump System.";
CM_ SG_ 2557214462 DisPressCalSetPointCmd "Specifies the current discharge pressure whose calibration status is being reported. Multipoint calibration of the discharge pressure system is perfomed by increasing the pressure with up to 10 known calibration pressures. For each calibration ...";
CM_ SG_ 2557214462 SuctionPressCalSetPointCmd "Specifies the current suction pressure being calibrated. Multipoint calibration of the suction pressure
system is perfomed by increasing the pressure with up to 10 known calibration pressures. For each
calibration pressure, the Well Stimulation ...";
CM_ BO_ 2557148926 "Marine Control Information 2
Marine vessel control information for the vessel control system.";
CM_ SG_ 2557148926 VesselSpdCtrlMode "The vessel set speed type that is selected by the operator.

00h = No Set Speed
01h = Slow Vessel Mode
02h = Synchronization Mode
03h = Trolling Mode
04h - FDh = Reserved
FEh = Error
FFh = Not Available";
CM_ SG_ 2557148926 VesselEngSetSpd "The (chosen) vessel speed that has been selected by the operator.";
CM_ SG_ 2557148926 TrollingModeCurSetting "The current setting of the Trolling Mode.  In traditional trolling mode, engine speed remains constant while the throttle lever changes the amount of slip within the transmission clutches. In advanced trolling mode, the throttle lever controls ...";
CM_ SG_ 2557148926 TrollingMode "The active status of the Trolling Mode (Extended Range). In traditional trolling mode, engine speed remains constant while the throttle lever changes the amount of slip within the transmission clutches. In advanced trolling mode, the throttle lever ...";
CM_ SG_ 2557148926 EngThrotSynchModeCurSetting "The current setting of the engine throttle synchronization mode. Throttle synchronization mode indicates which throttle, if any, is to be used for the synchronized throttle.
0000b - Not Synchronized
0001b - Synchronized Center
0010b - ...";
CM_ SG_ 2557148926 OpStationLockout "Indicates the status of a lockout to prevent changing the active control station. Lockout active indicates a change is not permitted to the active control station.
00b - Station Lockout Inactive
01b - Station Lockout Active
10b - Error
11b - Not ...";
CM_ SG_ 2557148926 OpStationInCtrlLocation "Identifies the location of the operator station that is currently in control of the system.
00h = Bridge
01h = Port Wing
02h = Starboard Wing
03h = Tower
04h = Engine Room
05h = Aft. Station
06h = Fly Bridge
07h = Bow Station
08h-FDh = ...";
CM_ BO_ 2557083390 "Marine Control Information Configuration 1
Marine vessel control configuration information for the vessel control system.";
CM_ SG_ 2557083390 EngTrollingModeSetSpd "The (chosen) vessel trolling speed that has been selected by the operator";
CM_ SG_ 2557083390 EngThrotSynchModeCmd "The setting of the throttle synchronization mode. Throttle synchronization mode is used to indicate which throttle, if any, is used to be used for the synchronized throttle.
0000b - Not Synchronized
0001b - Synchronized Center
0010b - ...";
CM_ SG_ 2557083390 TrollingModeSettingCmd "The commanded setting of the Trolling Mode.  In traditional trolling mode, engine speed remains constant while the throttle lever changes the amount of slip within the transmission clutches. In advanced trolling mode, the throttle lever controls ...";
CM_ SG_ 2557083390 OpStationLocationSetting "Configurable location of the selected operator station.
00h = Bridge
01h = Port Wing
02h = Starboard Wing
03h = Tower
04h = Engine Room
05h = Aft. Station
06h = Fly Bridge
07h = Bow Station
08h-FDh = Reserved
FEh = Error
FFh = Not ...";
CM_ BO_ 2633785086 "High Voltage Energy Storage 1 History
Historical data for High Voltage Energy Storage pack (or system) 1.";
CM_ SG_ 2633785086 TotalAccumulatedCharge "The total accumulated amp hours which have flowed through High Voltage Energy Storage 1 pack (or system).  This parameter is the sum of the absolute values of the Ampere hours into and out of HVES1.";
CM_ SG_ 2633785086 TotalEnergyThroughput "The total energy throughput which has flowed through High Voltage Energy Storage 1 pack (or system).  This parameter is the sum of the absolute values of the Energy into and out of HVES1.";
CM_ SG_ 2633785086 ContactorOpenUnderLoadCount "This signal represents the number of times the contactors inside the High Voltage Energy Storage 1 pack (or system) have opened while current is flowing through them.  The current level (that determines if an opening event will be counted) shall be ...";
CM_ SG_ 2633785086 StOfHealth "This signal represents the expected remaining \"Life\" of the High Voltage Energy Storage 1 pack (or system), in percent.  Battery life is a manufacturer-specific measure of how well the energy storage system is functioning relative to its nominal ...";
CM_ BO_ 2566675966 "High Voltage Energy Storage 1 Configuration
Configuration data for High Voltage Energy Storage pack (or system) 1.  Note that configuration data should not dynamically change during vehicle operation.";
CM_ SG_ 2566675966 CellMinVLmt "Per the HVES manufacturer, this is the minimum cell voltage for High Voltage Energy Storage 1 pack (or system) operation.  Operating below this value may damage HVES hardware, or compromise HVES life.";
CM_ SG_ 2566675966 CellMaxVLmt "Per the HVES manufacturer, this is the maximum cell voltage for High Voltage Energy Storage 1 pack (or system) operation.  Operating above this value may damage HVES hardware, or compromise HVES life.";
CM_ SG_ 2566675966 RecommendedMinOperatingTemp "Per the HVES manufacturer, this is the recommended minimum temperature for High Voltage Energy Storage 1 pack (or system) operation.  Operating below this value may damage HVES hardware, or compromise HVES life.";
CM_ SG_ 2566675966 RecommendedMaxOperatingTemp "Per the HVES manufacturer, this is the recommended maximum temperature for High Voltage Energy Storage 1 pack (or system) operation.  Operating above this value may damage HVES hardware, or compromise HVES life.";
CM_ SG_ 2566675966 RecommendedMaxStOfCharge "Per the HVES manufacturer, this is the recommended maximum state of charge for High Voltage Energy Storage 1 pack (or system) operation.  Operating above this value may compromise HVES life.";
CM_ SG_ 2566675966 RecommendedMinStOfCharge "Per the HVES manufacturer, this is the recommended minimum state of charge for High Voltage Energy Storage 1 pack (or system) operation.  Operating below this value may compromise HVES life.";
CM_ SG_ 2566675966 RecommendedMaxOperatingV "Per the HVES manufacturer, this is the maximum recommended voltage level for High Voltage Energy Storage 1 pack (or system) operation.  Operating above this value may compromise HVES life.";
CM_ SG_ 2566675966 RecommendedMinOperatingV "Per the HVES manufacturer, this is the minimum recommended voltage level for High Voltage Energy Storage 1 pack (or system) operation.  Operating below this value may compromise HVES life.";
CM_ SG_ 2566675966 NominalV "Per the HVES manufacturer, this is the nominal operating voltage of the High Voltage Energy Storage 1 pack (or system), e.g. �300V� or �600V�.";
CM_ BO_ 2566661886 "Aftertreatment 2 Diesel Exhaust Fluid Information 2
Sensor Information which measures temperature, concentration, and conductivity of the diesel exhaust fluid of the aftertreatment 2 system.";
CM_ SG_ 2566661886 Ctrl2Temp "Temperature of the diesel exhaust fluid at the aftertreatment 2 diesel exhaust fluid controller 2.";
CM_ SG_ 2566661886 CtrlTemp "Temperature of the diesel exhaust fluid at the aftertreatment 2 diesel exhaust fluid controller.";
CM_ BO_ 2566656254 "Ambient Conditions 3
This message contains measurement and configuration information about the vehicle ambient conditions.";
CM_ SG_ 2566656254 EngIn2AirTemp "Temperature of air entering through a second vehicle air induction system.";
CM_ SG_ 2566656254 BarometricAbsPress2 "Second absolute air pressure measurement of the atmosphere.

See SPN 108 or SPN 5685 as the primary barometric pressure measurement.";
CM_ BO_ 2566655998 "Secondary or Front Hitch Roll and Pitch Sensitivity
Provides current sensitivity of the front hitch roll and pitch control loops.";
CM_ SG_ 2566655998 PitchSensitivity "The current sensitivity of the front hitch pitch control expressed as a percentage of the maximum gain.  0% indicates minimal gain in the control loop; 100%, the maximum gain. Values near zero may result in no reaction by the control loop.";
CM_ SG_ 2566655998 Sensitivity "The current sensitivity of the front hitch roll control expressed as a percentage of the maximum gain.  0% indicates minimal gain in the control loop; 100%, the maximum gain. Values near zero may result in no reaction by the control loop.";
CM_ BO_ 2566655742 "Primary or Rear Hitch Roll and Pitch Sensitivity
Provides current sensitivity of the rear hitch roll and pitch control loops.";
CM_ SG_ 2566655742 PitchSensitivity "The current sensitivity of the rear hitch pitch control expressed as a percentage of the maximum gain.  0% indicates minimal gain in the control loop; 100%, the maximum gain. Values near zero may result in no reaction by the control loop.";
CM_ SG_ 2566655742 Sensitivity "The current sensitivity of the rear hitch roll control expressed as a percentage of the maximum gain.  0% indicates minimal gain in the control loop; 100%, the maximum gain. Values near zero may result in no reaction by the control loop.";
CM_ BO_ 2633764350 "Fire Pump Statistics 1
Contains statistics of the fire apparatus pump.";
CM_ SG_ 2633764350 EngagementCycles "Accumulated number of times the fire pump has been engaged.";
CM_ SG_ 2633764350 OpTime "Accumulated time that the fire pump is enaged.";
CM_ BO_ 2633764094 "Evaporative Systems
This message contains data for the evaporative emissions system";
CM_ SG_ 2633764094 GasolineFuelTankPress "The gage pressure of the vapor in the gasoline fuel tank.";
CM_ SG_ 2633764094 CanisterPurgeVlvCmd "The commanded positon of the canister purge valve used to allow fuel vapors from the charcoal canister into the intake manifold.

A value of 0 % indicates fully closed, a value of 100 % indicates fully open.";
CM_ SG_ 2633764094 CanisterVentVlv "The state of the canister vent value used to allow fresh air into the charcoal vapor canister.

00 - Vent Valve is Closed
01 - Vent Valve is Open
10 - Error
11 - Not Available";
CM_ BO_ 2566654974 "Electronic Engine Controller 20";
CM_ SG_ 2566654974 ActualMaxAvailableEngPercentFuel "The percent of torque limited fuel relative to the engine standard torque fuel.  The torque limited fuel in the Actual Maximum Available Engine - Percent Fuel shall take into consideration all engine torque derates (e.g. fault / event derates, ...";
CM_ SG_ 2566654974 EstEngParasiticLossesPercentTrq "Indicates the estimated amount of torque loss due to engine parasitics, such as cooling fan, air compressor, air conditioning, etc. It is expressed as a percent of Engine Reference Torque.
If there are multiple devices on a network that provide ...";
CM_ BO_ 2566654718 "Vehicle Electrical Power 7
Parameters of the first battery in the first set of batteries (battery pack) used for starting the engine, for lighting, and for ignition (SLI).";
CM_ SG_ 2566654718 SLIBatPack1Bat1V "Voltage of the first battery in the first set of batteries (battery pack) used for starting the engine, for lighting, and for ignition (SLI). 

The relation to physical location is determined by the equipment manufacturer.";
CM_ SG_ 2566654718 SLIBatPack1Bat1Temp "Temperature of the first battery in the first set of batteries (battery pack) used for starting the engine, for lighting, and for ignition (SLI). 

The relation to physical location is determined by the equipment manufacturer.";
CM_ SG_ 2566654718 SLIBatPack1Bat1NetCur "Net flow of electrical current into/out of the first battery in the first set of batteries (battery pack) used for starting the engine, for lighting, and for ignition (SLI).";
CM_ BO_ 2566654462 "Vehicle Electrical Power 8
Parameters of the first battery in the first set of batteries (battery pack) used for starting the engine, for lighting, and for ignition (SLI).";
CM_ SG_ 2566654462 SLIBatPack1Snsr1InitStatus "The battery sensor may go through an initialization process when it is first connected to a battery.  This parameter reports the battery sensor's progress through the initialization process.
0:                          Initialization process has ...";
CM_ SG_ 2566654462 SLIBatPack1Bat1PredMinCrankingV "Prediction of the minimum battery voltage of the first battery in the first battery pack used for starting the engine, for lighting, and for ignition (SLI) during a crank event, under present battery conditions.
Parameter Specific Indicator:
A ...";
CM_ SG_ 2566654462 SLIBatPack1Bat1Health "Capacity of the first battery in the first battery pack relative to its original specification for the battery pack used for starting the engine, for lighting, and for ignition (SLI). 0% means battery pack is not capable of holding any charge, 100% ...";
CM_ SG_ 2566654462 SLIBatPack1Bat1Capacity "Total reserve capacity of the first battery in the first battery pack used for starting the engine, for lighting, and for ignition (SLI).  This value could be the original capacity, rated capacity, or the capacity received in SPN 9368.
Parameter ...";
CM_ SG_ 2566654462 SLIBatPack1Bat1StOfCharge "Indicates the remaining charge of the first battery in the first battery pack used for starting the engine, for lighting, and for ignition (SLI). 0% means no charge remaining, 100% means full capacity at the battery's current state of health.
 ...";
CM_ BO_ 2566654206 "Vehicle Electrical Power 9
Parameters of the second battery in the first set of batteries (battery pack) used for starting the engine, for lighting, and for ignition (SLI).";
CM_ SG_ 2566654206 SLIBatPack1Bat2V "Voltage of the second battery in the first set of batteries (battery pack) used for starting the engine, for lighting, and for ignition (SLI). 

The relation to physical location is determined by the equipment manufacturer.";
CM_ SG_ 2566654206 SLIBatPack1Bat2Temp "Temperature of the second battery in the first set of batteries (battery pack) used for starting the engine, for lighting, and for ignition (SLI). 

The relation to physical location is determined by the equipment manufacturer.";
CM_ SG_ 2566654206 SLIBatPack1Bat2NetCur "Net flow of electrical current into/out of the second battery in the first set of batteries (battery pack) used for starting the engine, for lighting, and for ignition (SLI).";
CM_ BO_ 2566653950 "Vehicle Electrical Power 10
Parameters of the second battery in the first set of batteries (battery pack) used for starting the engine, for lighting, and for ignition (SLI).";
CM_ SG_ 2566653950 SLIBatPack1Snsr2InitStatus "The battery sensor may go through an initialization process when it is first connected to a battery.  This parameter reports the battery sensor's progress through the initialization process.
0:                          Initialization process has ...";
CM_ SG_ 2566653950 SLIBatPack1Bat2PredMinCrankingV "Prediction of the minimum battery voltage of the second battery in the first battery pack used for starting the engine, for lighting, and for ignition (SLI) during a crank event, under present battery conditions.
Parameter Specific Indicator:
A ...";
CM_ SG_ 2566653950 SLIBatPack1Bat2Health "Capacity of the second battery in the first battery pack relative to its original specification for the battery pack used for starting the engine, for lighting, and for ignition (SLI). 0% means battery pack is not capable of holding any charge, 100% ...";
CM_ SG_ 2566653950 SLIBatPack1Bat2Capacity "Total reserve capacity of the second battery in the first battery pack used for starting the engine, for lighting, and for ignition (SLI).  This value could be the original capacity, rated capacity, or the capacity received in SPN 9369.
Parameter ...";
CM_ SG_ 2566653950 SLIBatPack1Bat2StOfCharge "Indicates the remaining charge of the second battery in the first battery pack used for starting the engine, for lighting, and for ignition (SLI). 0% means no charge remaining, 100% means full capacity at the battery's current state of health.
 ...";
CM_ BO_ 2566653694 "Vehicle Electrical Power 11
Parameters of the third battery in the first set of batteries (battery pack) used for starting the engine, for lighting, and for ignition (SLI).";
CM_ SG_ 2566653694 SLIBatPack1Bat3V "Voltage of the third battery in the first set of batteries (battery pack) used for starting the engine, for lighting, and for ignition (SLI). 

The relation to physical location is determined by the equipment manufacturer.";
CM_ SG_ 2566653694 SLIBatPack1Bat3Temp "Temperature of the third battery in the first set of batteries (battery pack) used for starting the engine, for lighting, and for ignition (SLI). 

The relation to physical location is determined by the equipment manufacturer.";
CM_ SG_ 2566653694 SLIBatPack1Bat3NetCur "Net flow of electrical current into/out of the third battery in the first set of batteries (battery pack) used for starting the engine, for lighting, and for ignition (SLI).";
CM_ BO_ 2566653438 "Vehicle Electrical Power 12
Parameters of the third battery in the first set of batteries (battery pack) used for starting the engine, for lighting, and for ignition (SLI).";
CM_ SG_ 2566653438 SLIBatPack1Snsr3InitStatus "The battery sensor may go through an initialization process when it is first connected to a battery.  This parameter reports the battery sensor's progress through the initialization process.
0:                          Initialization process has ...";
CM_ SG_ 2566653438 SLIBatPack1Bat3PredMinCrankingV "Prediction of the minimum battery voltage of the third battery in the first battery pack used for starting the engine, for lighting, and for ignition (SLI) during a crank event, under present battery conditions.
Parameter Specific Indicator:
A ...";
CM_ SG_ 2566653438 SLIBatPack1Bat3Health "Capacity of the third battery in the first battery pack relative to its original specification for the battery pack used for starting the engine, for lighting, and for ignition (SLI). 0% means battery pack is not capable of holding any charge, 100% ...";
CM_ SG_ 2566653438 SLIBatPack1Bat3Capacity "Total reserve capacity of the third battery in the first battery pack used for starting the engine, for lighting, and for ignition (SLI).  This value could be the original capacity, rated capacity, or the capacity received in SPN 9370.
Parameter ...";
CM_ SG_ 2566653438 SLIBatPack1Bat3StOfCharge "Indicates the remaining charge of the third battery in the first battery pack used for starting the engine, for lighting, and for ignition (SLI). 0% means no charge remaining, 100% means full capacity at the battery's current state of health.
 ...";
CM_ BO_ 2566653182 "Vehicle Electrical Power 13
Parameters of the fourth battery in the first set of batteries (battery pack) used for starting the engine, for lighting, and for ignition (SLI).";
CM_ SG_ 2566653182 SLIBatPack1Bat4V "Voltage of the fourth battery in the first set of batteries (battery pack) used for starting the engine, for lighting, and for ignition (SLI). 

The relation to physical location is determined by the equipment manufacturer.";
CM_ SG_ 2566653182 SLIBatPack1Bat4Temp "Temperature of the fourth battery in the first set of batteries (battery pack) used for starting the engine, for lighting, and for ignition (SLI). 

The relation to physical location is determined by the equipment manufacturer.";
CM_ SG_ 2566653182 SLIBatPack1Bat4NetCur "Net flow of electrical current into/out of the fourth battery in the first set of batteries (battery pack) used for starting the engine, for lighting, and for ignition (SLI).";
CM_ BO_ 2566652926 "Vehicle Electrical Power 14
Parameters of the fourth battery in the first set of batteries (battery pack) used for starting the engine, for lighting, and for ignition (SLI).";
CM_ SG_ 2566652926 SLIBatPack1Snsr4InitStatus "The battery sensor may go through an initialization process when it is first connected to a battery.  This parameter reports the battery sensor's progress through the initialization process.
0:                          Initialization process has ...";
CM_ SG_ 2566652926 SLIBatPack1Bat4PredMinCrankingV "Prediction of the minimum battery voltage of the fourth battery in the first battery pack used for starting the engine, for lighting, and for ignition (SLI) during a crank event, under present battery conditions.
Parameter Specific Indicator:
A ...";
CM_ SG_ 2566652926 SLIBatPack1Bat4Health "Capacity of the fourth battery in the first battery pack relative to its original specification for the battery pack used for starting the engine, for lighting, and for ignition (SLI). 0% means battery pack is not capable of holding any charge, 100% ...";
CM_ SG_ 2566652926 SLIBatPack1Bat4Capacity "Total reserve capacity of the fourth battery in the first battery pack used for starting the engine, for lighting, and for ignition (SLI).  This value could be the original capacity, rated capacity, or the capacity received in SPN 9371.
Parameter ...";
CM_ SG_ 2566652926 SLIBatPack1Bat4StOfCharge "Indicates the remaining charge of the fourth battery in the first battery pack used for starting the engine, for lighting, and for ignition (SLI). 0% means no charge remaining, 100% means full capacity at the battery's current state of health.
 ...";
CM_ BO_ 2566652670 "SCR System Information
Includes parameters related to the SCR system.";
CM_ SG_ 2566652670 AFT2SCRSysHydrocarbon "The ratio of the mass of hydrocarbon present in the aftertreatment 2 system compared to the maximum allowable mass of hydrocarbon for the aftertreatment system. 100% represents the maximum percentage of hydrocarbon loading that can safely be handled ...";
CM_ SG_ 2566652670 AFT2DEFDosingSysFrozen "All or part of the diesel exhaust fluid system (DEF tank, DEF supply lines, DEF pump, and DEF doser, etc.) in bank 2 is frozen.
In situations where it is desired to report the DEF system frozen as a faulted condition, FMI 31 can be used with this ...";
CM_ SG_ 2566652670 AFT1DEFDosingSysFrozen "All or part of the diesel exhaust fluid system (DEF tank, DEF supply lines, DEF pump, and DEF doser, etc.) in bank 1 is frozen.
In situations where it is desired to report the DEF system frozen as a faulted condition, FMI 31 can be used with this ...";
CM_ SG_ 2566652670 AFT1SCRSysHydrocarbon "The ratio of the mass of hydrocarbon present in the aftertreatment system compared to the maximum allowable mass of hydrocarbon for the aftertreatment system. 100% represents the maximum percentage of hydrocarbon loading that can safely be handled ...";
CM_ SG_ 2566652670 DEFFrozenTime "Indicates the amount of time the diesel exhaust fluid is frozen while key switch is on. This will accumulate over the life of the product, and will never be reset.

This parameter is not for engine applications that are capable of being derated.";
CM_ BO_ 2566652414 "Electrified Accessory Motor Status
The status of electrified Accessory Motor controller.   See PGN 32000 for the corresponding command message.  This PGN should only be used in a case where the specific PGN for the Electrified Accessory is not ...";
CM_ SG_ 2566652414 Instance "Indicates the electrified accessory instance that is providing status.
0000 - Instance 1
0001 - Instance 2
0010 - Instance 3
0011 - Instance 4
0100 - Instance 5
0101 - Instance 6
0110 - Instance 7
0111 - Instance 8
1000 - Instance 9
1001 - ...";
CM_ SG_ 2566652414 OperatingStatus "Indicates the operating status of this Electrified Accessory Motor system or component.  This parameter is used to inform other devices that this system or component is no longer performing to its operational capacity and that reduced, or no flow of ...";
CM_ SG_ 2566652414 ServiceInd "Indicates that service is required for this Electrified Accessory Motor system or component.  An active indication may convey a need for component replacement or periodic service.  The Electrified Accessory Motor Controller Status Reason Code (SPN ...";
CM_ SG_ 2566652414 Pwr "Calculated electrical power consumed by this Electrified Accessory Motor.";
CM_ SG_ 2566652414 MediumTemp "A temperature measured and reported by the device.  It may be used for direct or remote (e.g. by another controller) control of the pump.  For example, this may be the temperature of the fluid flowing through the pump, or some other temperature ...";
CM_ SG_ 2566652414 Spd "Speed of this Electrified Accessory Motor.";
CM_ SG_ 2566652414 CtrlCmdStatus "Indicates the source of the speed command to this Electrified Accessory Motor system or component.
00b is communicated when the controller is self-controlled (e.g. based on a temperature sensor).
01b is communicated when responding to the ...";
CM_ SG_ 2566652414 CtrlStatusReasonCode "Provides the reason code describing the unique failure of this Electrified Accessory Motor system or component.
If a detailed reason code is not used by the supporting application, or this reason code is Not Available, the Electrified Accessory ...";
CM_ SG_ 2566652414 EnableStatus "Enable and direction status of this Electrified Accessory Motor system or component.

00 - Accessory Motor Off
01 - Accessory Motor On - Normal, Forward, or Default Direction
10 - Accessory Motor On - Reverse Direction
11 - Not available";
CM_ BO_ 2566651902 "Electrified Accessory Power Electronics Coolant Pump Status
The status of electrified Accessory: Power Electronics Coolant Pump.   See PGN 31488 for the corresponding command message.";
CM_ SG_ 2566651902 OperatingStatus "Indicates the operating status of the Power Electronics Coolant Pump system or component.
This parameter is used to inform other devices that this system or component is no longer performing to its operational capacity and that reduced, or no flow, ...";
CM_ SG_ 2566651902 ServiceInd "Indicates that service is required for the Power Electronics Coolant Pump system or component.
An active indication may convey a need for component replacement or periodic service.  The Power Electronics Coolant Pump Controller Status Reason Code ...";
CM_ SG_ 2566651902 Pwr "Calculated electrical power consumed by the Power Electronics Coolant Pump.";
CM_ SG_ 2566651902 CtrlTemp "A temperature measured and reported by the device.  It may be used for direct or remote (e.g. by another controller) control of the pump.  For example, this may be the temperature of the fluid flowing through the pump, or some other temperature ...";
CM_ SG_ 2566651902 MotorSpd "Motor Speed of the Power Electronics Coolant Pump.";
CM_ SG_ 2566651902 CtrlCmdStatus "Indicates the source of the speed command to the Power Electronics Coolant Pump system or component.
00b is communicated when the controller is self-controlled  (e.g. based on a temperature sensor).
01b is communicated when responding to the Power ...";
CM_ SG_ 2566651902 CtrlStatusReasonCode "Provides the reason code describing the unique failure of the Power Electronics Coolant Pump system or component.
If a detailed reason code is not used by the supporting application, or this reason code is Not Available, the Power Electronics ...";
CM_ SG_ 2566651902 EnableStatus "Enable and direction status of the Power Electronics Coolant Pump system or component.

00 - Accessory Motor Off
01 - Accessory Motor On - Normal, Forward, or Default Direction
10 - Accessory Motor On - Reverse Direction
11 - Not available";
CM_ BO_ 2566651646 "Electrified Accessory Propulsion Motor Coolant Pump Status
The status of electrified Accessory: Propulsion Motor Coolant Pump.   See PGN 31232 for the corresponding command message.";
CM_ SG_ 2566651646 OperatingStatus "Indicates the operating status of the Propulsion Motor Coolant Pump system or component.
This parameter is used to inform other devices that this system or component is no longer performing to its operational capacity and that reduced, or no flow, ...";
CM_ SG_ 2566651646 ServiceInd "Indicates that service is required for the Propulsion Motor Coolant Pump system or component.
An active indication may convey a need for component replacement or periodic service.  The Propulsion Motor Coolant Pump Controller Status Reason Code ...";
CM_ SG_ 2566651646 Pwr "Calculated electrical power consumed by the Propulsion Motor Coolant Pump.";
CM_ SG_ 2566651646 CtrlTemp "A temperature measured and reported by the device.  It may be used for direct or remote (e.g. by another controller) control of the pump.  For example, this may be the temperature of the fluid flowing through the pump, or some other temperature ...";
CM_ SG_ 2566651646 MotorSpd "Motor Speed of the Propulsion Motor Coolant Pump.";
CM_ SG_ 2566651646 CtrlCmdStatus "Indicates the source of the speed command to the Propulsion Motor Coolant Pump system or component.
00b is communicated when the controller is self-controlled  (e.g. based on a temperature sensor).
01b is communicated when responding to the ...";
CM_ SG_ 2566651646 CtrlStatusReasonCode "Provides the reason code describing the unique failure of the Propulsion Motor Coolant Pump system or component.
If a detailed reason code is not used by the supporting application, or this reason code is Not Available, the Propulsion Motor Coolant ...";
CM_ SG_ 2566651646 EnableStatus "Enable and direction status of the Propulsion Motor Coolant Pump system or component.

00 - Accessory Motor Off
01 - Accessory Motor On - Normal, Forward, or Default Direction
10 - Accessory Motor On - Reverse Direction
11 - Not available";
CM_ BO_ 2566651390 "Electrified Accessory Propulsion Motor Oil Pump Status
The status of electrified Accessory: Propulsion Motor Oil Pump.   See PGN 30976 for the corresponding command message.";
CM_ SG_ 2566651390 OperatingStatus "Indicates the operating status of the Propulsion Motor Oil Pump system or component.
This parameter is used to inform other devices that this system or component is no longer performing to its operational capacity and that reduced, or no flow, of ...";
CM_ SG_ 2566651390 ServiceInd "Indicates that service is required for the Propulsion Motor Oil Pump system or component.
An active indication may convey a need for component replacement or periodic service.  The Propulsion Motor Oil Pump Controller Status Reason Code (SPN 7996) ...";
CM_ SG_ 2566651390 Pwr "Calculated electrical power consumed by the Propulsion Motor Oil Pump.";
CM_ SG_ 2566651390 CtrlTemp "A temperature measured and reported by the device.  It may be used for direct or remote (e.g. by another controller) control of the pump.  For example, this may be the temperature of the fluid flowing through the pump, or some other temperature ...";
CM_ SG_ 2566651390 MotorSpd "Motor Speed of the Propulsion Motor Oil Pump.";
CM_ SG_ 2566651390 CtrlCmdStatus "Indicates the source of the speed command to the Propulsion Motor Oil Pump system or component.
00b is communicated when the controller is self-controlled  (e.g. based on a temperature sensor).
01b is communicated when responding to the Propulsion ...";
CM_ SG_ 2566651390 CtrlStatusReasonCode "Provides the reason code describing the unique failure of the Propulsion Motor Oil Pump system or component.
If a detailed reason code is not used by the supporting application, or this reason code is Not Available, the Propulsion Motor Oil Pump ...";
CM_ SG_ 2566651390 EnableStatus "Enable and direction status of the Propulsion Motor Oil Pump system or component.

00 - Accessory Motor Off
01 - Accessory Motor On - Normal, Forward, or Default Direction
10 - Accessory Motor On - Reverse Direction
11 - Not available";
CM_ BO_ 2566651134 "Electrified Accessory Power Electronics Coolant Fan 1 Status
The status of electrified Accessory: Power Electronics Coolant Fan 1.   See PGN 30720 for the corresponding command message.";
CM_ SG_ 2566651134 OperatingStatus "Indicates the operating status of the Power Electronics Coolant Fan 1 system or component.
This parameter is used to inform other devices that this system or component is no longer performing to its operational capacity and that reduced, or no ...";
CM_ SG_ 2566651134 ServiceInd "Indicates that service is required for the Power Electronics Coolant Fan 1 system or component.
An active indication may convey a need for component replacement or periodic service.  The Power Electronics Coolant Fan 1 Controller Status Reason Code ...";
CM_ SG_ 2566651134 Pwr "Calculated electrical power consumed by the Power Electronics Coolant Fan 1.";
CM_ SG_ 2566651134 CtrlTemp "A temperature measured and reported by the device.  It may be used for direct or remote (by another controller) control of the Fan 1.  For example, this may be the temperature of the fluid flowing through the Fan 1, or some other temperature ...";
CM_ SG_ 2566651134 MotorSpd "Motor Speed of the Power Electronics Coolant Fan 1.";
CM_ SG_ 2566651134 CtrlCmdStatus "Indicates the source of the speed command to the Power Electronics Coolant Fan 1 system or component.
00b is communicated when the controller is self-controlled  (e.g. based on a temperature sensor).
01b is communicated when responding to the ...";
CM_ SG_ 2566651134 CtrlStatusReasonCode "Provides the reason code describing the unique failure of the Power Electronics Coolant Fan 1 system or component.
If a detailed reason code is not used by the supporting application, or this reason code is Not Available, the Power Electronics ...";
CM_ SG_ 2566651134 EnableStatus "Enable and direction status of the Power Electronics Coolant Fan 1 system or component.

00 - Accessory Motor Off
01 - Accessory Motor On - Normal, Forward, or Default Direction
10 - Accessory Motor On - Reverse Direction
11 - Not available";
CM_ BO_ 2566650878 "Electrified Accessory Power Electronics Coolant Fan 2 Status
The status of electrified Accessory: Power Electronics Coolant Fan 2.   See PGN 30464 for the corresponding command message.";
CM_ SG_ 2566650878 OperatingStatus "Indicates the operating status of the Power Electronics Coolant Fan 2 system or component.
This parameter is used to inform other devices that this system or component is no longer performing to its operational capacity and that reduced, or no ...";
CM_ SG_ 2566650878 ServiceInd "Indicates that service is required for the Power Electronics Coolant Fan 2 system or component.
An active indication may convey a need for component replacement or periodic service.  The Power Electronics Coolant Fan 2 Controller Status Reason Code ...";
CM_ SG_ 2566650878 Pwr "Calculated electrical power consumed by the Power Electronics Coolant Fan 2.";
CM_ SG_ 2566650878 CtrlTemp "A temperature measured and reported by the device.  It may be used for direct or remote (by another controller) control of the Fan 2.  For example, this may be the temperature of the fluid flowing through the Fan 2, or some other temperature ...";
CM_ SG_ 2566650878 MotorSpd "Motor Speed of the Power Electronics Coolant Fan 2.";
CM_ SG_ 2566650878 CtrlCmdStatus "Indicates the source of the speed command to the Power Electronics Coolant Fan 2 system or component.
00b is communicated when the controller is self-controlled  (e.g. based on a temperature sensor).
01b is communicated when responding to the ...";
CM_ SG_ 2566650878 CtrlStatusReasonCode "Provides the reason code describing the unique failure of the Power Electronics Coolant Fan 2 system or component.
If a detailed reason code is not used by the supporting application, or this reason code is Not Available, the Power Electronics ...";
CM_ SG_ 2566650878 EnableStatus "Enable and direction status of the Power Electronics Coolant Fan 2 system or component.

00 - Accessory Motor Off
01 - Accessory Motor On - Normal, Forward, or Default Direction
10 - Accessory Motor On - Reverse Direction
11 - Not available";
CM_ BO_ 2566650622 "Electrified Accessory Power Electronics Coolant Fan 3 Status
The status of electrified Accessory: Power Electronics Coolant Fan 3.   See PGN 30208 for the corresponding command message.";
CM_ SG_ 2566650622 OperatingStatus "Indicates the operating status of the Power Electronics Coolant Fan 3 system or component.
This parameter is used to inform other devices that this system or component is no longer performing to its operational capacity and that reduced, or no ...";
CM_ SG_ 2566650622 ServiceInd "Indicates that service is required for the Power Electronics Coolant Fan 3 system or component.
An active indication may convey a need for component replacement or periodic service.  The Power Electronics Coolant Fan 3 Controller Status Reason Code ...";
CM_ SG_ 2566650622 Pwr "Calculated electrical power consumed by the Power Electronics Coolant Fan 3.";
CM_ SG_ 2566650622 CtrlTemp "A temperature measured and reported by the device.  It may be used for direct or remote (by another controller) control of the Fan 3.  For example, this may be the temperature of the fluid flowing through the Fan 3, or some other temperature ...";
CM_ SG_ 2566650622 MotorSpd "Motor Speed of the Power Electronics Coolant Fan 3.";
CM_ SG_ 2566650622 CtrlCmdStatus "Indicates the source of the speed command to the Power Electronics Coolant Fan 3 system or component.
00b is communicated when the controller is self-controlled  (e.g. based on a temperature sensor).
01b is communicated when responding to the ...";
CM_ SG_ 2566650622 CtrlStatusReasonCode "Provides the reason code describing the unique failure of the Power Electronics Coolant Fan 3 system or component.  If a detailed reason code is not used by the supporting application, or this reason code is Not Available, the Power Electronics ...";
CM_ SG_ 2566650622 EnableStatus "Enable and direction status of the Power Electronics Coolant Fan 3 system or component.

00 - Accessory Motor Off
01 - Accessory Motor On - Normal, Forward, or Default Direction
10 - Accessory Motor On - Reverse Direction
11 - Not available";
CM_ BO_ 2566650366 "Electrified Accessory Propulsion Motor Coolant Fan 1 Status
The status of electrified Accessory: Propulsion Motor Coolant Fan 1.   See PGN 29952 for the corresponding command message.";
CM_ SG_ 2566650366 OperatingStatus "Indicates the operating status of the Propulsion Motor Coolant Fan 1 system or component.
This parameter is used to inform other devices that this system or component is no longer performing to its operational capacity and that reduced, or no flow, ...";
CM_ SG_ 2566650366 ServiceInd "Indicates that service is required for the Propulsion Motor Coolant Fan 1 system or component.
An active indication may convey a need for component replacement or periodic service.  The Propulsion Motor Coolant Fan 1 Controller Status Reason Code ...";
CM_ SG_ 2566650366 Pwr "Calculated electrical power consumed by the Propulsion Motor Coolant Fan 1.";
CM_ SG_ 2566650366 CtrlTemp "A temperature measured and reported by the device.  It may be used for direct or remote (by another controller) control of the Fan 1.  For example, this may be the temperature of the fluid flowing through the Fan 1, or some other temperature ...";
CM_ SG_ 2566650366 MotorSpd "Motor Speed of the Propulsion Motor Coolant Fan 1.";
CM_ SG_ 2566650366 CtrlCmdStatus "Indicates the source of the speed command to the Propulsion Motor Coolant Fan 1 system or component.
00b is communicated when the controller is self-controlled  (e.g. based on a temperature sensor).
01b is communicated when responding to the ...";
CM_ SG_ 2566650366 CtrlStatusReasonCode "Provides the reason code describing the unique failure of the Propulsion Motor Coolant Fan 1 system or component.
If a detailed reason code is not used by the supporting application, or this reason code is Not Available, the Propulsion Motor ...";
CM_ SG_ 2566650366 EnableStatus "Enable and direction status of the Propulsion Motor Coolant Fan 1 system or component.


00 - Accessory Motor Off
01 - Accessory Motor On - Normal, Forward, or Default Direction
10 - Accessory Motor On - Reverse Direction
11 - Not available";
CM_ BO_ 2566650110 "Electrified Accessory Propulsion Motor Coolant Fan 2 Status
The status of electrified Accessory: Propulsion Motor Coolant Fan 2.   See PGN 29696 for the corresponding command message.";
CM_ SG_ 2566650110 OperatingStatus "Indicates the operating status of the Propulsion Motor Coolant Fan 2 system or component.
This parameter is used to inform other devices that this system or component is no longer performing to its operational capacity and that reduced, or no flow, ...";
CM_ SG_ 2566650110 ServiceInd "Indicates that service is required for the Propulsion Motor Coolant Fan 2 system or component.
An active indication may convey a need for component replacement or periodic service.  The Propulsion Motor Coolant Fan 2 Controller Status Reason Code ...";
CM_ SG_ 2566650110 Pwr "Calculated electrical power consumed by the Propulsion Motor Coolant Fan 2.";
CM_ SG_ 2566650110 CtrlTemp "A temperature measured and reported by the device.  It may be used for direct or remote (by another controller) control of the Fan 2.  For example, this may be the temperature of the fluid flowing through the Fan 2, or some other temperature ...";
CM_ SG_ 2566650110 MotorSpd "Motor Speed of the Propulsion Motor Coolant Fan 2.";
CM_ SG_ 2566650110 CtrlCmdStatus "Indicates the source of the speed command to the Propulsion Motor Coolant Fan 2 system or component.
00b is communicated when the controller is self-controlled  (e.g. based on a temperature sensor).
01b is communicated when responding to the ...";
CM_ SG_ 2566650110 CtrlStatusReasonCode "Provides the reason code describing the unique failure of the Propulsion Motor Coolant Fan 2 system or component.
If a detailed reason code is not used by the supporting application, or this reason code is Not Available, the Propulsion Motor ...";
CM_ SG_ 2566650110 EnableStatus "Enable and direction status of the Propulsion Motor Coolant Fan 2 system or component.

00 - Accessory Motor Off
01 - Accessory Motor On - Normal, Forward, or Default Direction
10 - Accessory Motor On - Reverse Direction
11 - Not available";
CM_ BO_ 2566649854 "Electrified Accessory Propulsion Motor Coolant Fan 3 Status
The status of electrified Accessory: Propulsion Motor Coolant Fan 3.   See PGN 29440 for the corresponding command message.";
CM_ SG_ 2566649854 OperatingStatus "Indicates the operating status of the Propulsion Motor Coolant Fan 3 system or component.
This parameter is used to inform other devices that this system or component is no longer performing to its operational capacity and that reduced, or no flow, ...";
CM_ SG_ 2566649854 ServiceInd "Indicates that service is required for the Propulsion Motor Coolant Fan 3 system or component.
An active indication may convey a need for component replacement or periodic service.  The Propulsion Motor Coolant Fan 3 Controller Status Reason Code ...";
CM_ SG_ 2566649854 Pwr "Calculated electrical power consumed by the Propulsion Motor Coolant Fan 3.";
CM_ SG_ 2566649854 CtrlTemp "A temperature measured and reported by the device.  It may be used for direct or remote (by another controller) control of the Fan 3.  For example, this may be the temperature of the fluid flowing through the Fan 3, or some other temperature ...";
CM_ SG_ 2566649854 MotorSpd "Motor Speed of the Propulsion Motor Coolant Fan 3.";
CM_ SG_ 2566649854 CtrlCmdStatus "Indicates the source of the speed command to the Propulsion Motor Coolant Fan 3 system or component.
00b is communicated when the controller is self-controlled  (e.g. based on a temperature sensor).
01b is communicated when responding to the ...";
CM_ SG_ 2566649854 CtrlStatusReasonCode "Provides the reason code describing the unique failure of the Propulsion Motor Coolant Fan 3 system or component.
If a detailed reason code is not used by the supporting application, or this reason code is Not Available, the Propulsion Motor ...";
CM_ SG_ 2566649854 EnableStatus "Enable and direction status of the Propulsion Motor Coolant Fan 3 system or component.

00 - Accessory Motor Off
01 - Accessory Motor On - Normal, Forward, or Default Direction
10 - Accessory Motor On - Reverse Direction
11 - Not available";
CM_ BO_ 2566649598 "Vehicle Position 2
Contains additional data that is provided by GPS antennas and systems and which is used by many vehicle applications including geofencing, vehicle tracking, predictive cruise control, et cetera. This data, combined with the VP1 ...";
CM_ SG_ 2566649598 TimeDilutionOfPrecision "Provides the estimated receiver clock error as calculated by the positioning and locating system receiver from the satellites� clock data. The dilution of precision factor is calculated from the observed satellites (at least 4 must be tracked for ...";
CM_ SG_ 2566649598 DilutionOfPrecision "Provides the dilution of precision for the overall position (X-Y-Z coordinate system) as calculated by the positioning and locating system receiver. The dilution of precision factor is calculated from the observed satellites (at least 4 must be ...";
CM_ SG_ 2566649598 VerticalDilutionOfPrecision "Provides the dilution of precision in the vertical (Z axis) direction as calculated by the positioning and locating system receiver. The dilution of precision factor is calculated from the observed positions of the observed satellites (at least 4 ...";
CM_ SG_ 2566649598 HorizontalDilutionOfPrecision "Provides the dilution of precision in the horizontal (X-Y plane axis) direction as calculated by the positioning and locating system receiver. The dilution of precision factor is calculated from the observed positions of the observed satellites (at ...";
CM_ SG_ 2566649598 TotalNumOfSatellitesInView "Indicates the number of satellites in view of the positioning and locating system receiver.";
CM_ BO_ 2566649342 "Aftertreatment 1 Diesel Oxidation Catalyst 2
The purpose of this PGN is to group the aftertreatment diesel oxidation catalyst data for bank 1. These values include the intake temperature, outlet temperature and differential pressure as well as the ...";
CM_ SG_ 2566649342 DOCInToDPFOutDeltaPress "Aftertreatment 1 Diesel Oxidation Catalyst intake to Diesel Particulate Filter outlet differential pressure in exhaust bank 1.";
CM_ SG_ 2566649342 OutPress "Aftertreatment 1 Diesel Oxidation Catalyst absolute pressure measured at the DOC outlet in exhaust bank 1.";
CM_ SG_ 2566649342 InPress "Aftertreatment 1 Diesel Oxidation Catalyst absolute pressure measured at the DOC intake in exhaust bank 1.";
CM_ BO_ 2566649086 "Aftertreatment 2 Diesel Oxidation Catalyst 2
The purpose of this PGN is to group the aftertreatment diesel oxidation catalyst data for bank 2. These values include the intake temperature, outlet temperature and differential pressure as well as the ...";
CM_ SG_ 2566649086 DOCInToDPFOutDeltaPress "Aftertreatment 2 Diesel Oxidation Catalyst intake to Diesel Particulate Filter outlet differential pressure in exhaust bank 1.";
CM_ SG_ 2566649086 OutPress "Aftertreatment 2 Diesel Oxidation Catalyst absolute pressure measured at the DOC outlet in exhaust bank 1.";
CM_ SG_ 2566649086 InPress "Aftertreatment 2 Diesel Oxidation Catalyst absolute pressure measured at the DOC intake in exhaust bank 1.";
CM_ BO_ 2365322238 "Cruise Control / Vehicle Speed 5
Cruise Control / Vehicle Speed 5";
CM_ SG_ 2365322238 DirVS "The velocity and direction of the vehicle. Positive values are used for forward vehicle motion, negative values for reverse vehicle motion.  This SPN is intended for control purposes where vehicle direction is required.  It is not intended to ...";
CM_ BO_ 2566648318 "Oil Debris Monitoring System Status
Reports the status of an oil debris sensor within the Oil Debris Monitoring (ODM) system.
NOTE � Multiple instances of this message will be required to transmit data for all of the ODM Sensors. When reporting ...";
CM_ SG_ 2566648318 MonitorETempStatus "Temperature indicator for the Oil Debris Monitor (ODM) Electronics.

00 = Acceptable temperature
01 = Temperature is outside of limits
10 = Reserved
11 = Not available";
CM_ SG_ 2566648318 MonitorSPEStatus "Status of the Oil Debris Monitor (ODM) signal processing electronics.

00 = Electronics functioning normally
01 = Fault in electronics
10 = Reserved
11 = Not available";
CM_ SG_ 2566648318 MonitorSensingElementStatus "Status of the Oil Debris Monitor (ODM) sensing element.

00 = Sensing element OK
01 = Fault with sensing element
10 = Reserved
11 = Not available";
CM_ SG_ 2566648318 MonitorEnvironmentStatus "Status of the electrical and mechanical environment surrounding the Oil Debris Monitor (ODM) Sensor.

00 = Acceptable environment
01 = Excessive noise in signal
10 = Reserved
11 = Not available";
CM_ SG_ 2566648318 MonitorTotalNumOfSensors "Total number of Oil Debris Monitoring (ODM) sensors configured for this application.";
CM_ SG_ 2566648318 MonitorStatusIdNum "Identification number of the Oil Debris Monitoring (ODM) sensor being reported. Identification numbers are application specific.";
CM_ BO_ 2566648062 "Oil Debris Monitor Counts Non-Ferrous Bins 5 & 6
Reports the Oil Debris Monitor counts in non-ferrous bins 5 & 6 measured by one oil debris sensor within the Oil Debris Monitoring (ODM) system.
In oil debris monitoring, bins are count accumulators ...";
CM_ SG_ 2566648062 NFBin6Count "Total number of particles detected in Non-Ferrous bin 6. Bin sizes are application specific.";
CM_ SG_ 2566648062 NFBin5Count "Total number of particles detected in Non-Ferrous bin 5. Bin sizes are application specific.";
CM_ SG_ 2566648062 NFBins5And6IdNum "Identification number of the Oil Debris Monitoring (ODM) sensor being reported for Non-Ferrous bins 5 and 6. Identification numbers are application specific.";
CM_ BO_ 2566647806 "Oil Debris Monitor Counts Non-Ferrous Bins 3 & 4
Reports the Oil Debris Monitor counts in non-ferrous bins 3 & 4 measured by one oil debris sensor within the Oil Debris Monitoring (ODM) system.
In oil debris monitoring, bins are count accumulators ...";
CM_ SG_ 2566647806 NFBin4Count "Total number of particles detected in Non-Ferrous bin 4. Bin sizes are application specific.";
CM_ SG_ 2566647806 NFBin3Count "Total number of particles detected in Non-Ferrous bin 3. Bin sizes are application specific.";
CM_ SG_ 2566647806 NFBins3And4IdNum "Identification number of the Oil Debris Monitoring (ODM) sensor being reported for Non-Ferrous bins 3 and 4. Identification numbers are application specific.";
BA_DEF_ SG_  "SigType" ENUM  "Default","Range","RangeSigned","ASCII","Discrete","Control","ReferencePGN","DTC","StringDelimiter","StringLength","StringLengthControl","MessageCounter","MessageChecksum";
BA_DEF_ SG_  "GenSigStartValue" INT 0 2147483647;
BA_DEF_ SG_  "GenSigSendType" ENUM  "Cyclic","OnWrite","OnWriteWithRepetition","OnChange","OnChangeWithRepetition","IfActive","IfActiveWithRepetition","NoSigSendType";
BA_DEF_ SG_  "GenSigILSupport" ENUM  "No","Yes";
BA_DEF_ SG_  "GenSigEVName" STRING ;
BA_DEF_ SG_  "SPN" INT 0 524287;
BA_DEF_ BO_  "TpJ1939VarDlc" ENUM  "No","Yes";
BA_DEF_ BO_  "GenMsgStartDelayTime" INT 0 100000;
BA_DEF_ BO_  "GenMsgILSupport" ENUM  "No","Yes";
BA_DEF_ BO_  "GenMsgDelayTime" INT 0 1000;
BA_DEF_ BO_  "GenMsgRequestable" INT 0 1;
BA_DEF_ BO_  "GenMsgSendType" ENUM  "cyclic","NotUsed","NotUsed","NotUsed","NotUsed","NotUsed","NotUsed","IfActive","noMsgSendType";
BA_DEF_ BO_  "VFrameFormat" ENUM  "StandardCAN","ExtendedCAN","reserved","J1939PG";
BA_DEF_ BO_  "GenMsgCycleTime" INT 0 3600000;
BA_DEF_ SG_  "SystemSignalLongSymbol" STRING ;
BA_DEF_DEF_  "SigType" "Default";
BA_DEF_DEF_  "GenSigStartValue" 0;
BA_DEF_DEF_  "GenSigSendType" "NoSigSendType";
BA_DEF_DEF_  "GenSigILSupport" "Yes";
BA_DEF_DEF_  "GenSigEVName" "Env@Nodename_@Signame";
BA_DEF_DEF_  "SPN" 0;
BA_DEF_DEF_  "TpJ1939VarDlc" "No";
BA_DEF_DEF_  "GenMsgStartDelayTime" 0;
BA_DEF_DEF_  "GenMsgILSupport" "Yes";
BA_DEF_DEF_  "GenMsgDelayTime" 0;
BA_DEF_DEF_  "GenMsgRequestable" 1;
BA_DEF_DEF_  "GenMsgSendType" "noMsgSendType";
BA_DEF_DEF_  "VFrameFormat" "J1939PG";
BA_DEF_DEF_  "GenMsgCycleTime" 0;
BA_DEF_DEF_  "SystemSignalLongSymbol" "";
BA_ "GenMsgCycleTime" BO_ 2565942782 100;
BA_ "GenMsgSendType" BO_ 2565942782 0;
BA_ "GenMsgCycleTime" BO_ 2364615934 100;
BA_ "GenMsgSendType" BO_ 2364615934 0;
BA_ "GenMsgCycleTime" BO_ 2364615678 100;
BA_ "GenMsgSendType" BO_ 2364615678 0;
BA_ "GenMsgCycleTime" BO_ 2565942014 100;
BA_ "GenMsgSendType" BO_ 2565942014 0;
BA_ "GenMsgCycleTime" BO_ 2364615166 100;
BA_ "GenMsgSendType" BO_ 2364615166 0;
BA_ "GenMsgCycleTime" BO_ 2364614910 100;
BA_ "GenMsgSendType" BO_ 2364614910 0;
BA_ "GenMsgCycleTime" BO_ 2364614654 1000;
BA_ "GenMsgSendType" BO_ 2364614654 0;
BA_ "GenMsgDelayTime" BO_ 2364614654 10;
BA_ "GenMsgCycleTime" BO_ 2364614398 100;
BA_ "GenMsgSendType" BO_ 2364614398 0;
BA_ "GenMsgCycleTime" BO_ 2364614142 100;
BA_ "GenMsgSendType" BO_ 2364614142 0;
BA_ "GenMsgCycleTime" BO_ 2364613886 100;
BA_ "GenMsgSendType" BO_ 2364613886 0;
BA_ "GenMsgCycleTime" BO_ 2364613630 100;
BA_ "GenMsgSendType" BO_ 2364613630 0;
BA_ "GenMsgCycleTime" BO_ 2364613374 100;
BA_ "GenMsgSendType" BO_ 2364613374 0;
BA_ "GenMsgCycleTime" BO_ 2364613118 100;
BA_ "GenMsgSendType" BO_ 2364613118 0;
BA_ "GenMsgCycleTime" BO_ 2364612862 100;
BA_ "GenMsgSendType" BO_ 2364612862 0;
BA_ "GenMsgCycleTime" BO_ 2364612606 100;
BA_ "GenMsgSendType" BO_ 2364612606 0;
BA_ "GenMsgCycleTime" BO_ 2364612350 100;
BA_ "GenMsgSendType" BO_ 2364612350 0;
BA_ "GenMsgCycleTime" BO_ 2364612094 100;
BA_ "GenMsgSendType" BO_ 2364612094 0;
BA_ "GenMsgCycleTime" BO_ 2364611838 100;
BA_ "GenMsgSendType" BO_ 2364611838 0;
BA_ "GenMsgCycleTime" BO_ 2364611582 100;
BA_ "GenMsgSendType" BO_ 2364611582 0;
BA_ "GenMsgCycleTime" BO_ 2364611326 100;
BA_ "GenMsgSendType" BO_ 2364611326 0;
BA_ "GenMsgCycleTime" BO_ 2364611070 100;
BA_ "GenMsgSendType" BO_ 2364611070 0;
BA_ "GenMsgCycleTime" BO_ 2364610814 100;
BA_ "GenMsgSendType" BO_ 2364610814 0;
BA_ "GenMsgCycleTime" BO_ 2364610558 100;
BA_ "GenMsgSendType" BO_ 2364610558 0;
BA_ "GenMsgCycleTime" BO_ 2565918206 100;
BA_ "GenMsgSendType" BO_ 2565918206 0;
BA_ "GenMsgCycleTime" BO_ 2364591358 100;
BA_ "GenMsgSendType" BO_ 2364591358 0;
BA_ "GenMsgCycleTime" BO_ 2364591102 100;
BA_ "GenMsgSendType" BO_ 2364591102 0;
BA_ "GenMsgCycleTime" BO_ 2565917438 100;
BA_ "GenMsgSendType" BO_ 2565917438 0;
BA_ "GenMsgCycleTime" BO_ 2364590590 100;
BA_ "GenMsgSendType" BO_ 2364590590 0;
BA_ "GenMsgCycleTime" BO_ 2364590334 100;
BA_ "GenMsgSendType" BO_ 2364590334 0;
BA_ "GenMsgCycleTime" BO_ 2566661886 1000;
BA_ "GenMsgSendType" BO_ 2566661886 0;
BA_ "GenMsgCycleTime" BO_ 2566656254 1000;
BA_ "GenMsgSendType" BO_ 2566656254 0;
BA_ "GenMsgCycleTime" BO_ 2566655998 1000;
BA_ "GenMsgSendType" BO_ 2566655998 0;
BA_ "GenMsgDelayTime" BO_ 2566655998 100;
BA_ "GenMsgCycleTime" BO_ 2566655742 1000;
BA_ "GenMsgSendType" BO_ 2566655742 0;
BA_ "GenMsgDelayTime" BO_ 2566655742 100;
BA_ "GenMsgCycleTime" BO_ 2633764094 1000;
BA_ "GenMsgSendType" BO_ 2633764094 0;
BA_ "GenMsgCycleTime" BO_ 2566654974 250;
BA_ "GenMsgSendType" BO_ 2566654974 0;
BA_ "GenMsgCycleTime" BO_ 2566654718 100;
BA_ "GenMsgSendType" BO_ 2566654718 0;
BA_ "GenMsgDelayTime" BO_ 2566654718 10;
BA_ "GenMsgCycleTime" BO_ 2566654462 1000;
BA_ "GenMsgSendType" BO_ 2566654462 0;
BA_ "GenMsgCycleTime" BO_ 2566654206 100;
BA_ "GenMsgSendType" BO_ 2566654206 0;
BA_ "GenMsgDelayTime" BO_ 2566654206 10;
BA_ "GenMsgCycleTime" BO_ 2566653950 1000;
BA_ "GenMsgSendType" BO_ 2566653950 0;
BA_ "GenMsgCycleTime" BO_ 2566653694 100;
BA_ "GenMsgSendType" BO_ 2566653694 0;
BA_ "GenMsgDelayTime" BO_ 2566653694 10;
BA_ "GenMsgCycleTime" BO_ 2566653438 1000;
BA_ "GenMsgSendType" BO_ 2566653438 0;
BA_ "GenMsgCycleTime" BO_ 2566653182 100;
BA_ "GenMsgSendType" BO_ 2566653182 0;
BA_ "GenMsgDelayTime" BO_ 2566653182 10;
BA_ "GenMsgCycleTime" BO_ 2566652926 1000;
BA_ "GenMsgSendType" BO_ 2566652926 0;
BA_ "GenMsgCycleTime" BO_ 2566652670 10000;
BA_ "GenMsgSendType" BO_ 2566652670 0;
BA_ "GenMsgDelayTime" BO_ 2566652670 1000;
BA_ "GenMsgCycleTime" BO_ 2566652414 1000;
BA_ "GenMsgSendType" BO_ 2566652414 0;
BA_ "GenMsgCycleTime" BO_ 2566651902 1000;
BA_ "GenMsgSendType" BO_ 2566651902 0;
BA_ "GenMsgCycleTime" BO_ 2566651646 1000;
BA_ "GenMsgSendType" BO_ 2566651646 0;
BA_ "GenMsgCycleTime" BO_ 2566651390 1000;
BA_ "GenMsgSendType" BO_ 2566651390 0;
BA_ "GenMsgCycleTime" BO_ 2566651134 1000;
BA_ "GenMsgSendType" BO_ 2566651134 0;
BA_ "GenMsgCycleTime" BO_ 2566650878 1000;
BA_ "GenMsgSendType" BO_ 2566650878 0;
BA_ "GenMsgCycleTime" BO_ 2566650622 1000;
BA_ "GenMsgSendType" BO_ 2566650622 0;
BA_ "GenMsgCycleTime" BO_ 2566650366 1000;
BA_ "GenMsgSendType" BO_ 2566650366 0;
BA_ "GenMsgCycleTime" BO_ 2566650110 1000;
BA_ "GenMsgSendType" BO_ 2566650110 0;
BA_ "GenMsgCycleTime" BO_ 2566649854 1000;
BA_ "GenMsgSendType" BO_ 2566649854 0;
BA_ "GenMsgCycleTime" BO_ 2566649598 5000;
BA_ "GenMsgSendType" BO_ 2566649598 0;
BA_ "GenMsgCycleTime" BO_ 2566649342 500;
BA_ "GenMsgSendType" BO_ 2566649342 0;
BA_ "GenMsgCycleTime" BO_ 2566649086 500;
BA_ "GenMsgSendType" BO_ 2566649086 0;
BA_ "GenMsgCycleTime" BO_ 2365322238 100;
BA_ "GenMsgSendType" BO_ 2365322238 0;
BA_ "GenMsgCycleTime" BO_ 2566648318 30000;
BA_ "GenMsgSendType" BO_ 2566648318 0;
BA_ "GenMsgCycleTime" BO_ 2566648062 10000;
BA_ "GenMsgSendType" BO_ 2566648062 0;
BA_ "GenMsgCycleTime" BO_ 2566647806 10000;
BA_ "GenMsgSendType" BO_ 2566647806 0;
BA_ "SPN" SG_ 2565942782 PLedDueToUndefinedReason 9310;
BA_ "SigType" SG_ 2565942782 PLedDueToUndefinedReason 5;
BA_ "SPN" SG_ 2565942782 PLedDueToRateOfChangeLmt 9309;
BA_ "SigType" SG_ 2565942782 PLedDueToRateOfChangeLmt 5;
BA_ "SPN" SG_ 2565942782 PLedDueToPwrETemp 9308;
BA_ "SigType" SG_ 2565942782 PLedDueToPwrETemp 5;
BA_ "SPN" SG_ 2565942782 PLedDueToEFilterTemp 9307;
BA_ "SigType" SG_ 2565942782 PLedDueToEFilterTemp 5;
BA_ "SPN" SG_ 2565942782 PLedDueToCtrlTemp 9306;
BA_ "SigType" SG_ 2565942782 PLedDueToCtrlTemp 5;
BA_ "SPN" SG_ 2565942782 FreqCmdExceedsMax 9305;
BA_ "SigType" SG_ 2565942782 FreqCmdExceedsMax 5;
BA_ "SPN" SG_ 2565942782 FreqCmdBelowMin 9304;
BA_ "SigType" SG_ 2565942782 FreqCmdBelowMin 5;
BA_ "SPN" SG_ 2565942782 PLedDueToDCSideVMin 9303;
BA_ "SigType" SG_ 2565942782 PLedDueToDCSideVMin 5;
BA_ "SPN" SG_ 2565942782 PLedDueToACSideRMSCur 9302;
BA_ "SigType" SG_ 2565942782 PLedDueToACSideRMSCur 5;
BA_ "SPN" SG_ 2565942782 PLedDueToDCSideCur 9301;
BA_ "SigType" SG_ 2565942782 PLedDueToDCSideCur 5;
BA_ "SPN" SG_ 2364615934 SLIV 9300;
BA_ "SigType" SG_ 2364615934 SLIV 1;
BA_ "SPN" SG_ 2364615934 IgntV 9299;
BA_ "SigType" SG_ 2364615934 IgntV 1;
BA_ "SPN" SG_ 2364615678 DCSideNegToChassisGroundV 9585;
BA_ "SigType" SG_ 2364615678 DCSideNegToChassisGroundV 1;
BA_ "SPN" SG_ 2364615678 DCSideCur 9298;
BA_ "SigType" SG_ 2364615678 DCSideCur 1;
BA_ "SPN" SG_ 2364615678 DCSideV 9297;
BA_ "SigType" SG_ 2364615678 DCSideV 1;
BA_ "SPN" SG_ 2364615678 DCSidePwr 9296;
BA_ "SigType" SG_ 2364615678 DCSidePwr 1;
BA_ "SPN" SG_ 2565942014 PLedDueToUndefinedReason 9280;
BA_ "SigType" SG_ 2565942014 PLedDueToUndefinedReason 5;
BA_ "SPN" SG_ 2565942014 PLedDueToRateOfChangeLmt 9279;
BA_ "SigType" SG_ 2565942014 PLedDueToRateOfChangeLmt 5;
BA_ "SPN" SG_ 2565942014 PLedDueToPwrETemp 9278;
BA_ "SigType" SG_ 2565942014 PLedDueToPwrETemp 5;
BA_ "SPN" SG_ 2565942014 PLedDueToEFilterTemp 9277;
BA_ "SigType" SG_ 2565942014 PLedDueToEFilterTemp 5;
BA_ "SPN" SG_ 2565942014 PLedDueToCtrlTemp 9276;
BA_ "SigType" SG_ 2565942014 PLedDueToCtrlTemp 5;
BA_ "SPN" SG_ 2565942014 FreqCmdExceedsMax 9275;
BA_ "SigType" SG_ 2565942014 FreqCmdExceedsMax 5;
BA_ "SPN" SG_ 2565942014 FreqCmdBelowMin 9274;
BA_ "SigType" SG_ 2565942014 FreqCmdBelowMin 5;
BA_ "SPN" SG_ 2565942014 PLedDueToDCSideVMin 9273;
BA_ "SigType" SG_ 2565942014 PLedDueToDCSideVMin 5;
BA_ "SPN" SG_ 2565942014 PLedDueToACSideRMSCur 9272;
BA_ "SigType" SG_ 2565942014 PLedDueToACSideRMSCur 5;
BA_ "SPN" SG_ 2565942014 PLedDueToDCSideCur 9271;
BA_ "SigType" SG_ 2565942014 PLedDueToDCSideCur 5;
BA_ "SPN" SG_ 2364615166 SLIV 9270;
BA_ "SigType" SG_ 2364615166 SLIV 1;
BA_ "SPN" SG_ 2364615166 IgntV 9269;
BA_ "SigType" SG_ 2364615166 IgntV 1;
BA_ "SPN" SG_ 2364614910 DCSideNegToChassisGroundV 9584;
BA_ "SigType" SG_ 2364614910 DCSideNegToChassisGroundV 1;
BA_ "SPN" SG_ 2364614910 DCSideCur 9268;
BA_ "SigType" SG_ 2364614910 DCSideCur 1;
BA_ "SPN" SG_ 2364614910 DCSideV 9267;
BA_ "SigType" SG_ 2364614910 DCSideV 1;
BA_ "SPN" SG_ 2364614910 DCSidePwr 9266;
BA_ "SigType" SG_ 2364614910 DCSidePwr 1;
BA_ "SPN" SG_ 2364614654 GradeThresholdInd6 9186;
BA_ "SigType" SG_ 2364614654 GradeThresholdInd6 4;
BA_ "SPN" SG_ 2364614654 GradeThresholdInd5 9185;
BA_ "SigType" SG_ 2364614654 GradeThresholdInd5 4;
BA_ "SPN" SG_ 2364614654 GradeThresholdInd4 9184;
BA_ "SigType" SG_ 2364614654 GradeThresholdInd4 4;
BA_ "SPN" SG_ 2364614654 GradeThresholdInd3 9183;
BA_ "SigType" SG_ 2364614654 GradeThresholdInd3 4;
BA_ "SPN" SG_ 2364614654 GradeThresholdInd2 9182;
BA_ "SigType" SG_ 2364614654 GradeThresholdInd2 4;
BA_ "SPN" SG_ 2364614654 GradeThresholdInd1 9181;
BA_ "SigType" SG_ 2364614654 GradeThresholdInd1 4;
BA_ "SPN" SG_ 2364614398 FourHiSideNegToChassisGroundV 9590;
BA_ "SigType" SG_ 2364614398 FourHiSideNegToChassisGroundV 1;
BA_ "SPN" SG_ 2364614398 FourHiSidePwr 9029;
BA_ "SigType" SG_ 2364614398 FourHiSidePwr 1;
BA_ "SPN" SG_ 2364614398 FourLowSidePwr 9028;
BA_ "SigType" SG_ 2364614398 FourLowSidePwr 1;
BA_ "SPN" SG_ 2364614142 SLIBatTermTemp 9027;
BA_ "SigType" SG_ 2364614142 SLIBatTermTemp 1;
BA_ "SPN" SG_ 2364614142 SLIBatTermCur 9026;
BA_ "SigType" SG_ 2364614142 SLIBatTermCur 1;
BA_ "SPN" SG_ 2364614142 SLIBatTermV 9025;
BA_ "SigType" SG_ 2364614142 SLIBatTermV 1;
BA_ "SPN" SG_ 2364613886 FourHiSideCur 9024;
BA_ "SigType" SG_ 2364613886 FourHiSideCur 1;
BA_ "SPN" SG_ 2364613886 FourHiSideV 9023;
BA_ "SigType" SG_ 2364613886 FourHiSideV 1;
BA_ "SPN" SG_ 2364613886 FourLowSideCur 9022;
BA_ "SigType" SG_ 2364613886 FourLowSideCur 1;
BA_ "SPN" SG_ 2364613886 FourLowSideV 9021;
BA_ "SigType" SG_ 2364613886 FourLowSideV 1;
BA_ "SPN" SG_ 2364613630 FourPLDueToUndefinedReason 9020;
BA_ "SigType" SG_ 2364613630 FourPLDueToUndefinedReason 4;
BA_ "SPN" SG_ 2364613630 FourPLDueToSLIBatTermTemp 9019;
BA_ "SigType" SG_ 2364613630 FourPLDueToSLIBatTermTemp 4;
BA_ "SPN" SG_ 2364613630 FourPLDueToSLIBatTermCur 9018;
BA_ "SigType" SG_ 2364613630 FourPLDueToSLIBatTermCur 4;
BA_ "SPN" SG_ 2364613630 FourPLDueToSLIBatTermV 9017;
BA_ "SigType" SG_ 2364613630 FourPLDueToSLIBatTermV 4;
BA_ "SPN" SG_ 2364613630 FourPLDueToPwrETemp 9016;
BA_ "SigType" SG_ 2364613630 FourPLDueToPwrETemp 4;
BA_ "SPN" SG_ 2364613630 FourPLDueToEFilterTemp 9015;
BA_ "SigType" SG_ 2364613630 FourPLDueToEFilterTemp 4;
BA_ "SPN" SG_ 2364613630 FourPLDueToConvTemp 9014;
BA_ "SigType" SG_ 2364613630 FourPLDueToConvTemp 4;
BA_ "SPN" SG_ 2364613630 FourPLDueToLowSideVMax 9013;
BA_ "SigType" SG_ 2364613630 FourPLDueToLowSideVMax 4;
BA_ "SPN" SG_ 2364613630 FourPLDueToLowSideVMin 9012;
BA_ "SigType" SG_ 2364613630 FourPLDueToLowSideVMin 4;
BA_ "SPN" SG_ 2364613630 FourPLDueToHiSideVMax 9011;
BA_ "SigType" SG_ 2364613630 FourPLDueToHiSideVMax 4;
BA_ "SPN" SG_ 2364613630 FourPLDueToHiSideVMin 9010;
BA_ "SigType" SG_ 2364613630 FourPLDueToHiSideVMin 4;
BA_ "SPN" SG_ 2364613630 FourPLDueToLowSideCur 9009;
BA_ "SigType" SG_ 2364613630 FourPLDueToLowSideCur 4;
BA_ "SPN" SG_ 2364613630 FourPLDueToHiSideCur 9008;
BA_ "SigType" SG_ 2364613630 FourPLDueToHiSideCur 4;
BA_ "SPN" SG_ 2364613630 FourLoadshedReq 9007;
BA_ "SigType" SG_ 2364613630 FourLoadshedReq 5;
BA_ "SPN" SG_ 2364613630 FourHVILStatus 9006;
BA_ "SigType" SG_ 2364613630 FourHVILStatus 4;
BA_ "SPN" SG_ 2364613630 FourOperationalStatus 9005;
BA_ "SPN" SG_ 2364613374 FourLowSideVBuckDefaultSetpoint 9518;
BA_ "SigType" SG_ 2364613374 FourLowSideVBuckDefaultSetpoint 1;
BA_ "SPN" SG_ 2364613374 FourHiSideVBoostSetpoint 9004;
BA_ "SigType" SG_ 2364613374 FourHiSideVBoostSetpoint 1;
BA_ "SPN" SG_ 2364613374 FourLowSideVBuckSetpoint 9003;
BA_ "SigType" SG_ 2364613374 FourLowSideVBuckSetpoint 1;
BA_ "SPN" SG_ 2364613374 FourOperationalCmd 9002;
BA_ "SPN" SG_ 2364613118 ThreeHiSideNegToChassisGroundV 9589;
BA_ "SigType" SG_ 2364613118 ThreeHiSideNegToChassisGroundV 1;
BA_ "SPN" SG_ 2364613118 ThreeHiSidePwr 8974;
BA_ "SigType" SG_ 2364613118 ThreeHiSidePwr 1;
BA_ "SPN" SG_ 2364613118 ThreeLowSidePwr 8973;
BA_ "SigType" SG_ 2364613118 ThreeLowSidePwr 1;
BA_ "SPN" SG_ 2364612862 SLIBatTermTemp 8972;
BA_ "SigType" SG_ 2364612862 SLIBatTermTemp 1;
BA_ "SPN" SG_ 2364612862 SLIBatTermCur 8971;
BA_ "SigType" SG_ 2364612862 SLIBatTermCur 1;
BA_ "SPN" SG_ 2364612862 SLIBatTermV 8970;
BA_ "SigType" SG_ 2364612862 SLIBatTermV 1;
BA_ "SPN" SG_ 2364612606 ThreeHiSideCur 8969;
BA_ "SigType" SG_ 2364612606 ThreeHiSideCur 1;
BA_ "SPN" SG_ 2364612606 ThreeHiSideV 8968;
BA_ "SigType" SG_ 2364612606 ThreeHiSideV 1;
BA_ "SPN" SG_ 2364612606 ThreeLowSideCur 8967;
BA_ "SigType" SG_ 2364612606 ThreeLowSideCur 1;
BA_ "SPN" SG_ 2364612606 ThreeLowSideV 8966;
BA_ "SigType" SG_ 2364612606 ThreeLowSideV 1;
BA_ "SPN" SG_ 2364612350 ThreePLDueToUndefinedReason 8965;
BA_ "SigType" SG_ 2364612350 ThreePLDueToUndefinedReason 4;
BA_ "SPN" SG_ 2364612350 ThreePLDueToSLIBatTermTemp 8964;
BA_ "SigType" SG_ 2364612350 ThreePLDueToSLIBatTermTemp 4;
BA_ "SPN" SG_ 2364612350 ThreePLDueToSLIBatTermCur 8963;
BA_ "SigType" SG_ 2364612350 ThreePLDueToSLIBatTermCur 4;
BA_ "SPN" SG_ 2364612350 ThreePLDueToSLIBatTermV 8962;
BA_ "SigType" SG_ 2364612350 ThreePLDueToSLIBatTermV 4;
BA_ "SPN" SG_ 2364612350 ThreePLDueToPwrETemp 8961;
BA_ "SigType" SG_ 2364612350 ThreePLDueToPwrETemp 4;
BA_ "SPN" SG_ 2364612350 ThreePLDueToEFilterTemp 8960;
BA_ "SigType" SG_ 2364612350 ThreePLDueToEFilterTemp 4;
BA_ "SPN" SG_ 2364612350 ThreePLDueToConvTemp 8959;
BA_ "SigType" SG_ 2364612350 ThreePLDueToConvTemp 4;
BA_ "SPN" SG_ 2364612350 ThreePLDueToLowSideVMax 8958;
BA_ "SigType" SG_ 2364612350 ThreePLDueToLowSideVMax 4;
BA_ "SPN" SG_ 2364612350 ThreePLDueToLowSideVMin 8957;
BA_ "SigType" SG_ 2364612350 ThreePLDueToLowSideVMin 4;
BA_ "SPN" SG_ 2364612350 ThreePLDueToHiSideVMax 8956;
BA_ "SigType" SG_ 2364612350 ThreePLDueToHiSideVMax 4;
BA_ "SPN" SG_ 2364612350 ThreePLDueToHiSideVMin 8955;
BA_ "SigType" SG_ 2364612350 ThreePLDueToHiSideVMin 4;
BA_ "SPN" SG_ 2364612350 ThreePLDueToLowSideCur 8954;
BA_ "SigType" SG_ 2364612350 ThreePLDueToLowSideCur 4;
BA_ "SPN" SG_ 2364612350 ThreePLDueToHiSideCur 8953;
BA_ "SigType" SG_ 2364612350 ThreePLDueToHiSideCur 4;
BA_ "SPN" SG_ 2364612350 ThreeLoadshedReq 8952;
BA_ "SigType" SG_ 2364612350 ThreeLoadshedReq 5;
BA_ "SPN" SG_ 2364612350 ThreeHVILStatus 8951;
BA_ "SigType" SG_ 2364612350 ThreeHVILStatus 4;
BA_ "SPN" SG_ 2364612350 ThreeOperationalStatus 8950;
BA_ "SPN" SG_ 2364612094 ThreeLowSideVBuckDefaultSetpoint 9517;
BA_ "SigType" SG_ 2364612094 ThreeLowSideVBuckDefaultSetpoint 1;
BA_ "SPN" SG_ 2364612094 ThreeHiSideVBoostSetpoint 8949;
BA_ "SigType" SG_ 2364612094 ThreeHiSideVBoostSetpoint 1;
BA_ "SPN" SG_ 2364612094 ThreeLowSideVBuckSetpoint 8948;
BA_ "SigType" SG_ 2364612094 ThreeLowSideVBuckSetpoint 1;
BA_ "SPN" SG_ 2364612094 ThreeOperationalCmd 8947;
BA_ "SPN" SG_ 2364611838 TwoHiSideNegToChassisGroundV 9588;
BA_ "SigType" SG_ 2364611838 TwoHiSideNegToChassisGroundV 1;
BA_ "SPN" SG_ 2364611838 TwoHiSidePwr 8919;
BA_ "SigType" SG_ 2364611838 TwoHiSidePwr 1;
BA_ "SPN" SG_ 2364611838 TwoLowSidePwr 8918;
BA_ "SigType" SG_ 2364611838 TwoLowSidePwr 1;
BA_ "SPN" SG_ 2364611582 SLIBatTermTemp 8917;
BA_ "SigType" SG_ 2364611582 SLIBatTermTemp 1;
BA_ "SPN" SG_ 2364611582 SLIBatTermCur 8916;
BA_ "SigType" SG_ 2364611582 SLIBatTermCur 1;
BA_ "SPN" SG_ 2364611582 SLIBatTermV 8915;
BA_ "SigType" SG_ 2364611582 SLIBatTermV 1;
BA_ "SPN" SG_ 2364611326 TwoHiSideCur 8914;
BA_ "SigType" SG_ 2364611326 TwoHiSideCur 1;
BA_ "SPN" SG_ 2364611326 TwoHiSideV 8913;
BA_ "SigType" SG_ 2364611326 TwoHiSideV 1;
BA_ "SPN" SG_ 2364611326 TwoLowSideCur 8912;
BA_ "SigType" SG_ 2364611326 TwoLowSideCur 1;
BA_ "SPN" SG_ 2364611326 TwoLowSideV 8911;
BA_ "SigType" SG_ 2364611326 TwoLowSideV 1;
BA_ "SPN" SG_ 2364611070 TwoPLDueToUndefinedReason 8910;
BA_ "SigType" SG_ 2364611070 TwoPLDueToUndefinedReason 4;
BA_ "SPN" SG_ 2364611070 TwoPLDueToSLIBatTermTemp 8909;
BA_ "SigType" SG_ 2364611070 TwoPLDueToSLIBatTermTemp 4;
BA_ "SPN" SG_ 2364611070 TwoPLDueToSLIBatTermCur 8908;
BA_ "SigType" SG_ 2364611070 TwoPLDueToSLIBatTermCur 4;
BA_ "SPN" SG_ 2364611070 TwoPLDueToSLIBatTermV 8907;
BA_ "SigType" SG_ 2364611070 TwoPLDueToSLIBatTermV 4;
BA_ "SPN" SG_ 2364611070 TwoPLDueToPwrETemp 8906;
BA_ "SigType" SG_ 2364611070 TwoPLDueToPwrETemp 4;
BA_ "SPN" SG_ 2364611070 TwoPLDueToEFilterTemp 8905;
BA_ "SigType" SG_ 2364611070 TwoPLDueToEFilterTemp 4;
BA_ "SPN" SG_ 2364611070 TwoPLDueToConvTemp 8904;
BA_ "SigType" SG_ 2364611070 TwoPLDueToConvTemp 4;
BA_ "SPN" SG_ 2364611070 TwoPLDueToLowSideVMax 8903;
BA_ "SigType" SG_ 2364611070 TwoPLDueToLowSideVMax 4;
BA_ "SPN" SG_ 2364611070 TwoPLDueToLowSideVMin 8902;
BA_ "SigType" SG_ 2364611070 TwoPLDueToLowSideVMin 4;
BA_ "SPN" SG_ 2364611070 TwoPLDueToHiSideVMax 8901;
BA_ "SigType" SG_ 2364611070 TwoPLDueToHiSideVMax 4;
BA_ "SPN" SG_ 2364611070 TwoPLDueToHiSideVMin 8900;
BA_ "SigType" SG_ 2364611070 TwoPLDueToHiSideVMin 4;
BA_ "SPN" SG_ 2364611070 TwoPLDueToLowSideCur 8899;
BA_ "SigType" SG_ 2364611070 TwoPLDueToLowSideCur 4;
BA_ "SPN" SG_ 2364611070 TwoPLDueToHiSideCur 8898;
BA_ "SigType" SG_ 2364611070 TwoPLDueToHiSideCur 4;
BA_ "SPN" SG_ 2364611070 TwoLoadshedReq 8897;
BA_ "SigType" SG_ 2364611070 TwoLoadshedReq 5;
BA_ "SPN" SG_ 2364611070 TwoHVILStatus 8896;
BA_ "SigType" SG_ 2364611070 TwoHVILStatus 4;
BA_ "SPN" SG_ 2364611070 TwoOperationalStatus 8895;
BA_ "SPN" SG_ 2364610814 TwoLowSideVBuckDefaultSetpoint 9516;
BA_ "SigType" SG_ 2364610814 TwoLowSideVBuckDefaultSetpoint 1;
BA_ "SPN" SG_ 2364610814 TwoHiSideVBoostSetpoint 8894;
BA_ "SigType" SG_ 2364610814 TwoHiSideVBoostSetpoint 1;
BA_ "SPN" SG_ 2364610814 TwoLowSideVBuckSetpoint 8893;
BA_ "SigType" SG_ 2364610814 TwoLowSideVBuckSetpoint 1;
BA_ "SPN" SG_ 2364610814 TwoOperationalCmd 8892;
BA_ "SPN" SG_ 2364610558 OneHiSideNegToChassisGroundV 9587;
BA_ "SigType" SG_ 2364610558 OneHiSideNegToChassisGroundV 1;
BA_ "SPN" SG_ 2364610558 OneHiSidePwr 8821;
BA_ "SigType" SG_ 2364610558 OneHiSidePwr 1;
BA_ "SPN" SG_ 2364610558 OneLowSidePwr 8820;
BA_ "SigType" SG_ 2364610558 OneLowSidePwr 1;
BA_ "SPN" SG_ 2565918206 PLedDueToUndefinedReason 9250;
BA_ "SigType" SG_ 2565918206 PLedDueToUndefinedReason 5;
BA_ "SPN" SG_ 2565918206 PLedDueToRateOfChangeLmt 9249;
BA_ "SigType" SG_ 2565918206 PLedDueToRateOfChangeLmt 5;
BA_ "SPN" SG_ 2565918206 PLedDueToPwrETemp 9248;
BA_ "SigType" SG_ 2565918206 PLedDueToPwrETemp 5;
BA_ "SPN" SG_ 2565918206 PLedDueToEFilterTemp 9247;
BA_ "SigType" SG_ 2565918206 PLedDueToEFilterTemp 5;
BA_ "SPN" SG_ 2565918206 PLedDueToCtrlTemp 9246;
BA_ "SigType" SG_ 2565918206 PLedDueToCtrlTemp 5;
BA_ "SPN" SG_ 2565918206 FreqCmdExceedsMax 9245;
BA_ "SigType" SG_ 2565918206 FreqCmdExceedsMax 5;
BA_ "SPN" SG_ 2565918206 FreqCmdBelowMin 9244;
BA_ "SigType" SG_ 2565918206 FreqCmdBelowMin 5;
BA_ "SPN" SG_ 2565918206 PLedDueToDCSideVMin 9243;
BA_ "SigType" SG_ 2565918206 PLedDueToDCSideVMin 5;
BA_ "SPN" SG_ 2565918206 PLedDueToACSideRMSCur 9242;
BA_ "SigType" SG_ 2565918206 PLedDueToACSideRMSCur 5;
BA_ "SPN" SG_ 2565918206 PLedDueToDCSideCur 9241;
BA_ "SigType" SG_ 2565918206 PLedDueToDCSideCur 5;
BA_ "SPN" SG_ 2364591358 SLIV 9240;
BA_ "SigType" SG_ 2364591358 SLIV 1;
BA_ "SPN" SG_ 2364591358 IgntV 9239;
BA_ "SigType" SG_ 2364591358 IgntV 1;
BA_ "SPN" SG_ 2364591102 DCSideNegToChassisGroundV 9583;
BA_ "SigType" SG_ 2364591102 DCSideNegToChassisGroundV 1;
BA_ "SPN" SG_ 2364591102 DCSideCur 9238;
BA_ "SigType" SG_ 2364591102 DCSideCur 1;
BA_ "SPN" SG_ 2364591102 DCSideV 9237;
BA_ "SigType" SG_ 2364591102 DCSideV 1;
BA_ "SPN" SG_ 2364591102 DCSidePwr 9236;
BA_ "SigType" SG_ 2364591102 DCSidePwr 1;
BA_ "SPN" SG_ 2565917438 PLedDueToUndefinedReason 9220;
BA_ "SigType" SG_ 2565917438 PLedDueToUndefinedReason 5;
BA_ "SPN" SG_ 2565917438 PLedDueToRateOfChangeLmt 9219;
BA_ "SigType" SG_ 2565917438 PLedDueToRateOfChangeLmt 5;
BA_ "SPN" SG_ 2565917438 PLedDueToPwrETemp 9218;
BA_ "SigType" SG_ 2565917438 PLedDueToPwrETemp 5;
BA_ "SPN" SG_ 2565917438 PLedDueToEFilterTemp 9217;
BA_ "SigType" SG_ 2565917438 PLedDueToEFilterTemp 5;
BA_ "SPN" SG_ 2565917438 PLedDueToCtrlTemp 9216;
BA_ "SigType" SG_ 2565917438 PLedDueToCtrlTemp 5;
BA_ "SPN" SG_ 2565917438 FreqCmdExceedsMax 9215;
BA_ "SigType" SG_ 2565917438 FreqCmdExceedsMax 5;
BA_ "SPN" SG_ 2565917438 FreqCmdBelowMin 9214;
BA_ "SigType" SG_ 2565917438 FreqCmdBelowMin 5;
BA_ "SPN" SG_ 2565917438 PLedDueToDCSideVMin 9213;
BA_ "SigType" SG_ 2565917438 PLedDueToDCSideVMin 5;
BA_ "SPN" SG_ 2565917438 PLedDueToACSideRMSCur 9212;
BA_ "SigType" SG_ 2565917438 PLedDueToACSideRMSCur 5;
BA_ "SPN" SG_ 2565917438 PLedDueToDCSideCur 9211;
BA_ "SigType" SG_ 2565917438 PLedDueToDCSideCur 5;
BA_ "SPN" SG_ 2364590590 SLIV 9210;
BA_ "SigType" SG_ 2364590590 SLIV 1;
BA_ "SPN" SG_ 2364590590 IgntV 9209;
BA_ "SigType" SG_ 2364590590 IgntV 1;
BA_ "SPN" SG_ 2364590334 DCSideNegToChassisGroundV 9582;
BA_ "SigType" SG_ 2364590334 DCSideNegToChassisGroundV 1;
BA_ "SPN" SG_ 2364590334 DCSideCur 8891;
BA_ "SigType" SG_ 2364590334 DCSideCur 1;
BA_ "SPN" SG_ 2364590334 DCSideV 8890;
BA_ "SigType" SG_ 2364590334 DCSideV 1;
BA_ "SPN" SG_ 2364590334 DCSidePwr 8889;
BA_ "SigType" SG_ 2364590334 DCSidePwr 1;
BA_ "SPN" SG_ 2624519934 CommandedReceiveSPNSA 8841;
BA_ "SPN" SG_ 2624519934 CommandedReceiveSPNReqSt 8840;
BA_ "SigType" SG_ 2624519934 CommandedReceiveSPNReqSt 5;
BA_ "SPN" SG_ 2624519934 CommandedReceiveSPN 8839;
BA_ "SPN" SG_ 2624519934 TransactionMode 8838;
BA_ "SPN" SG_ 2624519934 CommandedPort 8837;
BA_ "SPN" SG_ 2557345534 PlungerFiringOrder 8870;
BA_ "SPN" SG_ 2557345534 RodLoadHiThreshold 8869;
BA_ "SigType" SG_ 2557345534 RodLoadHiThreshold 1;
BA_ "SPN" SG_ 2557345534 CrankshaftSpdHiThreshold 8868;
BA_ "SigType" SG_ 2557345534 CrankshaftSpdHiThreshold 1;
BA_ "SPN" SG_ 2557345534 CrankshaftSpdLowThreshold 8867;
BA_ "SigType" SG_ 2557345534 CrankshaftSpdLowThreshold 1;
BA_ "SPN" SG_ 2557345534 DisPressHiThreshold 8866;
BA_ "SigType" SG_ 2557345534 DisPressHiThreshold 1;
BA_ "SPN" SG_ 2557345534 SuctionPressHiThreshold 8865;
BA_ "SigType" SG_ 2557345534 SuctionPressHiThreshold 1;
BA_ "SPN" SG_ 2557345534 SuctionPressLowThreshold 8864;
BA_ "SigType" SG_ 2557345534 SuctionPressLowThreshold 1;
BA_ "SPN" SG_ 2557345534 GearBoxOilTempHiThreshold 8863;
BA_ "SigType" SG_ 2557345534 GearBoxOilTempHiThreshold 1;
BA_ "SPN" SG_ 2557345534 GearBoxOilTempLowThreshold 8862;
BA_ "SigType" SG_ 2557345534 GearBoxOilTempLowThreshold 1;
BA_ "SPN" SG_ 2557345534 GearBoxOilPressHiThreshold 8861;
BA_ "SigType" SG_ 2557345534 GearBoxOilPressHiThreshold 1;
BA_ "SPN" SG_ 2557345534 GearBoxOilPressLowThreshold 8860;
BA_ "SigType" SG_ 2557345534 GearBoxOilPressLowThreshold 1;
BA_ "SPN" SG_ 2557214462 DisPressCalSetPointCmd 9198;
BA_ "SPN" SG_ 2557214462 SuctionPressCalSetPointCmd 9197;
BA_ "SPN" SG_ 2557148926 VesselSpdCtrlMode 9660;
BA_ "SPN" SG_ 2557148926 VesselEngSetSpd 9659;
BA_ "SigType" SG_ 2557148926 VesselEngSetSpd 1;
BA_ "SPN" SG_ 2557148926 TrollingModeCurSetting 9658;
BA_ "SPN" SG_ 2557148926 TrollingMode 9657;
BA_ "SPN" SG_ 2557148926 EngThrotSynchModeCurSetting 9656;
BA_ "SPN" SG_ 2557148926 OpStationLockout 9655;
BA_ "SigType" SG_ 2557148926 OpStationLockout 5;
BA_ "SPN" SG_ 2557148926 OpStationInCtrlLocation 9654;
BA_ "SigType" SG_ 2557148926 OpStationInCtrlLocation 1;
BA_ "SPN" SG_ 2557083390 EngTrollingModeSetSpd 9664;
BA_ "SigType" SG_ 2557083390 EngTrollingModeSetSpd 1;
BA_ "SPN" SG_ 2557083390 EngThrotSynchModeCmd 9663;
BA_ "SPN" SG_ 2557083390 TrollingModeSettingCmd 9662;
BA_ "SPN" SG_ 2557083390 OpStationLocationSetting 9661;
BA_ "SigType" SG_ 2557083390 OpStationLocationSetting 1;
BA_ "SPN" SG_ 2633785086 TotalAccumulatedCharge 8212;
BA_ "SigType" SG_ 2633785086 TotalAccumulatedCharge 1;
BA_ "SPN" SG_ 2633785086 TotalEnergyThroughput 8211;
BA_ "SigType" SG_ 2633785086 TotalEnergyThroughput 1;
BA_ "SPN" SG_ 2633785086 ContactorOpenUnderLoadCount 8122;
BA_ "SigType" SG_ 2633785086 ContactorOpenUnderLoadCount 1;
BA_ "SPN" SG_ 2633785086 StOfHealth 8121;
BA_ "SigType" SG_ 2633785086 StOfHealth 1;
BA_ "SPN" SG_ 2566675966 CellMinVLmt 8210;
BA_ "SigType" SG_ 2566675966 CellMinVLmt 1;
BA_ "SPN" SG_ 2566675966 CellMaxVLmt 8209;
BA_ "SigType" SG_ 2566675966 CellMaxVLmt 1;
BA_ "SPN" SG_ 2566675966 RecommendedMinOperatingTemp 8208;
BA_ "SigType" SG_ 2566675966 RecommendedMinOperatingTemp 1;
BA_ "SPN" SG_ 2566675966 RecommendedMaxOperatingTemp 8120;
BA_ "SigType" SG_ 2566675966 RecommendedMaxOperatingTemp 1;
BA_ "SPN" SG_ 2566675966 RecommendedMaxStOfCharge 8119;
BA_ "SigType" SG_ 2566675966 RecommendedMaxStOfCharge 1;
BA_ "SPN" SG_ 2566675966 RecommendedMinStOfCharge 8118;
BA_ "SigType" SG_ 2566675966 RecommendedMinStOfCharge 1;
BA_ "SPN" SG_ 2566675966 RecommendedMaxOperatingV 8117;
BA_ "SigType" SG_ 2566675966 RecommendedMaxOperatingV 1;
BA_ "SPN" SG_ 2566675966 RecommendedMinOperatingV 8116;
BA_ "SigType" SG_ 2566675966 RecommendedMinOperatingV 1;
BA_ "SPN" SG_ 2566675966 NominalV 8115;
BA_ "SigType" SG_ 2566675966 NominalV 1;
BA_ "SPN" SG_ 2566661886 Ctrl2Temp 7535;
BA_ "SigType" SG_ 2566661886 Ctrl2Temp 1;
BA_ "SPN" SG_ 2566661886 CtrlTemp 7529;
BA_ "SigType" SG_ 2566661886 CtrlTemp 1;
BA_ "SPN" SG_ 2566656254 EngIn2AirTemp 7850;
BA_ "SigType" SG_ 2566656254 EngIn2AirTemp 1;
BA_ "SPN" SG_ 2566656254 BarometricAbsPress2 7781;
BA_ "SigType" SG_ 2566656254 BarometricAbsPress2 1;
BA_ "SPN" SG_ 2566655998 PitchSensitivity 7801;
BA_ "SigType" SG_ 2566655998 PitchSensitivity 1;
BA_ "SPN" SG_ 2566655998 Sensitivity 7800;
BA_ "SigType" SG_ 2566655998 Sensitivity 1;
BA_ "SPN" SG_ 2566655742 PitchSensitivity 7813;
BA_ "SigType" SG_ 2566655742 PitchSensitivity 1;
BA_ "SPN" SG_ 2566655742 Sensitivity 7812;
BA_ "SigType" SG_ 2566655742 Sensitivity 1;
BA_ "SPN" SG_ 2633764350 EngagementCycles 7826;
BA_ "SigType" SG_ 2633764350 EngagementCycles 1;
BA_ "SPN" SG_ 2633764350 OpTime 7825;
BA_ "SigType" SG_ 2633764350 OpTime 1;
BA_ "SPN" SG_ 2633764094 GasolineFuelTankPress 7835;
BA_ "SigType" SG_ 2633764094 GasolineFuelTankPress 1;
BA_ "SPN" SG_ 2633764094 CanisterPurgeVlvCmd 7834;
BA_ "SigType" SG_ 2633764094 CanisterPurgeVlvCmd 1;
BA_ "SPN" SG_ 2633764094 CanisterVentVlv 7833;
BA_ "SigType" SG_ 2633764094 CanisterVentVlv 4;
BA_ "SPN" SG_ 2566654974 ActualMaxAvailableEngPercentFuel 8630;
BA_ "SigType" SG_ 2566654974 ActualMaxAvailableEngPercentFuel 1;
BA_ "SPN" SG_ 2566654974 EstEngParasiticLossesPercentTrq 7837;
BA_ "SigType" SG_ 2566654974 EstEngParasiticLossesPercentTrq 1;
BA_ "SPN" SG_ 2566654718 SLIBatPack1Bat1V 7902;
BA_ "SigType" SG_ 2566654718 SLIBatPack1Bat1V 1;
BA_ "SPN" SG_ 2566654718 SLIBatPack1Bat1Temp 7901;
BA_ "SigType" SG_ 2566654718 SLIBatPack1Bat1Temp 1;
BA_ "SPN" SG_ 2566654718 SLIBatPack1Bat1NetCur 7900;
BA_ "SigType" SG_ 2566654718 SLIBatPack1Bat1NetCur 1;
BA_ "SPN" SG_ 2566654462 SLIBatPack1Snsr1InitStatus 7907;
BA_ "SPN" SG_ 2566654462 SLIBatPack1Bat1PredMinCrankingV 7906;
BA_ "SigType" SG_ 2566654462 SLIBatPack1Bat1PredMinCrankingV 1;
BA_ "SPN" SG_ 2566654462 SLIBatPack1Bat1Health 7905;
BA_ "SigType" SG_ 2566654462 SLIBatPack1Bat1Health 1;
BA_ "SPN" SG_ 2566654462 SLIBatPack1Bat1Capacity 7904;
BA_ "SigType" SG_ 2566654462 SLIBatPack1Bat1Capacity 1;
BA_ "SPN" SG_ 2566654462 SLIBatPack1Bat1StOfCharge 7903;
BA_ "SigType" SG_ 2566654462 SLIBatPack1Bat1StOfCharge 1;
BA_ "SPN" SG_ 2566654206 SLIBatPack1Bat2V 7910;
BA_ "SigType" SG_ 2566654206 SLIBatPack1Bat2V 1;
BA_ "SPN" SG_ 2566654206 SLIBatPack1Bat2Temp 7909;
BA_ "SigType" SG_ 2566654206 SLIBatPack1Bat2Temp 1;
BA_ "SPN" SG_ 2566654206 SLIBatPack1Bat2NetCur 7908;
BA_ "SigType" SG_ 2566654206 SLIBatPack1Bat2NetCur 1;
BA_ "SPN" SG_ 2566653950 SLIBatPack1Snsr2InitStatus 7915;
BA_ "SPN" SG_ 2566653950 SLIBatPack1Bat2PredMinCrankingV 7914;
BA_ "SigType" SG_ 2566653950 SLIBatPack1Bat2PredMinCrankingV 1;
BA_ "SPN" SG_ 2566653950 SLIBatPack1Bat2Health 7913;
BA_ "SigType" SG_ 2566653950 SLIBatPack1Bat2Health 1;
BA_ "SPN" SG_ 2566653950 SLIBatPack1Bat2Capacity 7912;
BA_ "SigType" SG_ 2566653950 SLIBatPack1Bat2Capacity 1;
BA_ "SPN" SG_ 2566653950 SLIBatPack1Bat2StOfCharge 7911;
BA_ "SigType" SG_ 2566653950 SLIBatPack1Bat2StOfCharge 1;
BA_ "SPN" SG_ 2566653694 SLIBatPack1Bat3V 7918;
BA_ "SigType" SG_ 2566653694 SLIBatPack1Bat3V 1;
BA_ "SPN" SG_ 2566653694 SLIBatPack1Bat3Temp 7917;
BA_ "SigType" SG_ 2566653694 SLIBatPack1Bat3Temp 1;
BA_ "SPN" SG_ 2566653694 SLIBatPack1Bat3NetCur 7916;
BA_ "SigType" SG_ 2566653694 SLIBatPack1Bat3NetCur 1;
BA_ "SPN" SG_ 2566653438 SLIBatPack1Snsr3InitStatus 7923;
BA_ "SPN" SG_ 2566653438 SLIBatPack1Bat3PredMinCrankingV 7922;
BA_ "SigType" SG_ 2566653438 SLIBatPack1Bat3PredMinCrankingV 1;
BA_ "SPN" SG_ 2566653438 SLIBatPack1Bat3Health 7921;
BA_ "SigType" SG_ 2566653438 SLIBatPack1Bat3Health 1;
BA_ "SPN" SG_ 2566653438 SLIBatPack1Bat3Capacity 7920;
BA_ "SigType" SG_ 2566653438 SLIBatPack1Bat3Capacity 1;
BA_ "SPN" SG_ 2566653438 SLIBatPack1Bat3StOfCharge 7919;
BA_ "SigType" SG_ 2566653438 SLIBatPack1Bat3StOfCharge 1;
BA_ "SPN" SG_ 2566653182 SLIBatPack1Bat4V 7926;
BA_ "SigType" SG_ 2566653182 SLIBatPack1Bat4V 1;
BA_ "SPN" SG_ 2566653182 SLIBatPack1Bat4Temp 7925;
BA_ "SigType" SG_ 2566653182 SLIBatPack1Bat4Temp 1;
BA_ "SPN" SG_ 2566653182 SLIBatPack1Bat4NetCur 7924;
BA_ "SigType" SG_ 2566653182 SLIBatPack1Bat4NetCur 1;
BA_ "SPN" SG_ 2566652926 SLIBatPack1Snsr4InitStatus 7931;
BA_ "SPN" SG_ 2566652926 SLIBatPack1Bat4PredMinCrankingV 7930;
BA_ "SigType" SG_ 2566652926 SLIBatPack1Bat4PredMinCrankingV 1;
BA_ "SPN" SG_ 2566652926 SLIBatPack1Bat4Health 7929;
BA_ "SigType" SG_ 2566652926 SLIBatPack1Bat4Health 1;
BA_ "SPN" SG_ 2566652926 SLIBatPack1Bat4Capacity 7928;
BA_ "SigType" SG_ 2566652926 SLIBatPack1Bat4Capacity 1;
BA_ "SPN" SG_ 2566652926 SLIBatPack1Bat4StOfCharge 7927;
BA_ "SigType" SG_ 2566652926 SLIBatPack1Bat4StOfCharge 1;
BA_ "SPN" SG_ 2566652670 AFT2SCRSysHydrocarbon 7935;
BA_ "SigType" SG_ 2566652670 AFT2SCRSysHydrocarbon 1;
BA_ "SPN" SG_ 2566652670 AFT2DEFDosingSysFrozen 6803;
BA_ "SigType" SG_ 2566652670 AFT2DEFDosingSysFrozen 5;
BA_ "SPN" SG_ 2566652670 AFT1DEFDosingSysFrozen 6802;
BA_ "SigType" SG_ 2566652670 AFT1DEFDosingSysFrozen 5;
BA_ "SPN" SG_ 2566652670 AFT1SCRSysHydrocarbon 7934;
BA_ "SigType" SG_ 2566652670 AFT1SCRSysHydrocarbon 1;
BA_ "SPN" SG_ 2566652670 DEFFrozenTime 7938;
BA_ "SigType" SG_ 2566652670 DEFFrozenTime 1;
BA_ "SPN" SG_ 2566652414 Instance 8308;
BA_ "SPN" SG_ 2566652414 OperatingStatus 7954;
BA_ "SigType" SG_ 2566652414 OperatingStatus 5;
BA_ "SPN" SG_ 2566652414 ServiceInd 7953;
BA_ "SigType" SG_ 2566652414 ServiceInd 5;
BA_ "SPN" SG_ 2566652414 Pwr 7952;
BA_ "SigType" SG_ 2566652414 Pwr 1;
BA_ "SPN" SG_ 2566652414 MediumTemp 7951;
BA_ "SigType" SG_ 2566652414 MediumTemp 1;
BA_ "SPN" SG_ 2566652414 Spd 7950;
BA_ "SigType" SG_ 2566652414 Spd 1;
BA_ "SPN" SG_ 2566652414 CtrlCmdStatus 7949;
BA_ "SigType" SG_ 2566652414 CtrlCmdStatus 5;
BA_ "SPN" SG_ 2566652414 CtrlStatusReasonCode 7948;
BA_ "SPN" SG_ 2566652414 EnableStatus 7947;
BA_ "SigType" SG_ 2566652414 EnableStatus 5;
BA_ "SPN" SG_ 2566651902 OperatingStatus 7978;
BA_ "SigType" SG_ 2566651902 OperatingStatus 5;
BA_ "SPN" SG_ 2566651902 ServiceInd 7977;
BA_ "SigType" SG_ 2566651902 ServiceInd 5;
BA_ "SPN" SG_ 2566651902 Pwr 7976;
BA_ "SigType" SG_ 2566651902 Pwr 1;
BA_ "SPN" SG_ 2566651902 CtrlTemp 7975;
BA_ "SigType" SG_ 2566651902 CtrlTemp 1;
BA_ "SPN" SG_ 2566651902 MotorSpd 7974;
BA_ "SigType" SG_ 2566651902 MotorSpd 1;
BA_ "SPN" SG_ 2566651902 CtrlCmdStatus 7973;
BA_ "SigType" SG_ 2566651902 CtrlCmdStatus 5;
BA_ "SPN" SG_ 2566651902 CtrlStatusReasonCode 7972;
BA_ "SPN" SG_ 2566651902 EnableStatus 7971;
BA_ "SigType" SG_ 2566651902 EnableStatus 5;
BA_ "SPN" SG_ 2566651646 OperatingStatus 7990;
BA_ "SigType" SG_ 2566651646 OperatingStatus 5;
BA_ "SPN" SG_ 2566651646 ServiceInd 7989;
BA_ "SigType" SG_ 2566651646 ServiceInd 5;
BA_ "SPN" SG_ 2566651646 Pwr 7988;
BA_ "SigType" SG_ 2566651646 Pwr 1;
BA_ "SPN" SG_ 2566651646 CtrlTemp 7987;
BA_ "SigType" SG_ 2566651646 CtrlTemp 1;
BA_ "SPN" SG_ 2566651646 MotorSpd 7986;
BA_ "SigType" SG_ 2566651646 MotorSpd 1;
BA_ "SPN" SG_ 2566651646 CtrlCmdStatus 7985;
BA_ "SigType" SG_ 2566651646 CtrlCmdStatus 5;
BA_ "SPN" SG_ 2566651646 CtrlStatusReasonCode 7984;
BA_ "SPN" SG_ 2566651646 EnableStatus 7983;
BA_ "SigType" SG_ 2566651646 EnableStatus 5;
BA_ "SPN" SG_ 2566651390 OperatingStatus 8002;
BA_ "SigType" SG_ 2566651390 OperatingStatus 5;
BA_ "SPN" SG_ 2566651390 ServiceInd 8001;
BA_ "SigType" SG_ 2566651390 ServiceInd 5;
BA_ "SPN" SG_ 2566651390 Pwr 8000;
BA_ "SigType" SG_ 2566651390 Pwr 1;
BA_ "SPN" SG_ 2566651390 CtrlTemp 7999;
BA_ "SigType" SG_ 2566651390 CtrlTemp 1;
BA_ "SPN" SG_ 2566651390 MotorSpd 7998;
BA_ "SigType" SG_ 2566651390 MotorSpd 1;
BA_ "SPN" SG_ 2566651390 CtrlCmdStatus 7997;
BA_ "SigType" SG_ 2566651390 CtrlCmdStatus 5;
BA_ "SPN" SG_ 2566651390 CtrlStatusReasonCode 7996;
BA_ "SPN" SG_ 2566651390 EnableStatus 7995;
BA_ "SigType" SG_ 2566651390 EnableStatus 5;
BA_ "SPN" SG_ 2566651134 OperatingStatus 8014;
BA_ "SigType" SG_ 2566651134 OperatingStatus 5;
BA_ "SPN" SG_ 2566651134 ServiceInd 8013;
BA_ "SigType" SG_ 2566651134 ServiceInd 5;
BA_ "SPN" SG_ 2566651134 Pwr 8012;
BA_ "SigType" SG_ 2566651134 Pwr 1;
BA_ "SPN" SG_ 2566651134 CtrlTemp 8011;
BA_ "SigType" SG_ 2566651134 CtrlTemp 1;
BA_ "SPN" SG_ 2566651134 MotorSpd 8010;
BA_ "SigType" SG_ 2566651134 MotorSpd 1;
BA_ "SPN" SG_ 2566651134 CtrlCmdStatus 8009;
BA_ "SigType" SG_ 2566651134 CtrlCmdStatus 5;
BA_ "SPN" SG_ 2566651134 CtrlStatusReasonCode 8008;
BA_ "SPN" SG_ 2566651134 EnableStatus 8007;
BA_ "SigType" SG_ 2566651134 EnableStatus 5;
BA_ "SPN" SG_ 2566650878 OperatingStatus 8026;
BA_ "SigType" SG_ 2566650878 OperatingStatus 5;
BA_ "SPN" SG_ 2566650878 ServiceInd 8025;
BA_ "SigType" SG_ 2566650878 ServiceInd 5;
BA_ "SPN" SG_ 2566650878 Pwr 8024;
BA_ "SigType" SG_ 2566650878 Pwr 1;
BA_ "SPN" SG_ 2566650878 CtrlTemp 8023;
BA_ "SigType" SG_ 2566650878 CtrlTemp 1;
BA_ "SPN" SG_ 2566650878 MotorSpd 8022;
BA_ "SigType" SG_ 2566650878 MotorSpd 1;
BA_ "SPN" SG_ 2566650878 CtrlCmdStatus 8021;
BA_ "SigType" SG_ 2566650878 CtrlCmdStatus 5;
BA_ "SPN" SG_ 2566650878 CtrlStatusReasonCode 8020;
BA_ "SPN" SG_ 2566650878 EnableStatus 8019;
BA_ "SigType" SG_ 2566650878 EnableStatus 5;
BA_ "SPN" SG_ 2566650622 OperatingStatus 8038;
BA_ "SigType" SG_ 2566650622 OperatingStatus 5;
BA_ "SPN" SG_ 2566650622 ServiceInd 8037;
BA_ "SigType" SG_ 2566650622 ServiceInd 5;
BA_ "SPN" SG_ 2566650622 Pwr 8036;
BA_ "SigType" SG_ 2566650622 Pwr 1;
BA_ "SPN" SG_ 2566650622 CtrlTemp 8035;
BA_ "SigType" SG_ 2566650622 CtrlTemp 1;
BA_ "SPN" SG_ 2566650622 MotorSpd 8034;
BA_ "SigType" SG_ 2566650622 MotorSpd 1;
BA_ "SPN" SG_ 2566650622 CtrlCmdStatus 8033;
BA_ "SigType" SG_ 2566650622 CtrlCmdStatus 5;
BA_ "SPN" SG_ 2566650622 CtrlStatusReasonCode 8032;
BA_ "SPN" SG_ 2566650622 EnableStatus 8031;
BA_ "SigType" SG_ 2566650622 EnableStatus 5;
BA_ "SPN" SG_ 2566650366 OperatingStatus 8050;
BA_ "SigType" SG_ 2566650366 OperatingStatus 5;
BA_ "SPN" SG_ 2566650366 ServiceInd 8049;
BA_ "SigType" SG_ 2566650366 ServiceInd 5;
BA_ "SPN" SG_ 2566650366 Pwr 8048;
BA_ "SigType" SG_ 2566650366 Pwr 1;
BA_ "SPN" SG_ 2566650366 CtrlTemp 8047;
BA_ "SigType" SG_ 2566650366 CtrlTemp 1;
BA_ "SPN" SG_ 2566650366 MotorSpd 8046;
BA_ "SigType" SG_ 2566650366 MotorSpd 1;
BA_ "SPN" SG_ 2566650366 CtrlCmdStatus 8045;
BA_ "SigType" SG_ 2566650366 CtrlCmdStatus 5;
BA_ "SPN" SG_ 2566650366 CtrlStatusReasonCode 8044;
BA_ "SPN" SG_ 2566650366 EnableStatus 8043;
BA_ "SigType" SG_ 2566650366 EnableStatus 5;
BA_ "SPN" SG_ 2566650110 OperatingStatus 8062;
BA_ "SigType" SG_ 2566650110 OperatingStatus 5;
BA_ "SPN" SG_ 2566650110 ServiceInd 8061;
BA_ "SigType" SG_ 2566650110 ServiceInd 5;
BA_ "SPN" SG_ 2566650110 Pwr 8060;
BA_ "SigType" SG_ 2566650110 Pwr 1;
BA_ "SPN" SG_ 2566650110 CtrlTemp 8059;
BA_ "SigType" SG_ 2566650110 CtrlTemp 1;
BA_ "SPN" SG_ 2566650110 MotorSpd 8058;
BA_ "SigType" SG_ 2566650110 MotorSpd 1;
BA_ "SPN" SG_ 2566650110 CtrlCmdStatus 8057;
BA_ "SigType" SG_ 2566650110 CtrlCmdStatus 5;
BA_ "SPN" SG_ 2566650110 CtrlStatusReasonCode 8056;
BA_ "SPN" SG_ 2566650110 EnableStatus 8055;
BA_ "SigType" SG_ 2566650110 EnableStatus 5;
BA_ "SPN" SG_ 2566649854 OperatingStatus 8074;
BA_ "SigType" SG_ 2566649854 OperatingStatus 5;
BA_ "SPN" SG_ 2566649854 ServiceInd 8073;
BA_ "SigType" SG_ 2566649854 ServiceInd 5;
BA_ "SPN" SG_ 2566649854 Pwr 8072;
BA_ "SigType" SG_ 2566649854 Pwr 1;
BA_ "SPN" SG_ 2566649854 CtrlTemp 8071;
BA_ "SigType" SG_ 2566649854 CtrlTemp 1;
BA_ "SPN" SG_ 2566649854 MotorSpd 8070;
BA_ "SigType" SG_ 2566649854 MotorSpd 1;
BA_ "SPN" SG_ 2566649854 CtrlCmdStatus 8069;
BA_ "SigType" SG_ 2566649854 CtrlCmdStatus 5;
BA_ "SPN" SG_ 2566649854 CtrlStatusReasonCode 8068;
BA_ "SPN" SG_ 2566649854 EnableStatus 8067;
BA_ "SigType" SG_ 2566649854 EnableStatus 5;
BA_ "SPN" SG_ 2566649598 TimeDilutionOfPrecision 8132;
BA_ "SigType" SG_ 2566649598 TimeDilutionOfPrecision 1;
BA_ "SPN" SG_ 2566649598 DilutionOfPrecision 8131;
BA_ "SigType" SG_ 2566649598 DilutionOfPrecision 1;
BA_ "SPN" SG_ 2566649598 VerticalDilutionOfPrecision 8130;
BA_ "SigType" SG_ 2566649598 VerticalDilutionOfPrecision 1;
BA_ "SPN" SG_ 2566649598 HorizontalDilutionOfPrecision 8129;
BA_ "SigType" SG_ 2566649598 HorizontalDilutionOfPrecision 1;
BA_ "SPN" SG_ 2566649598 TotalNumOfSatellitesInView 8128;
BA_ "SigType" SG_ 2566649598 TotalNumOfSatellitesInView 1;
BA_ "SPN" SG_ 2566649342 DOCInToDPFOutDeltaPress 8162;
BA_ "SigType" SG_ 2566649342 DOCInToDPFOutDeltaPress 1;
BA_ "SPN" SG_ 2566649342 OutPress 8161;
BA_ "SigType" SG_ 2566649342 OutPress 1;
BA_ "SPN" SG_ 2566649342 InPress 8160;
BA_ "SigType" SG_ 2566649342 InPress 1;
BA_ "SPN" SG_ 2566649086 DOCInToDPFOutDeltaPress 8165;
BA_ "SigType" SG_ 2566649086 DOCInToDPFOutDeltaPress 1;
BA_ "SPN" SG_ 2566649086 OutPress 8164;
BA_ "SigType" SG_ 2566649086 OutPress 1;
BA_ "SPN" SG_ 2566649086 InPress 8163;
BA_ "SigType" SG_ 2566649086 InPress 1;
BA_ "SPN" SG_ 2365322238 DirVS 8166;
BA_ "SigType" SG_ 2365322238 DirVS 1;
BA_ "SPN" SG_ 2566648318 MonitorETempStatus 8190;
BA_ "SigType" SG_ 2566648318 MonitorETempStatus 5;
BA_ "SPN" SG_ 2566648318 MonitorSPEStatus 8189;
BA_ "SigType" SG_ 2566648318 MonitorSPEStatus 5;
BA_ "SPN" SG_ 2566648318 MonitorSensingElementStatus 8188;
BA_ "SigType" SG_ 2566648318 MonitorSensingElementStatus 5;
BA_ "SPN" SG_ 2566648318 MonitorEnvironmentStatus 8187;
BA_ "SigType" SG_ 2566648318 MonitorEnvironmentStatus 5;
BA_ "SPN" SG_ 2566648318 MonitorTotalNumOfSensors 8186;
BA_ "SigType" SG_ 2566648318 MonitorTotalNumOfSensors 1;
BA_ "SPN" SG_ 2566648318 MonitorStatusIdNum 8185;
BA_ "SigType" SG_ 2566648318 MonitorStatusIdNum 1;
BA_ "SPN" SG_ 2566648062 NFBin6Count 8184;
BA_ "SPN" SG_ 2566648062 NFBin5Count 8183;
BA_ "SPN" SG_ 2566648062 NFBins5And6IdNum 8182;
BA_ "SigType" SG_ 2566648062 NFBins5And6IdNum 1;
BA_ "SPN" SG_ 2566647806 NFBin4Count 8181;
BA_ "SPN" SG_ 2566647806 NFBin3Count 8180;
BA_ "SPN" SG_ 2566647806 NFBins3And4IdNum 8179;
BA_ "SigType" SG_ 2566647806 NFBins3And4IdNum 1;
VAL_ 2565942782 PLedDueToUndefinedReason 3 "Not Available" 2 "Error" 1 "Power limited for this reason" 0 "No power limit for this reason" ;
VAL_ 2565942782 PLedDueToRateOfChangeLmt 3 "Not Available" 2 "Error" 1 "Frequency limited for this reason" 0 "No frequency limit for this reason" ;
VAL_ 2565942782 PLedDueToPwrETemp 3 "Not Available" 2 "Error" 1 "Frequency limited for this reason" 0 "No frequency limit for this reason" ;
VAL_ 2565942782 PLedDueToEFilterTemp 3 "Not Available" 2 "Error" 1 "Frequency limited for this reason" 0 "No frequency limit for this reason" ;
VAL_ 2565942782 PLedDueToCtrlTemp 3 "Not Available" 2 "Error" 1 "Power limited for this reason" 0 "No power limit for this reason" ;
VAL_ 2565942782 FreqCmdExceedsMax 3 "Not Available" 2 "Error" 1 "Frequency limited for this reason" 0 "No frequency limit for this reason" ;
VAL_ 2565942782 FreqCmdBelowMin 3 "Not Available" 2 "Error" 1 "Frequency limited for this reason" 0 "No frequency limit for this reason" ;
VAL_ 2565942782 PLedDueToDCSideVMin 3 "Not Available" 2 "Error" 1 "Power limited for this reason" 0 "No power limit for this reason" ;
VAL_ 2565942782 PLedDueToACSideRMSCur 3 "Not Available" 2 "Error" 1 "Power limited for this reason" 0 "No power limit for this reason" ;
VAL_ 2565942782 PLedDueToDCSideCur 3 "Not Available" 2 "Error" 1 "Power limited for this reason" 0 "No power limit for this reason" ;
VAL_ 2565942014 PLedDueToUndefinedReason 3 "Not Available" 2 "Error" 1 "Power limited for this reason" 0 "No power limit for this reason" ;
VAL_ 2565942014 PLedDueToRateOfChangeLmt 3 "Not Available" 2 "Error" 1 "Frequency limited for this reason" 0 "No frequency limit for this reason" ;
VAL_ 2565942014 PLedDueToPwrETemp 3 "Not Available" 2 "Error" 1 "Frequency limited for this reason" 0 "No frequency limit for this reason" ;
VAL_ 2565942014 PLedDueToEFilterTemp 3 "Not Available" 2 "Error" 1 "Frequency limited for this reason" 0 "No frequency limit for this reason" ;
VAL_ 2565942014 PLedDueToCtrlTemp 3 "Not Available" 2 "Error" 1 "Power limited for this reason" 0 "No power limit for this reason" ;
VAL_ 2565942014 FreqCmdExceedsMax 3 "Not Available" 2 "Error" 1 "Frequency limited for this reason" 0 "No frequency limit for this reason" ;
VAL_ 2565942014 FreqCmdBelowMin 3 "Not Available" 2 "Error" 1 "Frequency limited for this reason" 0 "No frequency limit for this reason" ;
VAL_ 2565942014 PLedDueToDCSideVMin 3 "Not Available" 2 "Error" 1 "Power limited for this reason" 0 "No power limit for this reason" ;
VAL_ 2565942014 PLedDueToACSideRMSCur 3 "Not Available" 2 "Error" 1 "Power limited for this reason" 0 "No power limit for this reason" ;
VAL_ 2565942014 PLedDueToDCSideCur 3 "Not Available" 2 "Error" 1 "Power limited for this reason" 0 "No power limit for this reason" ;
VAL_ 2364614654 GradeThresholdInd6 3 "Not Available" 2 "Error" 1 "Current grade is equal to or exceeds the threshold" 0 "Current grade does not exceed the threshold" ;
VAL_ 2364614654 GradeThresholdInd5 3 "Not Available" 2 "Error" 1 "Current grade is equal to or exceeds the threshold" 0 "Current grade does not exceed the threshold" ;
VAL_ 2364614654 GradeThresholdInd4 3 "Not Available" 2 "Error" 1 "Current grade is equal to or exceeds the threshold" 0 "Current grade does not exceed the threshold" ;
VAL_ 2364614654 GradeThresholdInd3 3 "Not Available" 2 "Error" 1 "Current grade is equal to or exceeds the threshold" 0 "Current grade does not exceed the threshold" ;
VAL_ 2364614654 GradeThresholdInd2 3 "Not Available" 2 "Error" 1 "Current grade is equal to or exceeds the threshold" 0 "Current grade does not exceed the threshold" ;
VAL_ 2364614654 GradeThresholdInd1 3 "Not Available" 2 "Error" 1 "Current grade is equal to or exceeds the threshold" 0 "Current grade does not exceed the threshold" ;
VAL_ 2364613630 FourPLDueToUndefinedReason 3 "Not Available" 2 "Error" 1 "Power limited for this reason" 0 "No power limit for this reason" ;
VAL_ 2364613630 FourPLDueToSLIBatTermTemp 3 "Not Available" 2 "Error" 1 "Power limited for this reason" 0 "No power limit for this reason" ;
VAL_ 2364613630 FourPLDueToSLIBatTermCur 3 "Not Available" 2 "Error" 1 "Power limited for this reason" 0 "No power limit for this reason" ;
VAL_ 2364613630 FourPLDueToSLIBatTermV 3 "Not Available" 2 "Error" 1 "Power limited for this reason" 0 "No power limit for this reason" ;
VAL_ 2364613630 FourPLDueToPwrETemp 3 "Not Available" 2 "Error" 1 "Power limited for this reason" 0 "No power limit for this reason" ;
VAL_ 2364613630 FourPLDueToEFilterTemp 3 "Not available" 2 "Error" 1 "Power limited for this reason" 0 "No power limit for this reason" ;
VAL_ 2364613630 FourPLDueToConvTemp 3 "Not Available" 2 "Error" 1 "Power limited for this reason" 0 "No power limit for this reason" ;
VAL_ 2364613630 FourPLDueToLowSideVMax 3 "Not Available" 2 "Error" 1 "Power limited for this reason" 0 "No power limit for this reason" ;
VAL_ 2364613630 FourPLDueToLowSideVMin 3 "Not Available" 2 "Error" 1 "Power limited for this reason" 0 "No power limit for this reason" ;
VAL_ 2364613630 FourPLDueToHiSideVMax 3 "Not Available" 2 "Error" 1 "Power limited for this reason" 0 "No power limit for this reason" ;
VAL_ 2364613630 FourPLDueToHiSideVMin 3 "Not Available" 2 "Error" 1 "Power limited for this reason" 0 "No power limit for this reason" ;
VAL_ 2364613630 FourPLDueToLowSideCur 3 "Not Available" 2 "Error" 1 "Power limited for this reason" 0 "No power limit for this reason" ;
VAL_ 2364613630 FourPLDueToHiSideCur 3 "Not Available" 2 "Error" 1 "Power limited for this reason" 0 "No power limit for this reason" ;
VAL_ 2364613630 FourLoadshedReq 3 "Don't Care/Take No Action" 2 "Loadshed Requested,  Shutdown Imminent" 1 "Loadshed Requested" 0 "No Loadshed Requested" ;
VAL_ 2364613630 FourHVILStatus 3 "Not Available" 2 "Error" 1 "HVIL Open" 0 "HVIL Closed" ;
VAL_ 2364613630 FourOperationalStatus 15 "Not Available" 14 "Error" 13 "Manufacturer assignable state" 12 "Reserved" 11 "Reserved" 10 "Reserved" 9 "Reserved" 8 "Reserved" 7 "Reserved" 6 "Disabled due to malfunction or protection" 5 "Normal power down in process" 4 "Operational, Boost mode" 3 "Operational, Buck mode" 2 "Operational, Standby" 1 "Initialization in process" 0 "Disabled" ;
VAL_ 2364613374 FourOperationalCmd 15 "Don't care/ Take No Action" 13 "Reserved" 12 "Reserved" 11 "Reserved" 10 "Reserved" 9 "Reserved" 8 "Reserved" 7 "Reserved" 6 "Reserved" 5 "Reserved" 4 "Power down DC/DC Converter" 3 "Operate in boost mode" 2 "Operate in buck mode" 1 "Operate in standby mode" 0 "Disable" ;
VAL_ 2364612350 ThreePLDueToUndefinedReason 3 "Not Available" 2 "Error" 1 "Power limited for this reason" 0 "No power limit for this reason" ;
VAL_ 2364612350 ThreePLDueToSLIBatTermTemp 3 "Not Available" 2 "Error" 1 "Power limited for this reason" 0 "No power limit for this reason" ;
VAL_ 2364612350 ThreePLDueToSLIBatTermCur 3 "Not Available" 2 "Error" 1 "Power limited for this reason" 0 "No power limit for this reason" ;
VAL_ 2364612350 ThreePLDueToSLIBatTermV 3 "Not Available" 2 "Error" 1 "Power limited for this reason" 0 "No power limit for this reason" ;
VAL_ 2364612350 ThreePLDueToPwrETemp 3 "Not Available" 2 "Error" 1 "Power limited for this reason" 0 "No power limit for this reason" ;
VAL_ 2364612350 ThreePLDueToEFilterTemp 3 "Not available" 2 "Error" 1 "Power limited for this reason" 0 "No power limit for this reason" ;
VAL_ 2364612350 ThreePLDueToConvTemp 3 "Not Available" 2 "Error" 1 "Power limited for this reason" 0 "No power limit for this reason" ;
VAL_ 2364612350 ThreePLDueToLowSideVMax 3 "Not Available" 2 "Error" 1 "Power limited for this reason" 0 "No power limit for this reason" ;
VAL_ 2364612350 ThreePLDueToLowSideVMin 3 "Not Available" 2 "Error" 1 "Power limited for this reason" 0 "No power limit for this reason" ;
VAL_ 2364612350 ThreePLDueToHiSideVMax 3 "Not Available" 2 "Error" 1 "Power limited for this reason" 0 "No power limit for this reason" ;
VAL_ 2364612350 ThreePLDueToHiSideVMin 3 "Not Available" 2 "Error" 1 "Power limited for this reason" 0 "No power limit for this reason" ;
VAL_ 2364612350 ThreePLDueToLowSideCur 3 "Not Available" 2 "Error" 1 "Power limited for this reason" 0 "No power limit for this reason" ;
VAL_ 2364612350 ThreePLDueToHiSideCur 3 "Not Available" 2 "Error" 1 "Power limited for this reason" 0 "No power limit for this reason" ;
VAL_ 2364612350 ThreeLoadshedReq 3 "Don't Care/Take No Action" 2 "Loadshed Requested,  Shutdown Imminent" 1 "Loadshed Requested" 0 "No Loadshed Requested" ;
VAL_ 2364612350 ThreeHVILStatus 3 "Not Available" 2 "Error" 1 "HVIL Open" 0 "HVIL Closed" ;
VAL_ 2364612350 ThreeOperationalStatus 15 "Not Available" 14 "Error" 13 "Manufacturer assignable state" 12 "Reserved" 11 "Reserved" 10 "Reserved" 9 "Reserved" 8 "Reserved" 7 "Reserved" 6 "Disabled due to malfunction or protection" 5 "Normal power down in process" 4 "Operational, Boost mode" 3 "Operational, Buck mode" 2 "Operational, Standby" 1 "Initialization in process" 0 "Disabled" ;
VAL_ 2364612094 ThreeOperationalCmd 15 "Don't care/ Take No Action" 13 "Reserved" 12 "Reserved" 11 "Reserved" 10 "Reserved" 9 "Reserved" 8 "Reserved" 7 "Reserved" 6 "Reserved" 5 "Reserved" 4 "Power down DC/DC Converter" 3 "Operate in boost mode" 2 "Operate in buck mode" 1 "Operate in standby mode" 0 "Disable" ;
VAL_ 2364611070 TwoPLDueToUndefinedReason 3 "Not Available" 2 "Error" 1 "Power limited for this reason" 0 "No power limit for this reason" ;
VAL_ 2364611070 TwoPLDueToSLIBatTermTemp 3 "Not Available" 2 "Error" 1 "Power limited for this reason" 0 "No power limit for this reason" ;
VAL_ 2364611070 TwoPLDueToSLIBatTermCur 3 "Not Available" 2 "Error" 1 "Power limited for this reason" 0 "No power limit for this reason" ;
VAL_ 2364611070 TwoPLDueToSLIBatTermV 3 "Not Available" 2 "Error" 1 "Power limited for this reason" 0 "No power limit for this reason" ;
VAL_ 2364611070 TwoPLDueToPwrETemp 3 "Not Available" 2 "Error" 1 "Power limited for this reason" 0 "No power limit for this reason" ;
VAL_ 2364611070 TwoPLDueToEFilterTemp 3 "Not available" 2 "Error" 1 "Power limited for this reason" 0 "No power limit for this reason" ;
VAL_ 2364611070 TwoPLDueToConvTemp 3 "Not Available" 2 "Error" 1 "Power limited for this reason" 0 "No power limit for this reason" ;
VAL_ 2364611070 TwoPLDueToLowSideVMax 3 "Not Available" 2 "Error" 1 "Power limited for this reason" 0 "No power limit for this reason" ;
VAL_ 2364611070 TwoPLDueToLowSideVMin 3 "Not Available" 2 "Error" 1 "Power limited for this reason" 0 "No power limit for this reason" ;
VAL_ 2364611070 TwoPLDueToHiSideVMax 3 "Not Available" 2 "Error" 1 "Power limited for this reason" 0 "No power limit for this reason" ;
VAL_ 2364611070 TwoPLDueToHiSideVMin 3 "Not Available" 2 "Error" 1 "Power limited for this reason" 0 "No power limit for this reason" ;
VAL_ 2364611070 TwoPLDueToLowSideCur 3 "Not Available" 2 "Error" 1 "Power limited for this reason" 0 "No power limit for this reason" ;
VAL_ 2364611070 TwoPLDueToHiSideCur 3 "Not Available" 2 "Error" 1 "Power limited for this reason" 0 "No power limit for this reason" ;
VAL_ 2364611070 TwoLoadshedReq 3 "Don't Care/Take No Action" 2 "Loadshed Requested,  Shutdown Imminent" 1 "Loadshed Requested" 0 "No Loadshed Requested" ;
VAL_ 2364611070 TwoHVILStatus 3 "Not Available" 2 "Error" 1 "HVIL Open" 0 "HVIL Closed" ;
VAL_ 2364611070 TwoOperationalStatus 15 "Not Available" 14 "Error" 13 "Manufacturer assignable state" 12 "Reserved" 11 "Reserved" 10 "Reserved" 9 "Reserved" 8 "Reserved" 7 "Reserved" 6 "Disabled due to malfunction or protection" 5 "Normal power down in process" 4 "Operational, Boost mode" 3 "Operational, Buck mode" 2 "Operational, Standby" 1 "Initialization in process" 0 "Disabled" ;
VAL_ 2364610814 TwoOperationalCmd 11 "Reserved" 10 "Reserved" 9 "Reserved" 8 "Reserved" 7 "Reserved" 6 "Reserved" 5 "Reserved" 4 "Power down DC/DC Converter" 3 "Operate in boost mode" 2 "Operate in buck mode" 15 "Don't care/ Take No Action" 13 "Reserved" 12 "Reserved" 1 "Operate in standby mode" 0 "Disable" ;
VAL_ 2565918206 PLedDueToUndefinedReason 3 "Not Available" 2 "Error" 1 "Power limited for this reason" 0 "No power limit for this reason" ;
VAL_ 2565918206 PLedDueToRateOfChangeLmt 3 "Not Available" 2 "Error" 1 "Frequency limited for this reason" 0 "No frequency limit for this reason" ;
VAL_ 2565918206 PLedDueToPwrETemp 3 "Not Available" 2 "Error" 1 "Frequency limited for this reason" 0 "No frequency limit for this reason" ;
VAL_ 2565918206 PLedDueToEFilterTemp 3 "Not Available" 2 "Error" 1 "Frequency limited for this reason" 0 "No frequency limit for this reason" ;
VAL_ 2565918206 PLedDueToCtrlTemp 3 "Not Available" 2 "Error" 1 "Power limited for this reason" 0 "No power limit for this reason" ;
VAL_ 2565918206 FreqCmdExceedsMax 3 "Not Available" 2 "Error" 1 "Frequency limited for this reason" 0 "No frequency limit for this reason" ;
VAL_ 2565918206 FreqCmdBelowMin 3 "Not Available" 2 "Error" 1 "Frequency limited for this reason" 0 "No frequency limit for this reason" ;
VAL_ 2565918206 PLedDueToDCSideVMin 3 "Not Available" 2 "Error" 1 "Power limited for this reason" 0 "No power limit for this reason" ;
VAL_ 2565918206 PLedDueToACSideRMSCur 3 "Not Available" 2 "Error" 1 "Power limited for this reason" 0 "No power limit for this reason" ;
VAL_ 2565918206 PLedDueToDCSideCur 3 "Not Available" 2 "Error" 1 "Power limited for this reason" 0 "No power limit for this reason" ;
VAL_ 2565917438 PLedDueToUndefinedReason 3 "Not Available" 2 "Error" 1 "Power limited for this reason" 0 "No power limit for this reason" ;
VAL_ 2565917438 PLedDueToRateOfChangeLmt 3 "Not Available" 2 "Error" 1 "Frequency limited for this reason" 0 "No frequency limit for this reason" ;
VAL_ 2565917438 PLedDueToPwrETemp 3 "Not Available" 2 "Error" 1 "Frequency limited for this reason" 0 "No frequency limit for this reason" ;
VAL_ 2565917438 PLedDueToEFilterTemp 2 "Error" 1 "Frequency limited for this reason" 0 "No frequency limit for this reason" 3 "Not Available" ;
VAL_ 2565917438 PLedDueToCtrlTemp 3 "Not Available" 2 "Error" 1 "Power limited for this reason" 0 "No power limit for this reason" ;
VAL_ 2565917438 FreqCmdExceedsMax 3 "Not Available" 2 "Error" 1 "Frequency limited for this reason" 0 "No frequency limit for this reason" ;
VAL_ 2565917438 FreqCmdBelowMin 3 "Not Available" 2 "Error" 1 "Frequency limited for this reason" 0 "No frequency limit for this reason" ;
VAL_ 2565917438 PLedDueToDCSideVMin 3 "Not Available" 2 "Error" 1 "Power limited for this reason" 0 "No power limit for this reason" ;
VAL_ 2565917438 PLedDueToACSideRMSCur 3 "Not Available" 2 "Error" 1 "Power limited for this reason" 0 "No power limit for this reason" ;
VAL_ 2565917438 PLedDueToDCSideCur 3 "Not Available" 2 "Error" 1 "Power limited for this reason" 0 "No power limit for this reason" ;
VAL_ 2624519934 CommandedReceiveSPNSA 255 "The command in SPN 8840 applies to all valid source addresses" 254 "The command in SPN 8840 applies to all source addresses in which the Configurable ECU is currently configured to receive the SPN contained in SPN 8839." ;
VAL_ 2624519934 CommandedReceiveSPNReqSt 3 "Not Available" 2 "SAE Reserved" 1 "SPN reception shall be enabled for the source address identified in SPN 8841." 0 "SPN reception shall be disabled for the source address identified in SPN 8841." ;
VAL_ 2624519934 TransactionMode 15 "SAE Reserved" 14 "SAE Reserved" 13 "SAE Reserved" 12 "SAE Reserved" 11 "SAE Reserved" 10 "SAE Reserved" 9 "SAE Reserved" 8 "SAE Reserved" 7 "SAE Reserved" 6 "SAE Reserved" 5 "SAE Reserved" 4 "Partial Revert to Default" 3 "Global Revert to Default" 2 "Cancel Pending Changes" 1 "Configure Port Receive State" 0 "Request Port Receive Status" ;
VAL_ 2624519934 CommandedPort 15 "SAE Reserved" 14 "SAE Reserved" 13 "SAE Reserved" 12 "SAE Reserved" 11 "SAE Reserved" 10 "Port 10" 9 "Port 9" 8 "Port 8" 7 "Port 7" 6 "Port 6" 5 "Port 5" 4 "Port 4" 3 "Port 3" 2 "Port 2" 1 "Port 1" 0 "Current port" ;
VAL_ 2557345534 PlungerFiringOrder 15 "Don't Care / Take no action" 14 "Reserved" 13 "Reserved" 12 "Reserved" 11 "Reserved" 10 "Reserved" 9 "Reserved" 8 "Reserved" 7 "Reserved" 6 "Reserved" 5 "Reserved" 4 "Reserved" 3 "Reserved" 2 "Reserved" 1 "Firing order 1-5-2-3-4" 0 "Firing order 1-2-3" ;
VAL_ 2557214462 DisPressCalSetPointCmd 15 "Not Available" 14 "Error" 13 "Reserved" 12 "Reset Calibration" 11 "Correction Point" 10 "End Point" 9 "Calibration Reference Point 9" 8 "Calibration Reference Point 8" 7 "Calibration Reference Point 7" 6 "Calibration Reference Point 6" 5 "Calibration Reference Point 5" 4 "Calibration Reference Point 4" 3 "Calibration Reference Point 3" 2 "Calibration Reference Point 2" 1 "Calibration Reference Point 1" 0 "Zero Point" ;
VAL_ 2557214462 SuctionPressCalSetPointCmd 15 "Not Available" 14 "Error" 13 "Reserved" 12 "Reset Calibration" 11 "Correction Point" 10 "End Point" 9 "Calibration Reference Point 9" 8 "Calibration Reference Point 8" 7 "Calibration Reference Point 7" 6 "Calibration Reference Point 6" 5 "Calibration Reference Point 5" 4 "Calibration Reference Point 4" 3 "Calibration Reference Point 3" 2 "Calibration Reference Point 2" 1 "Calibration Reference Point 1" 0 "Zero Point" ;
VAL_ 2557148926 EngThrotSynchModeCurSetting 15 "Not available" 14 "Error" 13 "Reserved" 12 "Reserved" 11 "Reserved" 10 "Reserved" 9 "Reserved" 8 "Reserved" 7 "Reserved" 6 "Reserved" 5 "Reserved" 4 "Synchronized Master" 3 "Synchronized Starboard" 2 "Synchronized Port" 1 "Synchronized Center" 0 "Not Synchronized" ;
VAL_ 2557148926 OpStationLockout 3 "Not available" 2 "Error" 1 "Station Lockout Active" 0 "Station Lockout Inactive" ;
VAL_ 2557083390 EngThrotSynchModeCmd 15 "Not available/Take no action" 14 "Error" 13 "Reserved" 12 "Reserved" 11 "Reserved" 10 "Reserved" 9 "Reserved" 8 "Reserved" 7 "Reserved" 6 "Reserved" 5 "Reserved" 4 "Synchronized Master" 3 "Synchronized Starboard" 2 "Synchronized Port" 1 "Synchronized Center" 0 "Not Synchronized" ;
VAL_ 2633764094 CanisterVentVlv 3 "Not Available" 2 "Error" 1 "Vent Valve is Open" 0 "Vent Valve is Closed" ;
VAL_ 2566654462 SLIBatPack1Snsr1InitStatus 2 "Initialization process is complete." ;
VAL_ 2566653950 SLIBatPack1Snsr2InitStatus 2 "Initialization process is complete." ;
VAL_ 2566653438 SLIBatPack1Snsr3InitStatus 2 "Initialization process is complete." ;
VAL_ 2566652926 SLIBatPack1Snsr4InitStatus 2 "Initialization process is complete." ;
VAL_ 2566652670 AFT2DEFDosingSysFrozen 3 "Not available" 2 "Error" 1 "DEF system is frozen" 0 "DEF system is not frozen" ;
VAL_ 2566652670 AFT1DEFDosingSysFrozen 3 "Not available" 2 "Error" 1 "DEF system is frozen" 0 "DEF system is not frozen" ;
VAL_ 2566652414 Instance 15 "Not available / Instance not specified" 14 "Instance 15" 13 "Instance 14" 12 "Instance 13" 11 "Instance 12" 10 "Instance 11" 9 "Instance 10" 8 "Instance 9" 7 "Instance 8" 6 "Instance 7" 5 "Instance 6" 4 "Instance 5" 3 "Instance 4" 2 "Instance 3" 1 "Instance 2" 0 "Instance 1" ;
VAL_ 2566652414 OperatingStatus 3 "Not Available" 2 "Not Operable" 1 "Derated Operation" 0 "Normal Operation" ;
VAL_ 2566652414 ServiceInd 3 "Not Available" 2 "Reserved" 1 "Service Required" 0 "Service Not Required" ;
VAL_ 2566652414 CtrlCmdStatus 3 "Not Available" 2 "Default Command" 1 "External Command" 0 "Internal Command" ;
VAL_ 2566652414 CtrlStatusReasonCode 15 "Not Available" 14 "Reserved" 13 "Reserved" 12 "Reserved" 11 "Reserved" 10 "Reserved" 9 "Reserved" 8 "Speed limited due to over-temperature protection" 7 "Speed limited due to torque limit" 6 "Speed limited due to maximum system design capability" 5 "Speed Limited due to current" 4 "Over-Temperature Protection Shutdown" 3 "Under-Voltage Protection Shutdown" 2 "Over-Voltage Protection Shutdown" 1 "Unable to Start" 0 "Normal Operation" ;
VAL_ 2566652414 EnableStatus 3 "Not available" 2 "Accessory Motor On, Reverse Direction" 1 "Accessory Motor On, Normal" 0 "Accessory Motor Off" ;
VAL_ 2566651902 OperatingStatus 3 "Not Available" 2 "Not Operable" 1 "Derated Operation" 0 "Normal Operation" ;
VAL_ 2566651902 ServiceInd 3 "Not Available" 2 "Reserved" 1 "Service Required" 0 "Service Not Required" ;
VAL_ 2566651902 CtrlCmdStatus 3 "Not Available" 2 "Default Command" 1 "External Command" 0 "Internal Command" ;
VAL_ 2566651902 CtrlStatusReasonCode 15 "Not Available" 14 "Reserved" 13 "Reserved" 12 "Reserved" 11 "Reserved" 10 "Reserved" 9 "Reserved" 8 "Speed limited due to over-temperature protection" 7 "Speed limited due to torque limit" 6 "Speed limited due to maximum system design capability" 5 "Speed Limited due to current" 4 "Over-Temperature Protection Shutdown" 3 "Under-Voltage Protection Shutdown" 2 "Over-Voltage Protection Shutdown" 1 "Unable to Start" 0 "Normal Operation" ;
VAL_ 2566651902 EnableStatus 3 "Not available" 2 "Accessory Motor On, Reverse Direction" 1 "Accessory Motor On, Normal" 0 "Accessory Motor Off" ;
VAL_ 2566651646 OperatingStatus 3 "Not Available" 2 "Not Operable" 1 "Derated Operation" 0 "Normal Operation" ;
VAL_ 2566651646 ServiceInd 3 "Not Available" 2 "Reserved" 1 "Service Required" 0 "Service Not Required" ;
VAL_ 2566651646 CtrlCmdStatus 3 "Not Available" 2 "Default Command" 1 "External Command" 0 "Internal Command" ;
VAL_ 2566651646 CtrlStatusReasonCode 15 "Not Available" 14 "Reserved" 13 "Reserved" 12 "Reserved" 11 "Reserved" 10 "Reserved" 9 "Reserved" 8 "Speed limited due to over-temperature protection" 7 "Speed limited due to torque limit" 6 "Speed limited due to maximum system design capability" 5 "Speed Limited due to current" 4 "Over-Temperature Protection Shutdown" 3 "Under-Voltage Protection Shutdown" 2 "Over-Voltage Protection Shutdown" 1 "Unable to Start" 0 "Normal Operation" ;
VAL_ 2566651646 EnableStatus 3 "Not available" 2 "Accessory Motor On, Reverse Direction" 1 "Accessory Motor On, Normal" 0 "Accessory Motor Off" ;
VAL_ 2566651390 OperatingStatus 3 "Not Available" 2 "Not Operable" 1 "Derated Operation" 0 "Normal Operation" ;
VAL_ 2566651390 ServiceInd 3 "Not Available" 2 "Reserved" 1 "Service Required" 0 "Service Not Required" ;
VAL_ 2566651390 CtrlCmdStatus 3 "Not Available" 2 "Default Command" 1 "External Command" 0 "Internal Command" ;
VAL_ 2566651390 CtrlStatusReasonCode 15 "Not Available" 14 "Reserved" 13 "Reserved" 12 "Reserved" 11 "Reserved" 10 "Reserved" 9 "Reserved" 8 "Speed limited due to over-temperature protection" 7 "Speed limited due to torque limit" 6 "Speed limited due to maximum system design capability" 5 "Speed Limited due to current" 4 "Over-Temperature Protection Shutdown" 3 "Under-Voltage Protection Shutdown" 2 "Over-Voltage Protection Shutdown" 1 "Unable to Start" 0 "Normal Operation" ;
VAL_ 2566651390 EnableStatus 3 "Not available" 2 "Accessory Motor On, Reverse Direction" 1 "Accessory Motor On, Normal" 0 "Accessory Motor Off" ;
VAL_ 2566651134 OperatingStatus 3 "Not Available" 2 "Not Operable" 1 "Derated Operation" 0 "Normal Operation" ;
VAL_ 2566651134 ServiceInd 3 "Not Available" 2 "Reserved" 1 "Service Required" 0 "Service Not Required" ;
VAL_ 2566651134 CtrlCmdStatus 3 "Not Available" 2 "Default Command" 1 "External Command" 0 "Internal Command" ;
VAL_ 2566651134 CtrlStatusReasonCode 15 "Not Available" 14 "Reserved" 13 "Reserved" 12 "Reserved" 11 "Reserved" 10 "Reserved" 9 "Reserved" 8 "Speed limited due to over-temperature protection" 7 "Speed limited due to torque limit" 6 "Speed limited due to maximum system design capability" 5 "Speed Limited due to current" 4 "Over-Temperature Protection Shutdown" 3 "Under-Voltage Protection Shutdown" 2 "Over-Voltage Protection Shutdown" 1 "Unable to Start" 0 "Normal Operation" ;
VAL_ 2566651134 EnableStatus 3 "Not available" 2 "Accessory Motor On, Reverse Direction" 1 "Accessory Motor On, Normal" 0 "Accessory Motor Off" ;
VAL_ 2566650878 OperatingStatus 3 "Not Available" 2 "Not Operable" 1 "Derated Operation" 0 "Normal Operation" ;
VAL_ 2566650878 ServiceInd 3 "Not Available" 2 "Reserved" 1 "Service Required" 0 "Service Not Required" ;
VAL_ 2566650878 CtrlCmdStatus 3 "Not Available" 2 "Default Command" 1 "External Command" 0 "Internal Command" ;
VAL_ 2566650878 CtrlStatusReasonCode 15 "Not Available" 14 "Reserved" 13 "Reserved" 12 "Reserved" 11 "Reserved" 10 "Reserved" 9 "Reserved" 8 "Speed limited due to over-temperature protection" 7 "Speed limited due to torque limit" 6 "Speed limited due to maximum system design capability" 5 "Speed Limited due to current" 4 "Over-Temperature Protection Shutdown" 3 "Under-Voltage Protection Shutdown" 2 "Over-Voltage Protection Shutdown" 1 "Unable to Start" 0 "Normal Operation" ;
VAL_ 2566650878 EnableStatus 3 "Not available" 2 "Accessory Motor On, Reverse Direction" 1 "Accessory Motor On, Normal" 0 "Accessory Motor Off" ;
VAL_ 2566650622 OperatingStatus 3 "Not Available" 2 "Not Operable" 1 "Derated Operation" 0 "Normal Operation" ;
VAL_ 2566650622 ServiceInd 3 "Not Available" 2 "Reserved" 1 "Service Required" 0 "Service Not Required" ;
VAL_ 2566650622 CtrlCmdStatus 3 "Not Available" 2 "Default Command" 1 "External Command" 0 "Internal Command" ;
VAL_ 2566650622 CtrlStatusReasonCode 15 "Not Available" 14 "Reserved" 13 "Reserved" 12 "Reserved" 11 "Reserved" 10 "Reserved" 9 "Reserved" 8 "Speed limited due to over-temperature protection" 7 "Speed limited due to torque limit" 6 "Speed limited due to maximum system design capability" 5 "Speed Limited due to current" 4 "Over-Temperature Protection Shutdown" 3 "Under-Voltage Protection Shutdown" 2 "Over-Voltage Protection Shutdown" 1 "Unable to Start" 0 "Normal Operation" ;
VAL_ 2566650622 EnableStatus 3 "Not available" 2 "Accessory Motor On, Reverse Direction" 1 "Accessory Motor On, Normal" 0 "Accessory Motor Off" ;
VAL_ 2566650366 OperatingStatus 3 "Not Available" 2 "Not Operable" 1 "Derated Operation" 0 "Normal Operation" ;
VAL_ 2566650366 ServiceInd 3 "Not Available" 2 "Reserved" 1 "Service Required" 0 "Service Not Required" ;
VAL_ 2566650366 CtrlCmdStatus 3 "Not Available" 2 "Default Command" 1 "External Command" 0 "Internal Command" ;
VAL_ 2566650366 CtrlStatusReasonCode 15 "Not Available" 14 "Reserved" 13 "Reserved" 12 "Reserved" 11 "Reserved" 10 "Reserved" 9 "Reserved" 8 "Speed limited due to over-temperature protection" 7 "Speed limited due to torque limit" 6 "Speed limited due to maximum system design capability" 5 "Speed Limited due to current" 4 "Over-Temperature Protection Shutdown" 3 "Under-Voltage Protection Shutdown" 2 "Over-Voltage Protection Shutdown" 1 "Unable to Start" 0 "Normal Operation" ;
VAL_ 2566650366 EnableStatus 3 "Not available" 2 "Accessory Motor On, Reverse Direction" 1 "Accessory Motor On, Normal" 0 "Accessory Motor Off" ;
VAL_ 2566650110 OperatingStatus 3 "Not Available" 2 "Not Operable" 1 "Derated Operation" 0 "Normal Operation" ;
VAL_ 2566650110 ServiceInd 3 "Not Available" 2 "Reserved" 1 "Service Required" 0 "Service Not Required" ;
VAL_ 2566650110 CtrlCmdStatus 3 "Not Available" 2 "Default Command" 1 "External Command" 0 "Internal Command" ;
VAL_ 2566650110 CtrlStatusReasonCode 15 "Not Available" 14 "Reserved" 13 "Reserved" 12 "Reserved" 11 "Reserved" 10 "Reserved" 9 "Reserved" 8 "Speed limited due to over-temperature protection" 7 "Speed limited due to torque limit" 6 "Speed limited due to maximum system design capability" 5 "Speed Limited due to current" 4 "Over-Temperature Protection Shutdown" 3 "Under-Voltage Protection Shutdown" 2 "Over-Voltage Protection Shutdown" 1 "Unable to Start" 0 "Normal Operation" ;
VAL_ 2566650110 EnableStatus 3 "Not available" 2 "Accessory Motor On, Reverse Direction" 1 "Accessory Motor On, Normal" 0 "Accessory Motor Off" ;
VAL_ 2566649854 OperatingStatus 3 "Not Available" 2 "Not Operable" 1 "Derated Operation" 0 "Normal Operation" ;
VAL_ 2566649854 ServiceInd 3 "Not Available" 2 "Reserved" 1 "Service Required" 0 "Service Not Required" ;
VAL_ 2566649854 CtrlCmdStatus 3 "Not Available" 2 "Default Command" 1 "External Command" 0 "Internal Command" ;
VAL_ 2566649854 CtrlStatusReasonCode 15 "Not Available" 14 "Reserved" 13 "Reserved" 12 "Reserved" 11 "Reserved" 10 "Reserved" 9 "Reserved" 8 "Speed limited due to over-temperature protection" 7 "Speed limited due to torque limit" 6 "Speed limited due to maximum system design capability" 5 "Speed Limited due to current" 4 "Over-Temperature Protection Shutdown" 3 "Under-Voltage Protection Shutdown" 2 "Over-Voltage Protection Shutdown" 1 "Unable to Start" 0 "Normal Operation" ;
VAL_ 2566649854 EnableStatus 3 "Not available" 2 "Accessory Motor On, Reverse Direction" 1 "Accessory Motor On, Normal" 0 "Accessory Motor Off" ;
VAL_ 2566648318 MonitorETempStatus 3 "Not available" 2 "Reserved" 1 "Temperature is outside of limits" 0 "Acceptable temperature" ;
VAL_ 2566648318 MonitorSPEStatus 3 "Not available" 2 "Reserved" 1 "Fault in electronics" 0 "Electronics functioning normally" ;
VAL_ 2566648318 MonitorSensingElementStatus 3 "Not available" 2 "Reserved" 1 "Fault with sensing element" 0 "Sensing element OK" ;
VAL_ 2566648318 MonitorEnvironmentStatus 3 "Not available" 2 "Reserved" 1 "Excessive noise in signal" 0 "Acceptable environment" ;
